VERSION "PropulsionCAN"

NS_ :

BS_ :

BU_ :  BECM CDD EGSM ETC IHU TMCU XCU ZCUD

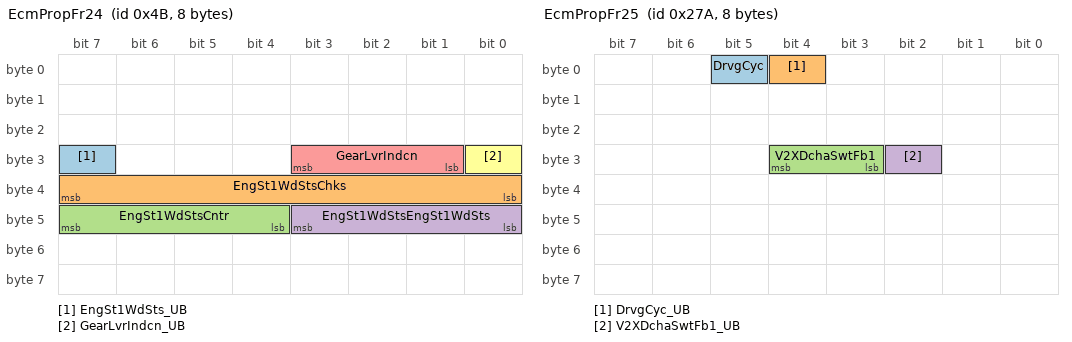
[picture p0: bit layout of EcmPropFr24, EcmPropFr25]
BO_ 75 EcmPropFr24 : 8 XCU
 SG_ EngSt1WdSts_UB : 31|1@0+ (1,0) [0|1] "" IHU,ZCUD
 SG_ EngSt1WdStsChks : 39|8@0+ (1.0,0.0) [0.0|255.0] "Unitless" IHU,ZCUD
 SG_ EngSt1WdStsCntr : 47|4@0+ (1.0,0.0) [0.0|15.0] "Unitless" IHU,ZCUD
 SG_ EngSt1WdStsEngSt1WdSts : 43|4@0+ (1,0) [0|15] "" IHU,ZCUD
 SG_ GearLvrIndcn : 27|3@0+ (1,0) [0|7] "" EGSM,IHU,ZCUD
 SG_ GearLvrIndcn_UB : 24|1@0+ (1,0) [0|1] "" EGSM,IHU,ZCUD

BO_ 634 EcmPropFr25 : 8 XCU
 SG_ DrvgCyc : 5|1@0+ (1,0) [0|1] "" CDD,IHU
 SG_ DrvgCyc_UB : 4|1@0+ (1,0) [0|1] "" CDD,IHU
 SG_ V2XDchaSwtFb1 : 28|2@0+ (1,0) [0|3] "" CDD,IHU
 SG_ V2XDchaSwtFb1_UB : 26|1@0+ (1,0) [0|1] "" CDD,IHU

BO_ 401 EcmPropFr28 : 8 XCU
 SG_ FrntHeatModEnad : 9|2@0+ (1,0) [0|3] "" IHU
 SG_ FrntHeatModEnad_UB : 12|1@0+ (1,0) [0|1] "" IHU

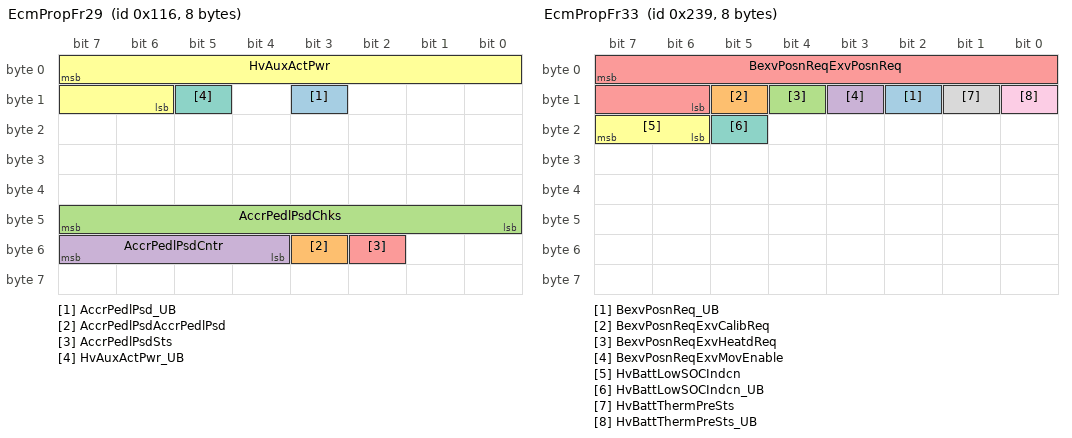
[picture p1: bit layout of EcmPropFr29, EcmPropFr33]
BO_ 278 EcmPropFr29 : 8 XCU
 SG_ AccrPedlPsd_UB : 11|1@0+ (1,0) [0|1] "" IHU,ZCUD
 SG_ AccrPedlPsdAccrPedlPsd : 51|1@0+ (1,0) [0|1] "" IHU,ZCUD
 SG_ AccrPedlPsdChks : 47|8@0+ (1.0,0.0) [0.0|255.0] "Unitless" IHU,ZCUD
 SG_ AccrPedlPsdCntr : 55|4@0+ (1.0,0.0) [0.0|15.0] "Unitless" IHU,ZCUD
 SG_ AccrPedlPsdSts : 50|1@0+ (1,0) [0|1] "" IHU,ZCUD
 SG_ HvAuxActPwr : 7|10@0+ (20.0,0.0) [0.0|20460.0] "W" IHU
 SG_ HvAuxActPwr_UB : 13|1@0+ (1,0) [0|1] "" IHU

BO_ 569 EcmPropFr33 : 8 XCU
 SG_ BexvPosnReq_UB : 10|1@0+ (1,0) [0|1] "" IHU,TMCU
 SG_ BexvPosnReqExvCalibReq : 13|1@0+ (1,0) [0|1] "" IHU,TMCU
 SG_ BexvPosnReqExvHeatdReq : 12|1@0+ (1,0) [0|1] "" IHU,TMCU
 SG_ BexvPosnReqExvMovEnable : 11|1@0+ (1,0) [0|1] "" IHU,TMCU
 SG_ BexvPosnReqExvPosnReq : 7|10@0+ (0.2,0.0) [0.0|100.0] "%" IHU,TMCU
 SG_ HvBattLowSOCIndcn : 23|2@0+ (1,0) [0|3] "" IHU
 SG_ HvBattLowSOCIndcn_UB : 21|1@0+ (1,0) [0|1] "" IHU
 SG_ HvBattThermPreSts : 9|1@0+ (1,0) [0|1] "" IHU
 SG_ HvBattThermPreSts_UB : 8|1@0+ (1,0) [0|1] "" IHU

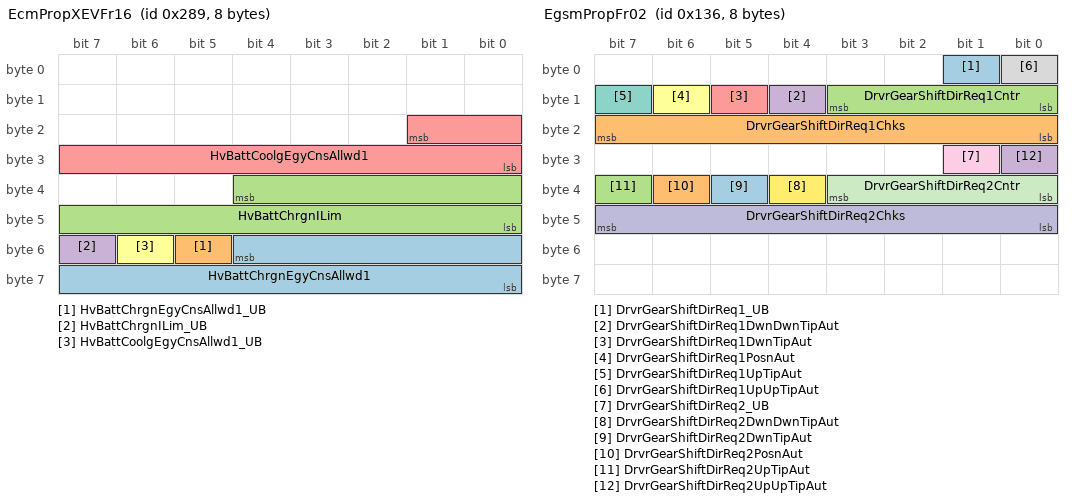
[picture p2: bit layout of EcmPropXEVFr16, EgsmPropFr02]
BO_ 649 EcmPropXEVFr16 : 8 XCU
 SG_ HvBattChrgnEgyCnsAllwd1 : 52|13@0+ (20.0,0.0) [0.0|163820.0] "Wh" IHU
 SG_ HvBattChrgnEgyCnsAllwd1_UB : 53|1@0+ (1,0) [0|1] "" IHU
 SG_ HvBattChrgnILim : 36|13@0+ (0.1,0.0) [0.0|819.1] "A" CDD
 SG_ HvBattChrgnILim_UB : 55|1@0+ (1,0) [0|1] "" CDD
 SG_ HvBattCoolgEgyCnsAllwd1 : 17|10@0+ (20.0,0.0) [0.0|20460.0] "Wh" IHU
 SG_ HvBattCoolgEgyCnsAllwd1_UB : 54|1@0+ (1,0) [0|1] "" IHU

BO_ 309 EgsmPropFr01 : 8 EGSM
 SG_ DrvrGearShiftManReq_UB : 7|1@0+ (1,0) [0|1] "" XCU
 SG_ DrvrGearShiftManReqDwnDwnTipReq : 0|1@0+ (1,0) [0|1] "" XCU
 SG_ DrvrGearShiftManReqDwnTipReq : 1|1@0+ (1,0) [0|1] "" XCU
 SG_ DrvrGearShiftManReqSteerWhlDwnReq1 : 2|1@0+ (1,0) [0|1] "" XCU
 SG_ DrvrGearShiftManReqSteerWhlUpReq : 3|1@0+ (1,0) [0|1] "" XCU
 SG_ DrvrGearShiftManReqTipReq1 : 4|1@0+ (1,0) [0|1] "" XCU
 SG_ DrvrGearShiftManReqUpTipReq1 : 5|1@0+ (1,0) [0|1] "" XCU
 SG_ DrvrGearShiftManReqUpUpTipReq : 6|1@0+ (1,0) [0|1] "" XCU
 SG_ DrvrGearShiftParkReq_UB : 15|1@0+ (1,0) [0|1] "" IHU,XCU,ZCUD
 SG_ DrvrGearShiftParkReq1 : 14|1@0+ (1,0) [0|1] "" IHU,XCU,ZCUD
 SG_ DrvrGearShiftParkReqChks : 23|8@0+ (1.0,0.0) [0.0|255.0] "Unitless" IHU,XCU,ZCUD
 SG_ DrvrGearShiftParkReqCntr : 11|4@0+ (1.0,0.0) [0.0|15.0] "Unitless" IHU,XCU,ZCUD
 SG_ DrvrGearShiftParkReqSts : 13|2@0+ (1,0) [0|3] "" IHU,XCU,ZCUD
 SG_ GearLock : 28|1@0+ (1,0) [0|1] "" IHU
 SG_ GearLock_UB : 29|1@0+ (1,0) [0|1] "" IHU
 SG_ GearShiftUnitSts : 26|3@0+ (1,0) [0|7] "" IHU,XCU,ZCUD
 SG_ GearShiftUnitSts_UB : 27|1@0+ (1,0) [0|1] "" IHU,XCU,ZCUD

BO_ 310 EgsmPropFr02 : 8 EGSM
 SG_ DrvrGearShiftDirReq1_UB : 1|1@0+ (1,0) [0|1] "" IHU,XCU,ZCUD
 SG_ DrvrGearShiftDirReq1Chks : 23|8@0+ (1.0,0.0) [0.0|255.0] "Unitless" IHU,XCU,ZCUD
 SG_ DrvrGearShiftDirReq1Cntr : 11|4@0+ (1.0,0.0) [0.0|15.0] "Unitless" IHU,XCU,ZCUD
 SG_ DrvrGearShiftDirReq1DwnDwnTipAut : 12|1@0+ (1,0) [0|1] "" IHU,XCU,ZCUD
 SG_ DrvrGearShiftDirReq1DwnTipAut : 13|1@0+ (1,0) [0|1] "" IHU,XCU,ZCUD
 SG_ DrvrGearShiftDirReq1PosnAut : 14|1@0+ (1,0) [0|1] "" IHU,XCU,ZCUD
 SG_ DrvrGearShiftDirReq1UpTipAut : 15|1@0+ (1,0) [0|1] "" IHU,XCU,ZCUD
 SG_ DrvrGearShiftDirReq1UpUpTipAut : 0|1@0+ (1,0) [0|1] "" IHU,XCU,ZCUD
 SG_ DrvrGearShiftDirReq2_UB : 25|1@0+ (1,0) [0|1] "" IHU,XCU,ZCUD
 SG_ DrvrGearShiftDirReq2Chks : 47|8@0+ (1.0,0.0) [0.0|255.0] "Unitless" IHU,XCU,ZCUD
 SG_ DrvrGearShiftDirReq2Cntr : 35|4@0+ (1.0,0.0) [0.0|15.0] "Unitless" IHU,XCU,ZCUD
 SG_ DrvrGearShiftDirReq2DwnDwnTipAut : 36|1@0+ (1,0) [0|1] "" IHU,XCU,ZCUD
 SG_ DrvrGearShiftDirReq2DwnTipAut : 37|1@0+ (1,0) [0|1] "" IHU,XCU,ZCUD
 SG_ DrvrGearShiftDirReq2PosnAut : 38|1@0+ (1,0) [0|1] "" IHU,XCU,ZCUD
 SG_ DrvrGearShiftDirReq2UpTipAut : 39|1@0+ (1,0) [0|1] "" IHU,XCU,ZCUD
 SG_ DrvrGearShiftDirReq2UpUpTipAut : 24|1@0+ (1,0) [0|1] "" IHU,XCU,ZCUD

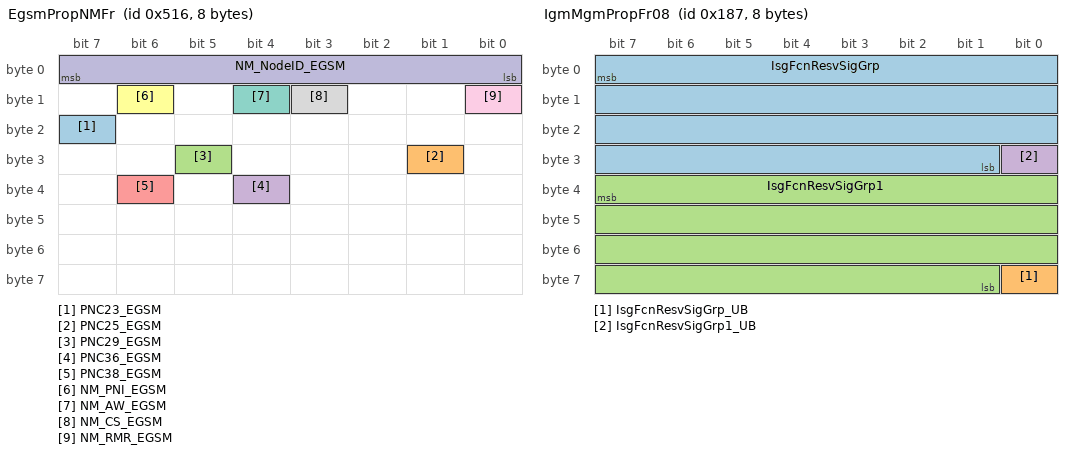
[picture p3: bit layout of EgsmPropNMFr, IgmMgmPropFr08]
BO_ 1302 EgsmPropNMFr : 8 EGSM
 SG_ PNC23_EGSM : 23|1@0+ (1,0) [0|0] "" Vector__XXX
 SG_ PNC25_EGSM : 25|1@0+ (1,0) [0|0] "" Vector__XXX
 SG_ PNC29_EGSM : 29|1@0+ (1,0) [0|0] "" Vector__XXX
 SG_ PNC36_EGSM : 36|1@0+ (1,0) [0|0] "" Vector__XXX
 SG_ PNC38_EGSM : 38|1@0+ (1,0) [0|0] "" Vector__XXX
 SG_ NM_PNI_EGSM : 14|1@0+ (1,0) [0|0] "" Vector__XXX
 SG_ NM_AW_EGSM : 12|1@0+ (1,0) [0|0] "" Vector__XXX
 SG_ NM_CS_EGSM : 11|1@0+ (1,0) [0|0] "" Vector__XXX
 SG_ NM_RMR_EGSM : 8|1@0+ (1,0) [0|0] "" Vector__XXX
 SG_ NM_NodeID_EGSM : 7|8@0+ (1,0) [0|0] "" Vector__XXX

BO_ 1366 EgsmPropVFCVectorFr : 8 EGSM
 SG_ VFCVectorEGSMBlockID : 1|2@0+ (1.0,0.0) [0.0|3.0] "Unitless" IHU
 SG_ VFCVectorEGSMVFCid0 : 2|1@0+ (1,0) [0|1] "" IHU
 SG_ VFCVectorEGSMVFCid1 : 3|1@0+ (1,0) [0|1] "" IHU
 SG_ VFCVectorEGSMVFCid10 : 12|1@0+ (1,0) [0|1] "" IHU
 SG_ VFCVectorEGSMVFCid11 : 13|1@0+ (1,0) [0|1] "" IHU
 SG_ VFCVectorEGSMVFCid12 : 14|1@0+ (1,0) [0|1] "" IHU
 SG_ VFCVectorEGSMVFCid13 : 15|1@0+ (1,0) [0|1] "" IHU
 SG_ VFCVectorEGSMVFCid14 : 16|1@0+ (1,0) [0|1] "" IHU
 SG_ VFCVectorEGSMVFCid15 : 17|1@0+ (1,0) [0|1] "" IHU
 SG_ VFCVectorEGSMVFCid16 : 18|1@0+ (1,0) [0|1] "" IHU
 SG_ VFCVectorEGSMVFCid17 : 19|1@0+ (1,0) [0|1] "" IHU
 SG_ VFCVectorEGSMVFCid18 : 20|1@0+ (1,0) [0|1] "" IHU
 SG_ VFCVectorEGSMVFCid19 : 21|1@0+ (1,0) [0|1] "" IHU
 SG_ VFCVectorEGSMVFCid2 : 4|1@0+ (1,0) [0|1] "" IHU
 SG_ VFCVectorEGSMVFCid20 : 22|1@0+ (1,0) [0|1] "" IHU
 SG_ VFCVectorEGSMVFCid21 : 23|1@0+ (1,0) [0|1] "" IHU
 SG_ VFCVectorEGSMVFCid22 : 24|1@0+ (1,0) [0|1] "" IHU
 SG_ VFCVectorEGSMVFCid23 : 25|1@0+ (1,0) [0|1] "" IHU
 SG_ VFCVectorEGSMVFCid24 : 26|1@0+ (1,0) [0|1] "" IHU
 SG_ VFCVectorEGSMVFCid25 : 27|1@0+ (1,0) [0|1] "" IHU
 SG_ VFCVectorEGSMVFCid26 : 28|1@0+ (1,0) [0|1] "" IHU
 SG_ VFCVectorEGSMVFCid27 : 29|1@0+ (1,0) [0|1] "" IHU
 SG_ VFCVectorEGSMVFCid28 : 30|1@0+ (1,0) [0|1] "" IHU
 SG_ VFCVectorEGSMVFCid29 : 31|1@0+ (1,0) [0|1] "" IHU
 SG_ VFCVectorEGSMVFCid3 : 5|1@0+ (1,0) [0|1] "" IHU
 SG_ VFCVectorEGSMVFCid30 : 32|1@0+ (1,0) [0|1] "" IHU
 SG_ VFCVectorEGSMVFCid31 : 33|1@0+ (1,0) [0|1] "" IHU
 SG_ VFCVectorEGSMVFCid32 : 34|1@0+ (1,0) [0|1] "" IHU
 SG_ VFCVectorEGSMVFCid33 : 35|1@0+ (1,0) [0|1] "" IHU
 SG_ VFCVectorEGSMVFCid34 : 36|1@0+ (1,0) [0|1] "" IHU
 SG_ VFCVectorEGSMVFCid35 : 37|1@0+ (1,0) [0|1] "" IHU
 SG_ VFCVectorEGSMVFCid36 : 38|1@0+ (1,0) [0|1] "" IHU
 SG_ VFCVectorEGSMVFCid37 : 39|1@0+ (1,0) [0|1] "" IHU
 SG_ VFCVectorEGSMVFCid38 : 40|1@0+ (1,0) [0|1] "" IHU
 SG_ VFCVectorEGSMVFCid39 : 41|1@0+ (1,0) [0|1] "" IHU
 SG_ VFCVectorEGSMVFCid4 : 6|1@0+ (1,0) [0|1] "" IHU
 SG_ VFCVectorEGSMVFCid40 : 42|1@0+ (1,0) [0|1] "" IHU
 SG_ VFCVectorEGSMVFCid41 : 43|1@0+ (1,0) [0|1] "" IHU
 SG_ VFCVectorEGSMVFCid42 : 44|1@0+ (1,0) [0|1] "" IHU
 SG_ VFCVectorEGSMVFCid43 : 45|1@0+ (1,0) [0|1] "" IHU
 SG_ VFCVectorEGSMVFCid44 : 46|1@0+ (1,0) [0|1] "" IHU
 SG_ VFCVectorEGSMVFCid45 : 47|1@0+ (1,0) [0|1] "" IHU
 SG_ VFCVectorEGSMVFCid46 : 48|1@0+ (1,0) [0|1] "" IHU
 SG_ VFCVectorEGSMVFCid47 : 49|1@0+ (1,0) [0|1] "" IHU
 SG_ VFCVectorEGSMVFCid48 : 50|1@0+ (1,0) [0|1] "" IHU
 SG_ VFCVectorEGSMVFCid49 : 51|1@0+ (1,0) [0|1] "" IHU
 SG_ VFCVectorEGSMVFCid5 : 7|1@0+ (1,0) [0|1] "" IHU
 SG_ VFCVectorEGSMVFCid50 : 52|1@0+ (1,0) [0|1] "" IHU
 SG_ VFCVectorEGSMVFCid51 : 53|1@0+ (1,0) [0|1] "" IHU
 SG_ VFCVectorEGSMVFCid52 : 54|1@0+ (1,0) [0|1] "" IHU
 SG_ VFCVectorEGSMVFCid53 : 55|1@0+ (1,0) [0|1] "" IHU
 SG_ VFCVectorEGSMVFCid54 : 56|1@0+ (1,0) [0|1] "" IHU
 SG_ VFCVectorEGSMVFCid55 : 57|1@0+ (1,0) [0|1] "" IHU
 SG_ VFCVectorEGSMVFCid56 : 58|1@0+ (1,0) [0|1] "" IHU
 SG_ VFCVectorEGSMVFCid57 : 59|1@0+ (1,0) [0|1] "" IHU
 SG_ VFCVectorEGSMVFCid58 : 60|1@0+ (1,0) [0|1] "" IHU
 SG_ VFCVectorEGSMVFCid59 : 61|1@0+ (1,0) [0|1] "" IHU
 SG_ VFCVectorEGSMVFCid6 : 8|1@0+ (1,0) [0|1] "" IHU
 SG_ VFCVectorEGSMVFCid60 : 62|1@0+ (1,0) [0|1] "" IHU
 SG_ VFCVectorEGSMVFCid61 : 63|1@0+ (1,0) [0|1] "" IHU
 SG_ VFCVectorEGSMVFCid7 : 9|1@0+ (1,0) [0|1] "" IHU
 SG_ VFCVectorEGSMVFCid8 : 10|1@0+ (1,0) [0|1] "" IHU
 SG_ VFCVectorEGSMVFCid9 : 11|1@0+ (1,0) [0|1] "" IHU

BO_ 1587 EgsmToVddmPropDiagResFrame : 8 EGSM

BO_ 1410 EtctoCddXCPFr01 : 8 ETC

BO_ 1448 ETCtoDEMXCPFr01 : 8 ETC

BO_ 1447 ETCtoDEMXCPFr02 : 8 ETC

BO_ 1449 ETCtoDEMXCPFr03 : 8 ETC

BO_ 1450 ETCtoDEMXCPFr04 : 8 ETC

BO_ 1451 ETCtoDEMXCPFr05 : 8 ETC

BO_ 1452 ETCtoDEMXCPFr06 : 8 ETC

BO_ 1412 EtctoEcmXCPFr01 : 8 ETC

BO_ 1418 EtctoIgsmXCPFr01 : 8 ETC

BO_ 314 IgmMgmPropFr03 : 8 XCU
 SG_ IsgCooltT : 47|8@0+ (1.0,-40.0) [-40.0|215.0] "degC" IHU
 SG_ IsgCooltT_UB : 55|1@0+ (1,0) [0|1] "" IHU

BO_ 342 IgmMgmPropFr05 : 8 XCU
 SG_ IsgUDc : 2|11@0+ (0.25,0.0) [0.0|511.0] "Volt" IHU
 SG_ IsgUDc_UB : 3|1@0+ (1,0) [0|1] "" IHU

BO_ 149 IgmMgmPropFr06 : 8 XCU
 SG_ IsgModSts : 38|4@0+ (1,0) [0|15] "" IHU
 SG_ IsgModSts_UB : 39|1@0+ (1,0) [0|1] "" IHU

BO_ 391 IgmMgmPropFr08 : 8 XCU
 SG_ IsgFcnResvSigGrp : 7|31@0+ (1.0,0.0) [0.0|9223372036854776000.0] "Unitless" CDD
 SG_ IsgFcnResvSigGrp_UB : 56|1@0+ (1,0) [0|1] "" CDD
 SG_ IsgFcnResvSigGrp1 : 39|31@0+ (1.0,0.0) [0.0|9223372036854776000.0] "Unitless" CDD
 SG_ IsgFcnResvSigGrp1_UB : 24|1@0+ (1,0) [0|1] "" CDD

BO_ 593 IhuPropFr01 : 8 IHU
 SG_ HmiSteerWhlHeatLvlReq : 7|3@0+ (1,0) [0|7] "" ZCUD
 SG_ HmiSteerWhlHeatLvlReq_UB : 4|1@0+ (1,0) [0|1] "" ZCUD

BO_ 299 MgmPropdTCFr09 : 8 XCU
 SG_ LimdPwrPerc : 55|11@0- (0.1,0.0) [-100.0|102.30000000000001] "%" IHU
 SG_ LimdPwrPerc_UB : 57|1@0+ (1,0) [0|1] "" IHU

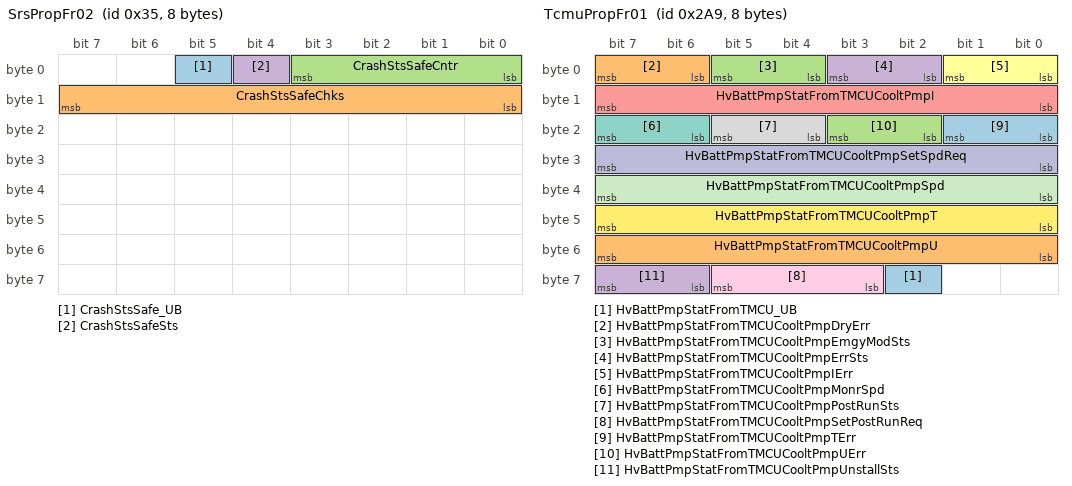
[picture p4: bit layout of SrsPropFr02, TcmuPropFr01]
BO_ 53 SrsPropFr02 : 8 ZCUD
 SG_ CrashStsSafe_UB : 5|1@0+ (1,0) [0|1] "" CDD,IHU,XCU
 SG_ CrashStsSafeChks : 15|8@0+ (1.0,0.0) [0.0|255.0] "Unitless" CDD,IHU,XCU
 SG_ CrashStsSafeCntr : 3|4@0+ (1.0,0.0) [0.0|15.0] "Unitless" CDD,IHU,XCU
 SG_ CrashStsSafeSts : 4|1@0+ (1,0) [0|1] "" CDD,IHU,XCU

BO_ 681 TcmuPropFr01 : 8 TMCU
 SG_ HvBattPmpStatFromTMCU_UB : 58|1@0+ (1,0) [0|1] "" XCU
 SG_ HvBattPmpStatFromTMCUCooltPmpDryErr : 7|2@0+ (1,0) [0|3] "" XCU
 SG_ HvBattPmpStatFromTMCUCooltPmpEmgyModSts : 5|2@0+ (1,0) [0|3] "" XCU
 SG_ HvBattPmpStatFromTMCUCooltPmpErrSts : 3|2@0+ (1,0) [0|3] "" XCU
 SG_ HvBattPmpStatFromTMCUCooltPmpI : 15|8@0+ (0.2,0.0) [0.0|50.800000000000004] "A" XCU
 SG_ HvBattPmpStatFromTMCUCooltPmpIErr : 1|2@0+ (1,0) [0|3] "" XCU
 SG_ HvBattPmpStatFromTMCUCooltPmpMonrSpd : 23|2@0+ (1,0) [0|3] "" XCU
 SG_ HvBattPmpStatFromTMCUCooltPmpPostRunSts : 21|2@0+ (1,0) [0|3] "" XCU
 SG_ HvBattPmpStatFromTMCUCooltPmpSetPostRunReq : 61|3@0+ (1,0) [0|7] "" XCU
 SG_ HvBattPmpStatFromTMCUCooltPmpSetSpdReq : 31|8@0+ (1.0,0.0) [0.0|254.0] "Unitless" XCU
 SG_ HvBattPmpStatFromTMCUCooltPmpSpd : 39|8@0+ (1.0,0.0) [0.0|254.0] "Unitless" XCU
 SG_ HvBattPmpStatFromTMCUCooltPmpT : 47|8@0+ (1.0,-50.0) [-50.0|200.0] "degC" XCU
 SG_ HvBattPmpStatFromTMCUCooltPmpTErr : 17|2@0+ (1,0) [0|3] "" XCU
 SG_ HvBattPmpStatFromTMCUCooltPmpU : 55|8@0+ (0.1,0.0) [0.0|25.0] "Volt" XCU
 SG_ HvBattPmpStatFromTMCUCooltPmpUErr : 19|2@0+ (1,0) [0|3] "" XCU
 SG_ HvBattPmpStatFromTMCUCooltPmpUnstallSts : 63|2@0+ (1,0) [0|3] "" XCU

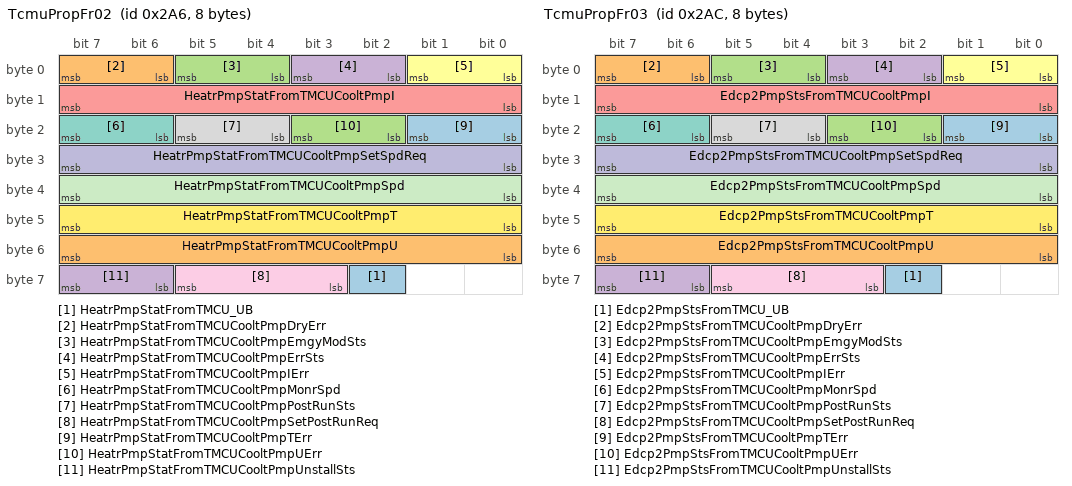
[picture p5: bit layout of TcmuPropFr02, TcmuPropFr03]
BO_ 678 TcmuPropFr02 : 8 TMCU
 SG_ HeatrPmpStatFromTMCU_UB : 58|1@0+ (1,0) [0|1] "" XCU
 SG_ HeatrPmpStatFromTMCUCooltPmpDryErr : 7|2@0+ (1,0) [0|3] "" XCU
 SG_ HeatrPmpStatFromTMCUCooltPmpEmgyModSts : 5|2@0+ (1,0) [0|3] "" XCU
 SG_ HeatrPmpStatFromTMCUCooltPmpErrSts : 3|2@0+ (1,0) [0|3] "" XCU
 SG_ HeatrPmpStatFromTMCUCooltPmpI : 15|8@0+ (0.2,0.0) [0.0|50.800000000000004] "A" XCU
 SG_ HeatrPmpStatFromTMCUCooltPmpIErr : 1|2@0+ (1,0) [0|3] "" XCU
 SG_ HeatrPmpStatFromTMCUCooltPmpMonrSpd : 23|2@0+ (1,0) [0|3] "" XCU
 SG_ HeatrPmpStatFromTMCUCooltPmpPostRunSts : 21|2@0+ (1,0) [0|3] "" XCU
 SG_ HeatrPmpStatFromTMCUCooltPmpSetPostRunReq : 61|3@0+ (1,0) [0|7] "" XCU
 SG_ HeatrPmpStatFromTMCUCooltPmpSetSpdReq : 31|8@0+ (1.0,0.0) [0.0|254.0] "Unitless" XCU
 SG_ HeatrPmpStatFromTMCUCooltPmpSpd : 39|8@0+ (1.0,0.0) [0.0|254.0] "Unitless" XCU
 SG_ HeatrPmpStatFromTMCUCooltPmpT : 47|8@0+ (1.0,-50.0) [-50.0|200.0] "degC" XCU
 SG_ HeatrPmpStatFromTMCUCooltPmpTErr : 17|2@0+ (1,0) [0|3] "" XCU
 SG_ HeatrPmpStatFromTMCUCooltPmpU : 55|8@0+ (0.1,0.0) [0.0|25.0] "Volt" XCU
 SG_ HeatrPmpStatFromTMCUCooltPmpUErr : 19|2@0+ (1,0) [0|3] "" XCU
 SG_ HeatrPmpStatFromTMCUCooltPmpUnstallSts : 63|2@0+ (1,0) [0|3] "" XCU

BO_ 684 TcmuPropFr03 : 8 TMCU
 SG_ Edcp2PmpStsFromTMCU_UB : 58|1@0+ (1,0) [0|1] "" XCU
 SG_ Edcp2PmpStsFromTMCUCooltPmpDryErr : 7|2@0+ (1,0) [0|3] "" XCU
 SG_ Edcp2PmpStsFromTMCUCooltPmpEmgyModSts : 5|2@0+ (1,0) [0|3] "" XCU
 SG_ Edcp2PmpStsFromTMCUCooltPmpErrSts : 3|2@0+ (1,0) [0|3] "" XCU
 SG_ Edcp2PmpStsFromTMCUCooltPmpI : 15|8@0+ (0.2,0.0) [0.0|50.800000000000004] "A" XCU
 SG_ Edcp2PmpStsFromTMCUCooltPmpIErr : 1|2@0+ (1,0) [0|3] "" XCU
 SG_ Edcp2PmpStsFromTMCUCooltPmpMonrSpd : 23|2@0+ (1,0) [0|3] "" XCU
 SG_ Edcp2PmpStsFromTMCUCooltPmpPostRunSts : 21|2@0+ (1,0) [0|3] "" XCU
 SG_ Edcp2PmpStsFromTMCUCooltPmpSetPostRunReq : 61|3@0+ (1,0) [0|7] "" XCU
 SG_ Edcp2PmpStsFromTMCUCooltPmpSetSpdReq : 31|8@0+ (1.0,0.0) [0.0|254.0] "Unitless" XCU
 SG_ Edcp2PmpStsFromTMCUCooltPmpSpd : 39|8@0+ (1.0,0.0) [0.0|254.0] "Unitless" XCU
 SG_ Edcp2PmpStsFromTMCUCooltPmpT : 47|8@0+ (1.0,-50.0) [-50.0|200.0] "degC" XCU
 SG_ Edcp2PmpStsFromTMCUCooltPmpTErr : 17|2@0+ (1,0) [0|3] "" XCU
 SG_ Edcp2PmpStsFromTMCUCooltPmpU : 55|8@0+ (0.1,0.0) [0.0|25.0] "Volt" XCU
 SG_ Edcp2PmpStsFromTMCUCooltPmpUErr : 19|2@0+ (1,0) [0|3] "" XCU
 SG_ Edcp2PmpStsFromTMCUCooltPmpUnstallSts : 63|2@0+ (1,0) [0|3] "" XCU

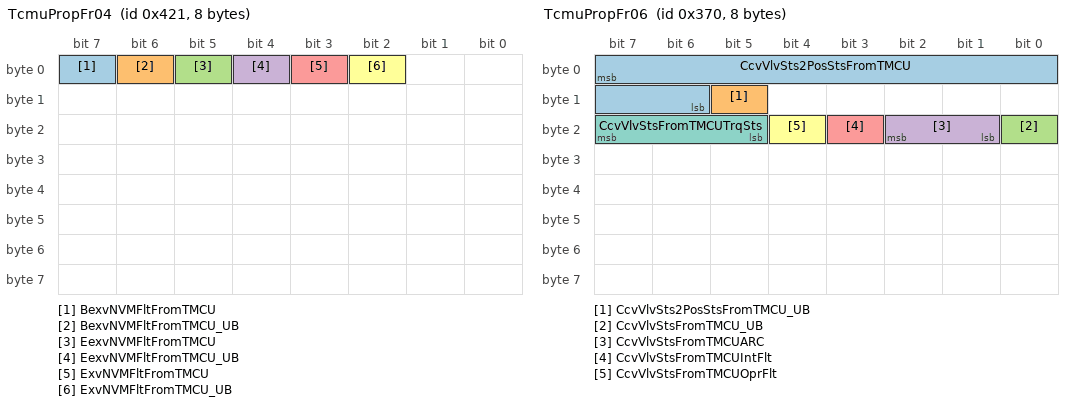
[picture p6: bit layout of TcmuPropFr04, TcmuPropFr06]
BO_ 1057 TcmuPropFr04 : 8 TMCU
 SG_ BexvNVMFltFromTMCU : 7|1@0+ (1,0) [0|1] "" XCU
 SG_ BexvNVMFltFromTMCU_UB : 6|1@0+ (1,0) [0|1] "" XCU
 SG_ EexvNVMFltFromTMCU : 5|1@0+ (1,0) [0|1] "" XCU
 SG_ EexvNVMFltFromTMCU_UB : 4|1@0+ (1,0) [0|1] "" XCU
 SG_ ExvNVMFltFromTMCU : 3|1@0+ (1,0) [0|1] "" XCU
 SG_ ExvNVMFltFromTMCU_UB : 2|1@0+ (1,0) [0|1] "" XCU

BO_ 869 TcmuPropFr05 : 8 TMCU
 SG_ CcvmStsFromTMCU_UB : 25|1@0+ (1,0) [0|1] "" XCU
 SG_ CcvmStsFromTMCUVlvBlkFlt : 7|1@0+ (1,0) [0|1] "" XCU
 SG_ CcvmStsFromTMCUVlvCalibSts : 6|2@0+ (1,0) [0|3] "" XCU
 SG_ CcvmStsFromTMCUVlvCmdPosnErr : 4|1@0+ (1,0) [0|1] "" XCU
 SG_ CcvmStsFromTMCUVlvLoTErr : 3|1@0+ (1,0) [0|1] "" XCU
 SG_ CcvmStsFromTMCUVlvMoveSts : 2|1@0+ (1,0) [0|1] "" XCU
 SG_ CcvmStsFromTMCUVlvNVMFlt : 1|1@0+ (1,0) [0|1] "" XCU
 SG_ CcvmStsFromTMCUVlvOpenCircFlt : 0|1@0+ (1,0) [0|1] "" XCU
 SG_ CcvmStsFromTMCUVlvOverTErr : 15|1@0+ (1,0) [0|1] "" XCU
 SG_ CcvmStsFromTMCUVlvOverTrvlFlt : 14|1@0+ (1,0) [0|1] "" XCU
 SG_ CcvmStsFromTMCUVlvOverTWarn : 13|1@0+ (1,0) [0|1] "" XCU
 SG_ CcvmStsFromTMCUVlvOverUErr : 12|1@0+ (1,0) [0|1] "" XCU
 SG_ CcvmStsFromTMCUVlvPosn : 9|10@0+ (0.1,0.0) [0.0|100.0] "%" XCU
 SG_ CcvmStsFromTMCUVlvPosnCtrlTimeOutFlt : 11|1@0+ (1,0) [0|1] "" XCU
 SG_ CcvmStsFromTMCUVlvPosnUkwnFlt : 10|1@0+ (1,0) [0|1] "" XCU
 SG_ CcvmStsFromTMCUVlvPreHeatgSts : 31|1@0+ (1,0) [0|1] "" XCU
 SG_ CcvmStsFromTMCUVlvSelfLearnFlt : 30|1@0+ (1,0) [0|1] "" XCU
 SG_ CcvmStsFromTMCUVlvShoCircFlt : 29|1@0+ (1,0) [0|1] "" XCU
 SG_ CcvmStsFromTMCUVlvSpdLvlSts : 28|2@0+ (1,0) [0|3] "" XCU
 SG_ CcvmStsFromTMCUVlvUnderUErr : 26|1@0+ (1,0) [0|1] "" XCU

BO_ 880 TcmuPropFr06 : 8 TMCU
 SG_ CcvVlvSts2PosStsFromTMCU : 7|10@0+ (0.26367188,-45.0) [-45.0|224.73633324000002] "Unitless" XCU
 SG_ CcvVlvSts2PosStsFromTMCU_UB : 13|1@0+ (1,0) [0|1] "" XCU
 SG_ CcvVlvStsFromTMCU_UB : 16|1@0+ (1,0) [0|1] "" XCU
 SG_ CcvVlvStsFromTMCUARC : 18|2@0+ (1.0,0.0) [0.0|3.0] "Unitless" XCU
 SG_ CcvVlvStsFromTMCUIntFlt : 19|1@0+ (1,0) [0|1] "" XCU
 SG_ CcvVlvStsFromTMCUOprFlt : 20|1@0+ (1,0) [0|1] "" XCU
 SG_ CcvVlvStsFromTMCUTrqSts : 23|3@0+ (1,0) [0|7] "" XCU

BO_ 672 TcmuPropFr07 : 8 TMCU
 SG_ BexvStsFromTMCU_UB : 17|1@0+ (1,0) [0|1] "" XCU
 SG_ BexvStsFromTMCUExvActrPosn : 7|10@0+ (0.2,0.0) [0.0|100.0] "%" XCU
 SG_ BexvStsFromTMCUExvBlkErr : 13|1@0+ (1,0) [0|1] "" XCU
 SG_ BexvStsFromTMCUExvCalibSts : 12|2@0+ (1,0) [0|3] "" XCU
 SG_ BexvStsFromTMCUExvElecStsErr : 10|3@0+ (1,0) [0|7] "" XCU
 SG_ BexvStsFromTMCUExvMovSts : 23|1@0+ (1,0) [0|1] "" XCU
 SG_ BexvStsFromTMCUExvOvrTempErr : 22|1@0+ (1,0) [0|1] "" XCU
 SG_ BexvStsFromTMCUExvOvrTrvlErr : 21|1@0+ (1,0) [0|1] "" XCU
 SG_ BexvStsFromTMCUExvPreHeatgSts : 20|1@0+ (1,0) [0|1] "" XCU
 SG_ BexvStsFromTMCUExvVoltgRangErr : 19|2@0+ (1,0) [0|3] "" XCU
 SG_ EexvStsFromTMCU_UB : 41|1@0+ (1,0) [0|1] "" XCU
 SG_ EexvStsFromTMCUExvActrPosn : 31|10@0+ (0.2,0.0) [0.0|100.0] "%" XCU
 SG_ EexvStsFromTMCUExvBlkErr : 37|1@0+ (1,0) [0|1] "" XCU
 SG_ EexvStsFromTMCUExvCalibSts : 36|2@0+ (1,0) [0|3] "" XCU
 SG_ EexvStsFromTMCUExvElecStsErr : 34|3@0+ (1,0) [0|7] "" XCU
 SG_ EexvStsFromTMCUExvMovSts : 47|1@0+ (1,0) [0|1] "" XCU
 SG_ EexvStsFromTMCUExvOvrTempErr : 46|1@0+ (1,0) [0|1] "" XCU
 SG_ EexvStsFromTMCUExvOvrTrvlErr : 45|1@0+ (1,0) [0|1] "" XCU
 SG_ EexvStsFromTMCUExvPreHeatgSts : 44|1@0+ (1,0) [0|1] "" XCU
 SG_ EexvStsFromTMCUExvVoltgRangErr : 43|2@0+ (1,0) [0|3] "" XCU

BO_ 675 TcmuPropFr08 : 8 TMCU
 SG_ ExvStsFromTMCU_UB : 17|1@0+ (1,0) [0|1] "" XCU
 SG_ ExvStsFromTMCUExvActrPosn : 7|10@0+ (0.2,0.0) [0.0|100.0] "%" XCU
 SG_ ExvStsFromTMCUExvBlkErr : 13|1@0+ (1,0) [0|1] "" XCU
 SG_ ExvStsFromTMCUExvCalibSts : 12|2@0+ (1,0) [0|3] "" XCU
 SG_ ExvStsFromTMCUExvElecStsErr : 10|3@0+ (1,0) [0|7] "" XCU
 SG_ ExvStsFromTMCUExvMovSts : 23|1@0+ (1,0) [0|1] "" XCU
 SG_ ExvStsFromTMCUExvOvrTempErr : 22|1@0+ (1,0) [0|1] "" XCU
 SG_ ExvStsFromTMCUExvOvrTrvlErr : 21|1@0+ (1,0) [0|1] "" XCU
 SG_ ExvStsFromTMCUExvPreHeatgSts : 20|1@0+ (1,0) [0|1] "" XCU
 SG_ ExvStsFromTMCUExvVoltgRangErr : 19|2@0+ (1,0) [0|3] "" XCU
 SG_ HctvStsFromTMCU_UB : 16|1@0+ (1,0) [0|1] "" XCU
 SG_ HctvStsFromTMCUVlvBlkFlt : 31|1@0+ (1,0) [0|1] "" XCU
 SG_ HctvStsFromTMCUVlvCalibSts : 30|2@0+ (1,0) [0|3] "" XCU
 SG_ HctvStsFromTMCUVlvCmdPosnErr : 28|1@0+ (1,0) [0|1] "" XCU
 SG_ HctvStsFromTMCUVlvLoTErr : 27|1@0+ (1,0) [0|1] "" XCU
 SG_ HctvStsFromTMCUVlvMoveSts : 26|1@0+ (1,0) [0|1] "" XCU
 SG_ HctvStsFromTMCUVlvNVMFlt : 25|1@0+ (1,0) [0|1] "" XCU
 SG_ HctvStsFromTMCUVlvOpenCircFlt : 24|1@0+ (1,0) [0|1] "" XCU
 SG_ HctvStsFromTMCUVlvOverTErr : 39|1@0+ (1,0) [0|1] "" XCU
 SG_ HctvStsFromTMCUVlvOverTrvlFlt : 38|1@0+ (1,0) [0|1] "" XCU
 SG_ HctvStsFromTMCUVlvOverTWarn : 37|1@0+ (1,0) [0|1] "" XCU
 SG_ HctvStsFromTMCUVlvOverUErr : 36|1@0+ (1,0) [0|1] "" XCU
 SG_ HctvStsFromTMCUVlvPosn : 33|10@0+ (0.1,0.0) [0.0|100.0] "%" XCU
 SG_ HctvStsFromTMCUVlvPosnCtrlTimeOutFlt : 35|1@0+ (1,0) [0|1] "" XCU
 SG_ HctvStsFromTMCUVlvPosnUkwnFlt : 34|1@0+ (1,0) [0|1] "" XCU
 SG_ HctvStsFromTMCUVlvPreHeatgSts : 55|1@0+ (1,0) [0|1] "" XCU
 SG_ HctvStsFromTMCUVlvSelfLearnFlt : 54|1@0+ (1,0) [0|1] "" XCU
 SG_ HctvStsFromTMCUVlvShoCircFlt : 53|1@0+ (1,0) [0|1] "" XCU
 SG_ HctvStsFromTMCUVlvSpdLvlSts : 51|2@0+ (1,0) [0|3] "" XCU
 SG_ HctvStsFromTMCUVlvUnderUErr : 52|1@0+ (1,0) [0|1] "" XCU

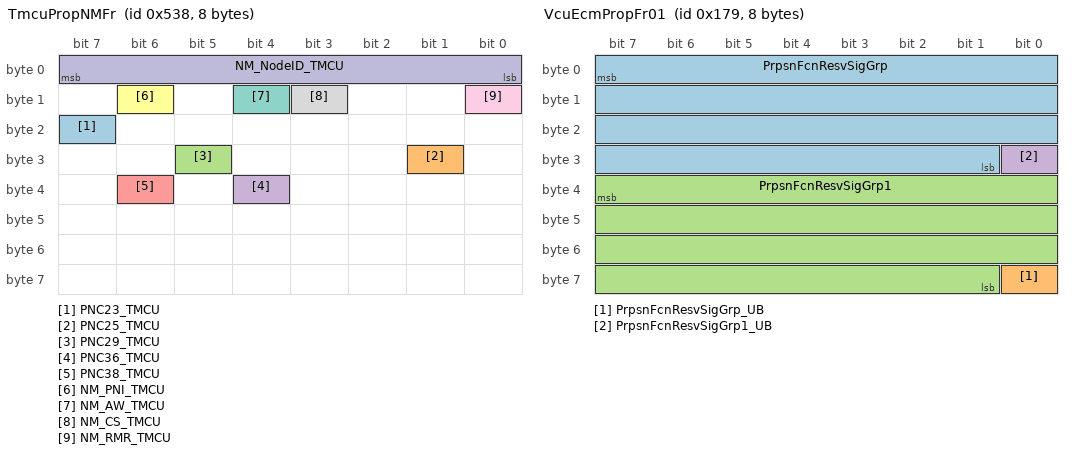
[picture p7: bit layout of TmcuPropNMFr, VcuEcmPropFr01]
BO_ 1336 TmcuPropNMFr : 8 TMCU
 SG_ PNC23_TMCU : 23|1@0+ (1,0) [0|0] "" Vector__XXX
 SG_ PNC25_TMCU : 25|1@0+ (1,0) [0|0] "" Vector__XXX
 SG_ PNC29_TMCU : 29|1@0+ (1,0) [0|0] "" Vector__XXX
 SG_ PNC36_TMCU : 36|1@0+ (1,0) [0|0] "" Vector__XXX
 SG_ PNC38_TMCU : 38|1@0+ (1,0) [0|0] "" Vector__XXX
 SG_ NM_PNI_TMCU : 14|1@0+ (1,0) [0|0] "" Vector__XXX
 SG_ NM_AW_TMCU : 12|1@0+ (1,0) [0|0] "" Vector__XXX
 SG_ NM_CS_TMCU : 11|1@0+ (1,0) [0|0] "" Vector__XXX
 SG_ NM_RMR_TMCU : 8|1@0+ (1,0) [0|0] "" Vector__XXX
 SG_ NM_NodeID_TMCU : 7|8@0+ (1,0) [0|0] "" Vector__XXX

BO_ 1595 TmcuToDhuPropDiagResFr : 8 TMCU

BO_ 1770 UudtEgsmFr01 : 8 EGSM

BO_ 1771 UudtEgsmFr02 : 8 EGSM

BO_ 377 VcuEcmPropFr01 : 8 XCU
 SG_ PrpsnFcnResvSigGrp : 7|31@0+ (1.0,0.0) [0.0|9223372036854776000.0] "Unitless" CDD
 SG_ PrpsnFcnResvSigGrp_UB : 56|1@0+ (1,0) [0|1] "" CDD
 SG_ PrpsnFcnResvSigGrp1 : 39|31@0+ (1.0,0.0) [0.0|9223372036854776000.0] "Unitless" CDD
 SG_ PrpsnFcnResvSigGrp1_UB : 24|1@0+ (1,0) [0|1] "" CDD

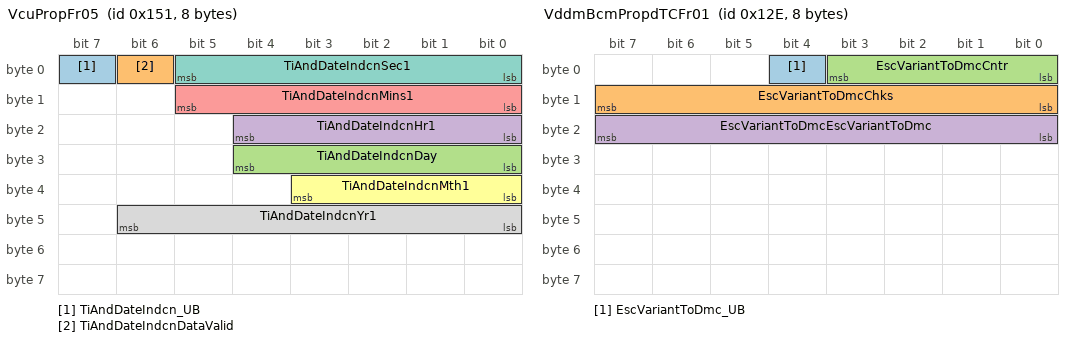
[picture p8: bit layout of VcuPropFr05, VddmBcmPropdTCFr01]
BO_ 337 VcuPropFr05 : 8 XCU
 SG_ TiAndDateIndcn_UB : 7|1@0+ (1,0) [0|1] "" BECM,CDD,EGSM,TMCU
 SG_ TiAndDateIndcnDataValid : 6|1@0+ (1,0) [0|1] "" BECM,CDD,EGSM,TMCU
 SG_ TiAndDateIndcnDay : 28|5@0+ (1.0,0.0) [1.0|31.0] "Days" BECM,CDD,EGSM,TMCU
 SG_ TiAndDateIndcnHr1 : 20|5@0+ (1.0,0.0) [0.0|23.0] "hours" BECM,CDD,EGSM,TMCU
 SG_ TiAndDateIndcnMins1 : 13|6@0+ (1.0,0.0) [0.0|59.0] "Mins" BECM,CDD,EGSM,TMCU
 SG_ TiAndDateIndcnMth1 : 35|4@0+ (1.0,0.0) [1.0|12.0] "Month" BECM,CDD,EGSM,TMCU
 SG_ TiAndDateIndcnSec1 : 5|6@0+ (1.0,0.0) [0.0|59.0] "s" BECM,CDD,EGSM,TMCU
 SG_ TiAndDateIndcnYr1 : 46|7@0+ (1.0,0.0) [0.0|99.0] "Year" BECM,CDD,EGSM,TMCU

BO_ 302 VddmBcmPropdTCFr01 : 8 ZCUD
 SG_ EscVariantToDmc_UB : 4|1@0+ (1,0) [0|1] "" XCU
 SG_ EscVariantToDmcChks : 15|8@0+ (1.0,0.0) [0.0|255.0] "Unitless" XCU
 SG_ EscVariantToDmcCntr : 3|4@0+ (1.0,0.0) [0.0|15.0] "Unitless" XCU
 SG_ EscVariantToDmcEscVariantToDmc : 23|8@0+ (1.0,0.0) [0.0|255.0] "Unitless" XCU

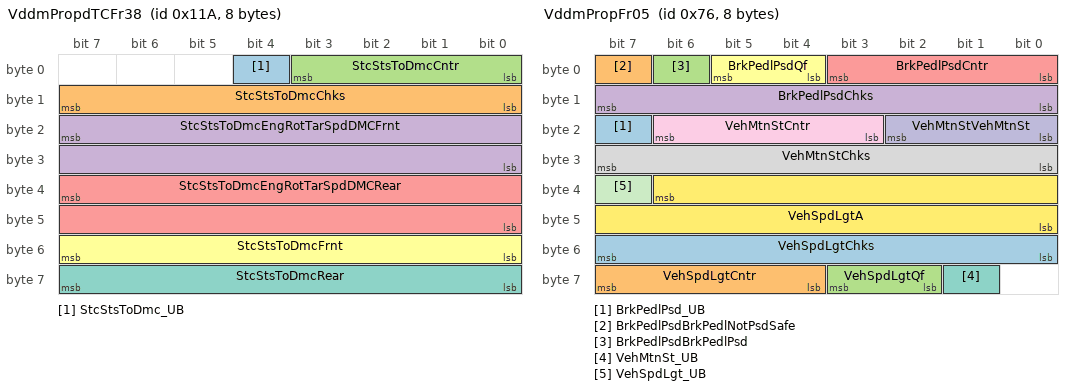
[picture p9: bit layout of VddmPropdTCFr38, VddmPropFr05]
BO_ 282 VddmPropdTCFr38 : 8 ZCUD
 SG_ StcStsToDmc_UB : 4|1@0+ (1,0) [0|1] "" XCU
 SG_ StcStsToDmcChks : 15|8@0+ (1.0,0.0) [0.0|255.0] "Unitless" XCU
 SG_ StcStsToDmcCntr : 3|4@0+ (1.0,0.0) [0.0|15.0] "Unitless" XCU
 SG_ StcStsToDmcEngRotTarSpdDMCFrnt : 23|16@0- (1.0,0.0) [-32768.0|32767.0] "Unitless" XCU
 SG_ StcStsToDmcEngRotTarSpdDMCRear : 39|16@0- (1.0,0.0) [-32768.0|32767.0] "Unitless" XCU
 SG_ StcStsToDmcFrnt : 55|8@0+ (1,0) [0|255] "" XCU
 SG_ StcStsToDmcRear : 63|8@0+ (1,0) [0|255] "" XCU

BO_ 118 VddmPropFr05 : 8 ZCUD
 SG_ BrkPedlPsd_UB : 23|1@0+ (1,0) [0|1] "" Vector__XXX
 SG_ BrkPedlPsdBrkPedlNotPsdSafe : 7|1@0+ (1,0) [0|1] "" Vector__XXX
 SG_ BrkPedlPsdBrkPedlPsd : 6|1@0+ (1,0) [0|1] "" Vector__XXX
 SG_ BrkPedlPsdChks : 15|8@0+ (1.0,0.0) [0.0|255.0] "Unitless" Vector__XXX
 SG_ BrkPedlPsdCntr : 3|4@0+ (1.0,0.0) [0.0|15.0] "Unitless" Vector__XXX
 SG_ BrkPedlPsdQf : 5|2@0+ (1,0) [0|3] "" Vector__XXX
 SG_ VehMtnSt_UB : 57|1@0+ (1,0) [0|1] "" XCU
 SG_ VehMtnStChks : 31|8@0+ (1.0,0.0) [0.0|255.0] "Unitless" XCU
 SG_ VehMtnStCntr : 22|4@0+ (1.0,0.0) [0.0|15.0] "Unitless" XCU
 SG_ VehMtnStVehMtnSt : 18|3@0+ (1,0) [0|7] "" XCU
 SG_ VehSpdLgt_UB : 39|1@0+ (1,0) [0|1] "" BECM,CDD,EGSM,TMCU
 SG_ VehSpdLgtA : 38|15@0+ (0.00391,0.0) [0.0|125.0027] "m/s" BECM,CDD,EGSM,TMCU
 SG_ VehSpdLgtChks : 55|8@0+ (1.0,0.0) [0.0|255.0] "Unitless" BECM,CDD,EGSM,TMCU
 SG_ VehSpdLgtCntr : 63|4@0+ (1.0,0.0) [0.0|15.0] "Unitless" BECM,CDD,EGSM,TMCU
 SG_ VehSpdLgtQf : 59|2@0+ (1,0) [0|3] "" BECM,CDD,EGSM,TMCU

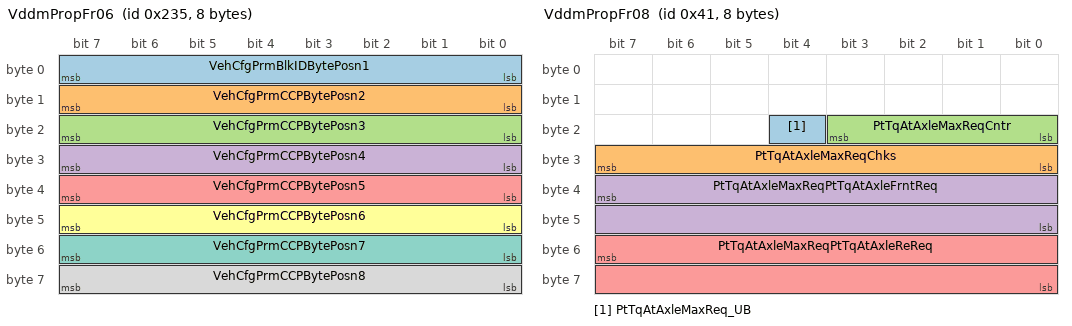
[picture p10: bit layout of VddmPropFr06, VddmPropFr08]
BO_ 565 VddmPropFr06 : 8 IHU
 SG_ VehCfgPrmBlkIDBytePosn1 : 7|8@0+ (1.0,0.0) [0.0|255.0] "Unitless" BECM,CDD,EGSM,TMCU,XCU
 SG_ VehCfgPrmCCPBytePosn2 : 15|8@0+ (1.0,0.0) [0.0|255.0] "Unitless" BECM,CDD,EGSM,TMCU,XCU
 SG_ VehCfgPrmCCPBytePosn3 : 23|8@0+ (1.0,0.0) [0.0|255.0] "Unitless" BECM,CDD,EGSM,TMCU,XCU
 SG_ VehCfgPrmCCPBytePosn4 : 31|8@0+ (1.0,0.0) [0.0|255.0] "Unitless" BECM,CDD,EGSM,TMCU,XCU
 SG_ VehCfgPrmCCPBytePosn5 : 39|8@0+ (1.0,0.0) [0.0|255.0] "Unitless" BECM,CDD,EGSM,TMCU,XCU
 SG_ VehCfgPrmCCPBytePosn6 : 47|8@0+ (1.0,0.0) [0.0|255.0] "Unitless" BECM,CDD,EGSM,TMCU,XCU
 SG_ VehCfgPrmCCPBytePosn7 : 55|8@0+ (1.0,0.0) [0.0|255.0] "Unitless" BECM,CDD,EGSM,TMCU,XCU
 SG_ VehCfgPrmCCPBytePosn8 : 63|8@0+ (1.0,0.0) [0.0|255.0] "Unitless" BECM,CDD,EGSM,TMCU,XCU

BO_ 65 VddmPropFr08 : 8 ZCUD
 SG_ PtTqAtAxleMaxReq_UB : 20|1@0+ (1,0) [0|1] "" IHU
 SG_ PtTqAtAxleMaxReqChks : 31|8@0+ (1.0,0.0) [0.0|255.0] "Unitless" IHU
 SG_ PtTqAtAxleMaxReqCntr : 19|4@0+ (1.0,0.0) [0.0|15.0] "Unitless" IHU
 SG_ PtTqAtAxleMaxReqPtTqAtAxleFrntReq : 39|16@0- (1.0,0.0) [-20000.0|20000.0] "NewtonMeter" IHU
 SG_ PtTqAtAxleMaxReqPtTqAtAxleReReq : 55|16@0- (1.0,0.0) [-20000.0|20000.0] "NewtonMeter" IHU

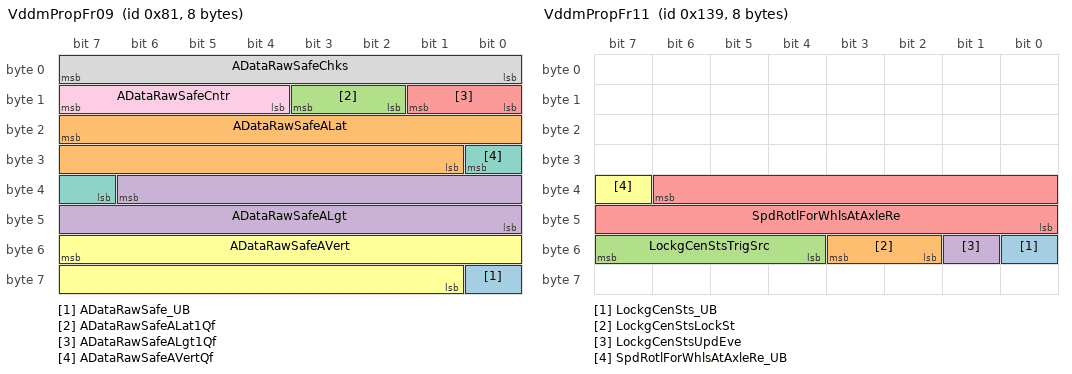
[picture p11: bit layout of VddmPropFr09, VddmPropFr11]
BO_ 129 VddmPropFr09 : 8 ZCUD
 SG_ ADataRawSafe_UB : 56|1@0+ (1,0) [0|1] "" IHU
 SG_ ADataRawSafeALat : 23|15@0- (0.0085,0.0) [-138.99200000000002|139.00050000000002] "m/s^2" IHU
 SG_ ADataRawSafeALat1Qf : 11|2@0+ (1,0) [0|3] "" IHU
 SG_ ADataRawSafeALgt : 38|15@0- (0.0085,0.0) [-138.99200000000002|139.00050000000002] "m/s^2" IHU
 SG_ ADataRawSafeALgt1Qf : 9|2@0+ (1,0) [0|3] "" IHU
 SG_ ADataRawSafeAVert : 55|15@0- (0.0085,0.0) [-138.99200000000002|139.00050000000002] "m/s^2" IHU
 SG_ ADataRawSafeAVertQf : 24|2@0+ (1,0) [0|3] "" IHU
 SG_ ADataRawSafeChks : 7|8@0+ (1.0,0.0) [0.0|255.0] "Unitless" IHU
 SG_ ADataRawSafeCntr : 15|4@0+ (1.0,0.0) [0.0|15.0] "Unitless" IHU

BO_ 313 VddmPropFr11 : 8 ZCUD
 SG_ LockgCenSts_UB : 48|1@0+ (1,0) [0|1] "" CDD,XCU
 SG_ LockgCenStsLockSt : 51|2@0+ (1,0) [0|3] "" CDD,XCU
 SG_ LockgCenStsTrigSrc : 55|4@0+ (1,0) [0|15] "" CDD,XCU
 SG_ LockgCenStsUpdEve : 49|1@0+ (1,0) [0|1] "" CDD,XCU
 SG_ SpdRotlForWhlsAtAxleRe : 38|15@0+ (0.5,0.0) [0.0|16383.5] "rpm" Vector__XXX
 SG_ SpdRotlForWhlsAtAxleRe_UB : 39|1@0+ (1,0) [0|1] "" Vector__XXX

BO_ 353 VddmPropFr12 : 8 IHU
 SG_ V2XDchaSwt : 54|2@0+ (1,0) [0|3] "" CDD,XCU
 SG_ V2XDchaSwt_UB : 52|1@0+ (1,0) [0|1] "" CDD,XCU

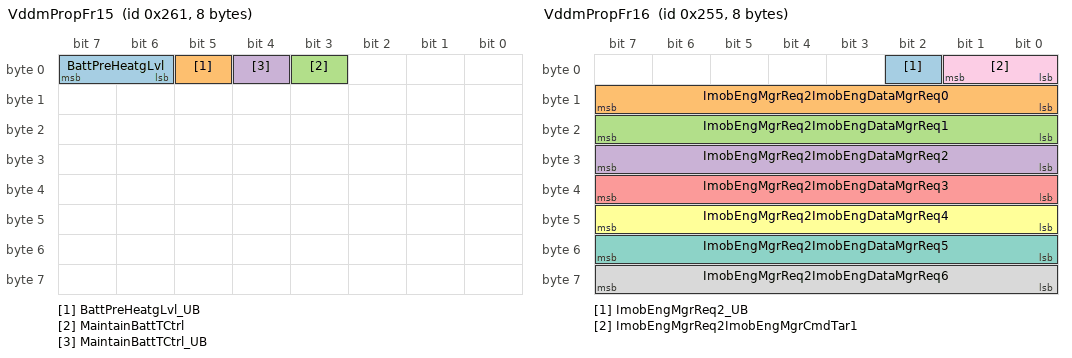
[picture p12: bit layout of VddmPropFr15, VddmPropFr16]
BO_ 609 VddmPropFr15 : 8 IHU
 SG_ BattPreHeatgLvl : 7|2@0+ (1,0) [0|3] "" XCU
 SG_ BattPreHeatgLvl_UB : 5|1@0+ (1,0) [0|1] "" XCU
 SG_ MaintainBattTCtrl : 3|1@0+ (1,0) [0|1] "" XCU
 SG_ MaintainBattTCtrl_UB : 4|1@0+ (1,0) [0|1] "" XCU

BO_ 597 VddmPropFr16 : 8 ZCUD
 SG_ ImobEngMgrReq2_UB : 2|1@0+ (1,0) [0|1] "" Vector__XXX
 SG_ ImobEngMgrReq2ImobEngDataMgrReq0 : 15|8@0+ (1.0,0.0) [0.0|255.0] "Unitless" Vector__XXX
 SG_ ImobEngMgrReq2ImobEngDataMgrReq1 : 23|8@0+ (1.0,0.0) [0.0|255.0] "Unitless" Vector__XXX
 SG_ ImobEngMgrReq2ImobEngDataMgrReq2 : 31|8@0+ (1.0,0.0) [0.0|255.0] "Unitless" Vector__XXX
 SG_ ImobEngMgrReq2ImobEngDataMgrReq3 : 39|8@0+ (1.0,0.0) [0.0|255.0] "Unitless" Vector__XXX
 SG_ ImobEngMgrReq2ImobEngDataMgrReq4 : 47|8@0+ (1.0,0.0) [0.0|255.0] "Unitless" Vector__XXX
 SG_ ImobEngMgrReq2ImobEngDataMgrReq5 : 55|8@0+ (1.0,0.0) [0.0|255.0] "Unitless" Vector__XXX
 SG_ ImobEngMgrReq2ImobEngDataMgrReq6 : 63|8@0+ (1.0,0.0) [0.0|255.0] "Unitless" Vector__XXX
 SG_ ImobEngMgrReq2ImobEngMgrCmdTar1 : 1|2@0+ (1,0) [0|3] "" Vector__XXX

BO_ 354 VddmPropFr17 : 8 ZCUD
 SG_ CarTiGlb : 7|32@0+ (0.1,0.0) [0.0|429496729.5] "s" BECM,CDD,EGSM,TMCU
 SG_ CarTiGlb_UB : 39|1@0+ (1,0) [0|1] "" BECM,CDD,EGSM,TMCU

BO_ 86 VddmPropFr18 : 8 ZCUD
 SG_ ChrgnUReq : 55|8@0+ (0.025,10.6) [10.6|16.0] "Volt" CDD,IHU
 SG_ ChrgnUReq_UB : 40|1@0+ (1,0) [0|1] "" CDD,IHU
 SG_ CnclBookTrvlReq : 62|1@0+ (1,0) [0|1] "" XCU
 SG_ CnclBookTrvlReq_UB : 63|1@0+ (1,0) [0|1] "" XCU
 SG_ IntrBriSts : 44|4@0+ (1.0,0.0) [0.0|15.0] "Unitless" EGSM,IHU
 SG_ IntrBriSts_UB : 45|1@0+ (1,0) [0|1] "" EGSM,IHU
 SG_ TwliBriSts : 47|1@0+ (1,0) [0|1] "" EGSM
 SG_ TwliBriSts_UB : 46|1@0+ (1,0) [0|1] "" EGSM
 SG_ VehModMngtGlbSafe1_UB : 32|1@0+ (1,0) [0|1] "" BECM,CDD,EGSM,TMCU,XCU
 SG_ VehModMngtGlbSafe1CarModSts1 : 39|3@0+ (1,0) [0|7] "" BECM,CDD,EGSM,TMCU,XCU
 SG_ VehModMngtGlbSafe1CarModSubtypWdCarModSubtyp : 36|3@0+ (1.0,0.0) [0.0|7.0] "Unitless" BECM,CDD,EGSM,TMCU,XCU
 SG_ VehModMngtGlbSafe1Chks : 7|8@0+ (1.0,0.0) [0.0|255.0] "Unitless" BECM,CDD,EGSM,TMCU,XCU
 SG_ VehModMngtGlbSafe1Cntr : 15|4@0+ (1.0,0.0) [0.0|15.0] "Unitless" BECM,CDD,EGSM,TMCU,XCU
 SG_ VehModMngtGlbSafe1EgyLvlElecMai : 27|4@0+ (1.0,0.0) [0.0|15.0] "Unitless" BECM,CDD,EGSM,TMCU,XCU
 SG_ VehModMngtGlbSafe1EgyLvlElecSubtyp : 31|4@0+ (1.0,0.0) [0.0|15.0] "Unitless" BECM,CDD,EGSM,TMCU,XCU
 SG_ VehModMngtGlbSafe1FltEgyCnsWdSts : 33|1@0+ (1,0) [0|1] "" BECM,CDD,EGSM,TMCU,XCU
 SG_ VehModMngtGlbSafe1PwrLvlElecMai : 19|4@0+ (1.0,0.0) [0.0|15.0] "Unitless" BECM,CDD,EGSM,TMCU,XCU
 SG_ VehModMngtGlbSafe1PwrLvlElecSubtyp : 23|4@0+ (1.0,0.0) [0.0|15.0] "Unitless" BECM,CDD,EGSM,TMCU,XCU
 SG_ VehModMngtGlbSafe1UsgModSts : 11|4@0+ (1,0) [0|15] "" BECM,CDD,EGSM,TMCU,XCU

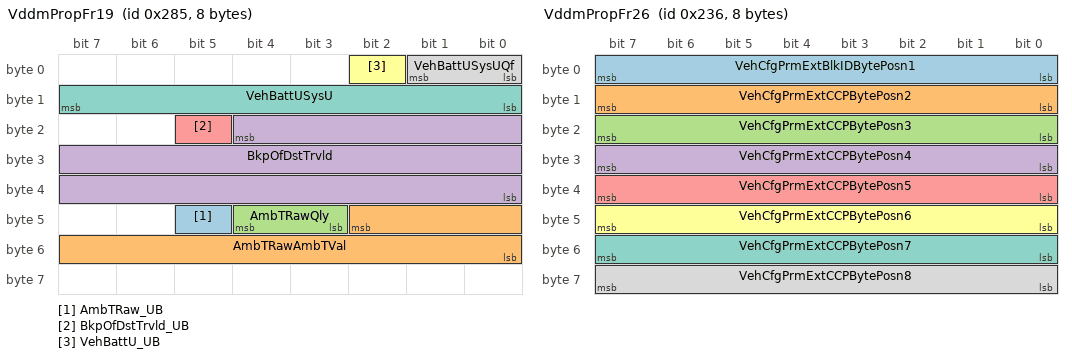
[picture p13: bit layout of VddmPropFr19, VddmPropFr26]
BO_ 645 VddmPropFr19 : 8 ZCUD
 SG_ AmbTRaw_UB : 45|1@0+ (1,0) [0|1] "" XCU
 SG_ AmbTRawAmbTVal : 42|11@0+ (0.1,-70.0) [-70.0|134.70000000000002] "degC" XCU
 SG_ AmbTRawQly : 44|2@0+ (1,0) [0|3] "" XCU
 SG_ BkpOfDstTrvld : 20|21@0+ (1.0,0.0) [0.0|2000000.0] "km" BECM,CDD,EGSM,TMCU,XCU
 SG_ BkpOfDstTrvld_UB : 21|1@0+ (1,0) [0|1] "" BECM,CDD,EGSM,TMCU,XCU
 SG_ VehBattU_UB : 2|1@0+ (1,0) [0|1] "" BECM,CDD,EGSM,TMCU,XCU
 SG_ VehBattUSysU : 15|8@0+ (0.1,0.0) [0.0|25.0] "Volt" BECM,CDD,EGSM,TMCU,XCU
 SG_ VehBattUSysUQf : 1|2@0+ (1,0) [0|3] "" BECM,CDD,EGSM,TMCU,XCU

BO_ 566 VddmPropFr26 : 8 IHU
 SG_ VehCfgPrmExtBlkIDBytePosn1 : 7|8@0+ (1.0,0.0) [0.0|255.0] "Unitless" BECM,CDD,EGSM,TMCU,XCU
 SG_ VehCfgPrmExtCCPBytePosn2 : 15|8@0+ (1.0,0.0) [0.0|255.0] "Unitless" BECM,CDD,EGSM,TMCU,XCU
 SG_ VehCfgPrmExtCCPBytePosn3 : 23|8@0+ (1.0,0.0) [0.0|255.0] "Unitless" BECM,CDD,EGSM,TMCU,XCU
 SG_ VehCfgPrmExtCCPBytePosn4 : 31|8@0+ (1.0,0.0) [0.0|255.0] "Unitless" BECM,CDD,EGSM,TMCU,XCU
 SG_ VehCfgPrmExtCCPBytePosn5 : 39|8@0+ (1.0,0.0) [0.0|255.0] "Unitless" BECM,CDD,EGSM,TMCU,XCU
 SG_ VehCfgPrmExtCCPBytePosn6 : 47|8@0+ (1.0,0.0) [0.0|255.0] "Unitless" BECM,CDD,EGSM,TMCU,XCU
 SG_ VehCfgPrmExtCCPBytePosn7 : 55|8@0+ (1.0,0.0) [0.0|255.0] "Unitless" BECM,CDD,EGSM,TMCU,XCU
 SG_ VehCfgPrmExtCCPBytePosn8 : 63|8@0+ (1.0,0.0) [0.0|255.0] "Unitless" BECM,CDD,EGSM,TMCU,XCU

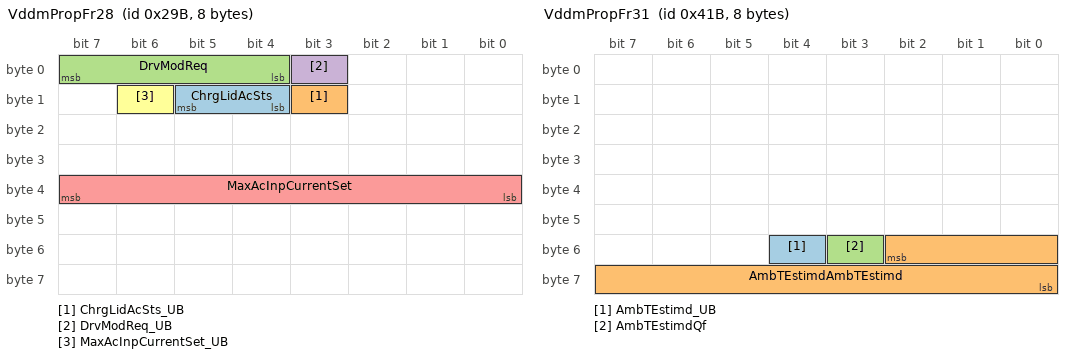
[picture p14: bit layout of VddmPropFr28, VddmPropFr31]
BO_ 667 VddmPropFr28 : 8 ZCUD
 SG_ ChrgLidAcSts : 13|2@0+ (1,0) [0|3] "" CDD,IHU
 SG_ ChrgLidAcSts_UB : 11|1@0+ (1,0) [0|1] "" CDD,IHU
 SG_ DrvModReq : 7|4@0+ (1,0) [0|15] "" Vector__XXX
 SG_ DrvModReq_UB : 3|1@0+ (1,0) [0|1] "" Vector__XXX
 SG_ MaxAcInpCurrentSet : 39|8@0+ (1.0,0.0) [0.0|255.0] "Unitless" CDD,XCU
 SG_ MaxAcInpCurrentSet_UB : 14|1@0+ (1,0) [0|1] "" CDD,XCU

BO_ 49 VddmPropFr29 : 8 ZCUD
 SG_ ChrgLidDCorAcDcSts : 55|2@0+ (1,0) [0|3] "" CDD,IHU
 SG_ ChrgLidDCorAcDcSts_UB : 40|1@0+ (1,0) [0|1] "" CDD,IHU

BO_ 1051 VddmPropFr31 : 8 ZCUD
 SG_ AmbTEstimd_UB : 52|1@0+ (1,0) [0|1] "" XCU
 SG_ AmbTEstimdAmbTEstimd : 50|11@0+ (0.1,-70.0) [-70.0|134.70000000000002] "degC" XCU
 SG_ AmbTEstimdQf : 51|1@0+ (1,0) [0|1] "" XCU

BO_ 304 VddmPropFr35 : 8 ZCUD
 SG_ PtActrReModReq : 26|2@0+ (1,0) [0|3] "" Vector__XXX
 SG_ PtActrReModReq_UB : 27|1@0+ (1,0) [0|1] "" Vector__XXX

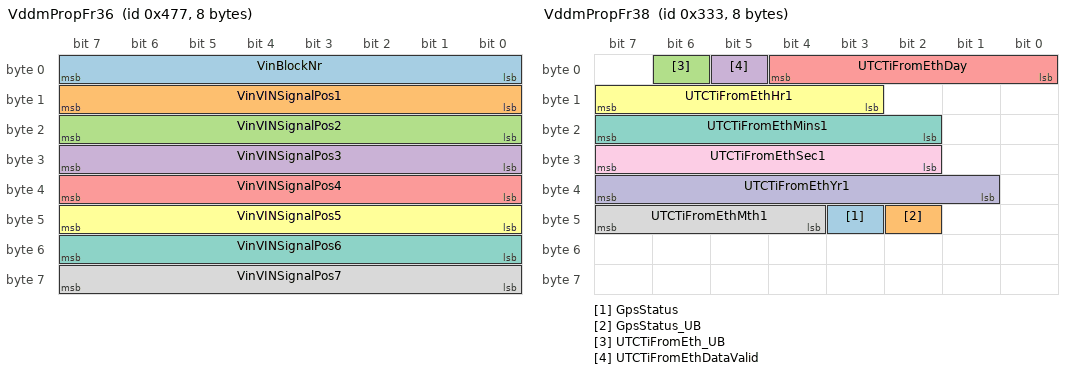
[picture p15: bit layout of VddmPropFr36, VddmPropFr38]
BO_ 1143 VddmPropFr36 : 8 IHU
 SG_ VinBlockNr : 7|8@0+ (1.0,0.0) [0.0|255.0] "Unitless" XCU
 SG_ VinVINSignalPos1 : 15|8@0+ (1.0,0.0) [0.0|255.0] "Unitless" XCU
 SG_ VinVINSignalPos2 : 23|8@0+ (1.0,0.0) [0.0|255.0] "Unitless" XCU
 SG_ VinVINSignalPos3 : 31|8@0+ (1.0,0.0) [0.0|255.0] "Unitless" XCU
 SG_ VinVINSignalPos4 : 39|8@0+ (1.0,0.0) [0.0|255.0] "Unitless" XCU
 SG_ VinVINSignalPos5 : 47|8@0+ (1.0,0.0) [0.0|255.0] "Unitless" XCU
 SG_ VinVINSignalPos6 : 55|8@0+ (1.0,0.0) [0.0|255.0] "Unitless" XCU
 SG_ VinVINSignalPos7 : 63|8@0+ (1.0,0.0) [0.0|255.0] "Unitless" XCU

BO_ 375 VddmPropFr37 : 8 IHU
 SG_ BattPreHeatgTiDif : 55|16@0+ (1.0,0.0) [0.0|65535.0] "Mins" XCU
 SG_ BattPreHeatgTiDif_UB : 42|1@0+ (1,0) [0|1] "" XCU

BO_ 819 VddmPropFr38 : 8 IHU
 SG_ GpsStatus : 43|1@0+ (1,0) [0|1] "" XCU
 SG_ GpsStatus_UB : 42|1@0+ (1,0) [0|1] "" XCU
 SG_ UTCTiFromEth_UB : 6|1@0+ (1,0) [0|1] "" XCU
 SG_ UTCTiFromEthDataValid : 5|1@0+ (1,0) [0|1] "" XCU
 SG_ UTCTiFromEthDay : 4|5@0+ (1.0,0.0) [1.0|31.0] "Days" XCU
 SG_ UTCTiFromEthHr1 : 15|5@0+ (1.0,0.0) [0.0|23.0] "hours" XCU
 SG_ UTCTiFromEthMins1 : 23|6@0+ (1.0,0.0) [0.0|59.0] "Mins" XCU
 SG_ UTCTiFromEthMth1 : 47|4@0+ (1.0,0.0) [1.0|12.0] "Month" XCU
 SG_ UTCTiFromEthSec1 : 31|6@0+ (1.0,0.0) [0.0|59.0] "s" XCU
 SG_ UTCTiFromEthYr1 : 39|7@0+ (1.0,0.0) [0.0|99.0] "Year" XCU

BO_ 57 VddmPropFr40 : 8 ZCUD
 SG_ DoorDrvrLockSts : 19|2@0+ (1,0) [0|3] "" CDD
 SG_ DoorDrvrLockSts_UB : 16|1@0+ (1,0) [0|1] "" CDD

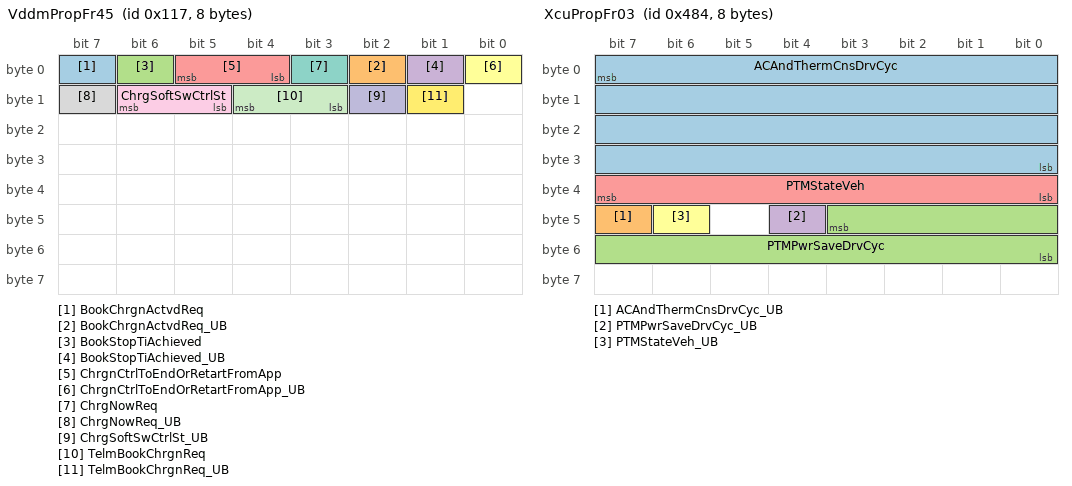
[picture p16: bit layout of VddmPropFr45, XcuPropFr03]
BO_ 279 VddmPropFr45 : 8 IHU
 SG_ BookChrgnActvdReq : 7|1@0+ (1,0) [0|1] "" XCU
 SG_ BookChrgnActvdReq_UB : 2|1@0+ (1,0) [0|1] "" XCU
 SG_ BookStopTiAchieved : 6|1@0+ (1,0) [0|1] "" XCU
 SG_ BookStopTiAchieved_UB : 1|1@0+ (1,0) [0|1] "" XCU
 SG_ ChrgnCtrlToEndOrRetartFromApp : 5|2@0+ (1,0) [0|3] "" XCU
 SG_ ChrgnCtrlToEndOrRetartFromApp_UB : 0|1@0+ (1,0) [0|1] "" XCU
 SG_ ChrgNowReq : 3|1@0+ (1,0) [0|1] "" XCU
 SG_ ChrgNowReq_UB : 15|1@0+ (1,0) [0|1] "" XCU
 SG_ ChrgSoftSwCtrlSt : 14|2@0+ (1,0) [0|3] "" XCU
 SG_ ChrgSoftSwCtrlSt_UB : 10|1@0+ (1,0) [0|1] "" XCU
 SG_ TelmBookChrgnReq : 12|2@0+ (1,0) [0|3] "" XCU
 SG_ TelmBookChrgnReq_UB : 9|1@0+ (1,0) [0|1] "" XCU

BO_ 568 VddmPropFr46 : 8 ZCUD
 SG_ ActvnOfSymIllmn : 7|1@0+ (1,0) [0|1] "" EGSM,IHU
 SG_ ActvnOfSymIllmn_UB : 6|1@0+ (1,0) [0|1] "" EGSM,IHU

BO_ 786 VgmPropFr01 : 8 IHU
 SG_ OnBdDiagLostCom : 6|4@0+ (1.0,0.0) [0.0|15.0] "Unitless" XCU
 SG_ OnBdDiagLostCom_UB : 7|1@0+ (1,0) [0|1] "" XCU

BO_ 2020 VgmToIgmJ1979OBDPropCanReqFrame11 : 8 IHU

BO_ 563 XcuPropFr01 : 8 XCU
 SG_ Edcp2PmpCmd_UB : 60|1@0+ (1,0) [0|1] "" IHU,TMCU
 SG_ Edcp2PmpCmdCooltPmpPostRunReq : 15|3@0+ (1,0) [0|7] "" IHU,TMCU
 SG_ Edcp2PmpCmdCooltPmpSpdReq : 7|8@0+ (1.0,0.0) [0.0|254.0] "Unitless" IHU,TMCU
 SG_ EexvPosnReq_UB : 59|1@0+ (1,0) [0|1] "" IHU,TMCU
 SG_ EexvPosnReqExvCalibReq : 12|1@0+ (1,0) [0|1] "" IHU,TMCU
 SG_ EexvPosnReqExvHeatdReq : 11|1@0+ (1,0) [0|1] "" IHU,TMCU
 SG_ EexvPosnReqExvMovEnable : 10|1@0+ (1,0) [0|1] "" IHU,TMCU
 SG_ EexvPosnReqExvPosnReq : 9|10@0+ (0.2,0.0) [0.0|100.0] "%" IHU,TMCU
 SG_ ExvPosnReq_UB : 58|1@0+ (1,0) [0|1] "" TMCU
 SG_ ExvPosnReqExvCalibReq : 36|1@0+ (1,0) [0|1] "" TMCU
 SG_ ExvPosnReqExvHeatdReq : 35|1@0+ (1,0) [0|1] "" TMCU
 SG_ ExvPosnReqExvMovEnable : 34|1@0+ (1,0) [0|1] "" TMCU
 SG_ ExvPosnReqExvPosnReq : 33|10@0+ (0.2,0.0) [0.0|100.0] "%" TMCU
 SG_ HeatrPmpCmd_UB : 57|1@0+ (1,0) [0|1] "" TMCU
 SG_ HeatrPmpCmdCooltPmpPostRunReq : 39|3@0+ (1,0) [0|7] "" TMCU
 SG_ HeatrPmpCmdCooltPmpSpdReq : 31|8@0+ (1.0,0.0) [0.0|254.0] "Unitless" TMCU
 SG_ HvBattPmpCmd_UB : 56|1@0+ (1,0) [0|1] "" IHU,TMCU
 SG_ HvBattPmpCmdCooltPmpPostRunReq : 63|3@0+ (1,0) [0|7] "" IHU,TMCU
 SG_ HvBattPmpCmdCooltPmpSpdReq : 55|8@0+ (1.0,0.0) [0.0|254.0] "Unitless" IHU,TMCU

BO_ 633 XcuPropFr02 : 8 XCU
 SG_ CcvmCmd_UB : 45|1@0+ (1,0) [0|1] "" TMCU
 SG_ CcvmCmdVlvActvSaveReq : 13|1@0+ (1,0) [0|1] "" TMCU
 SG_ CcvmCmdVlvCalibReq : 12|1@0+ (1,0) [0|1] "" TMCU
 SG_ CcvmCmdVlvHeatdReq : 11|1@0+ (1,0) [0|1] "" TMCU
 SG_ CcvmCmdVlvMovEna : 10|1@0+ (1,0) [0|1] "" TMCU
 SG_ CcvmCmdVlvPosn : 7|10@0+ (0.1,0.0) [0.0|100.0] "%" TMCU
 SG_ CcvmCmdVlvSpdLvlReq : 9|2@0+ (1,0) [0|3] "" TMCU
 SG_ CcvPosReq_UB : 44|1@0+ (1,0) [0|1] "" TMCU
 SG_ CcvPosReqDftPos : 23|10@0+ (0.26367188,-45.0) [-45.0|224.73633324000002] "Unitless" TMCU
 SG_ CcvPosReqPosReq : 39|10@0+ (0.26367188,-45.0) [-45.0|224.73633324000002] "Unitless" TMCU
 SG_ CcvPosReqReqEnad : 29|1@0+ (1,0) [0|1] "" TMCU
 SG_ CcvPosReqRstPos : 28|2@0+ (1,0) [0|3] "" TMCU
 SG_ CcvPosReqTrqReq : 26|3@0+ (1,0) [0|7] "" TMCU
 SG_ HctvCmd_UB : 43|1@0+ (1,0) [0|1] "" IHU,TMCU
 SG_ HctvCmdVlvActvSaveReq : 61|1@0+ (1,0) [0|1] "" IHU,TMCU
 SG_ HctvCmdVlvCalibReq : 60|1@0+ (1,0) [0|1] "" IHU,TMCU
 SG_ HctvCmdVlvHeatdReq : 59|1@0+ (1,0) [0|1] "" IHU,TMCU
 SG_ HctvCmdVlvMovEna : 58|1@0+ (1,0) [0|1] "" IHU,TMCU
 SG_ HctvCmdVlvPosn : 55|10@0+ (0.1,0.0) [0.0|100.0] "%" IHU,TMCU
 SG_ HctvCmdVlvSpdLvlReq : 57|2@0+ (1,0) [0|3] "" IHU,TMCU

BO_ 1156 XcuPropFr03 : 8 XCU
 SG_ ACAndThermCnsDrvCyc : 7|32@0+ (0.1,0.0) [0.0|800000.0] "Kilojoule_1" IHU
 SG_ ACAndThermCnsDrvCyc_UB : 47|1@0+ (1,0) [0|1] "" IHU
 SG_ PTMPwrSaveDrvCyc : 43|12@0+ (0.01,0.0) [0.0|40.95] "KwH_1" IHU
 SG_ PTMPwrSaveDrvCyc_UB : 44|1@0+ (1,0) [0|1] "" IHU
 SG_ PTMStateVeh : 39|8@0+ (1,0) [0|255] "" IHU
 SG_ PTMStateVeh_UB : 46|1@0+ (1,0) [0|1] "" IHU

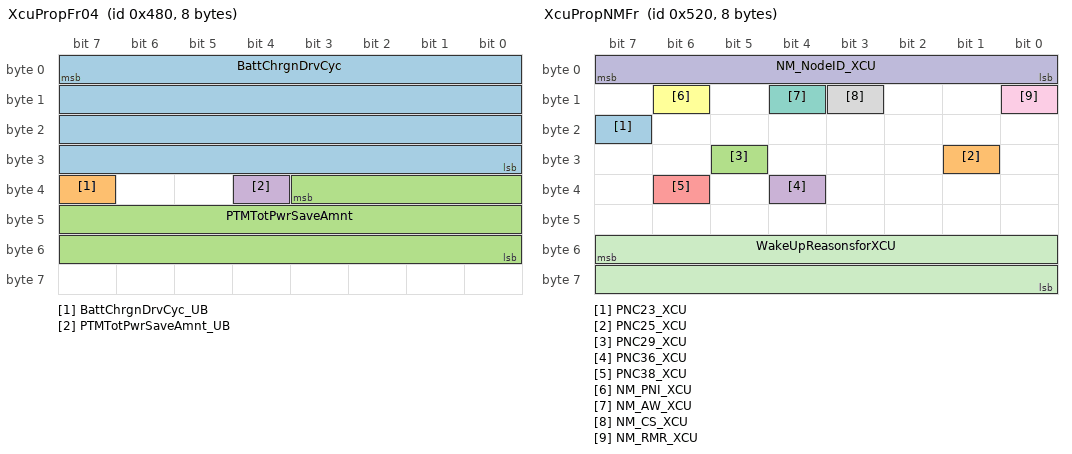
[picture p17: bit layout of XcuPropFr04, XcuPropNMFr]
BO_ 1152 XcuPropFr04 : 8 XCU
 SG_ BattChrgnDrvCyc : 7|32@0+ (0.1,0.0) [0.0|800000.0] "Kilojoule_1" IHU
 SG_ BattChrgnDrvCyc_UB : 39|1@0+ (1,0) [0|1] "" IHU
 SG_ PTMTotPwrSaveAmnt : 35|20@0+ (0.1,0.0) [0.0|104857.5] "KwH_1" IHU
 SG_ PTMTotPwrSaveAmnt_UB : 36|1@0+ (1,0) [0|1] "" IHU

BO_ 1173 XcuPropFr05 : 8 XCU
 SG_ BattDchaDrvCyc : 7|32@0+ (0.1,0.0) [0.0|800000.0] "Kilojoule_1" IHU
 SG_ BattDchaDrvCyc_UB : 39|1@0+ (1,0) [0|1] "" IHU

BO_ 1312 XcuPropNMFr : 8 XCU
 SG_ PNC23_XCU : 23|1@0+ (1,0) [0|0] "" Vector__XXX
 SG_ PNC25_XCU : 25|1@0+ (1,0) [0|0] "" Vector__XXX
 SG_ PNC29_XCU : 29|1@0+ (1,0) [0|0] "" Vector__XXX
 SG_ PNC36_XCU : 36|1@0+ (1,0) [0|0] "" Vector__XXX
 SG_ PNC38_XCU : 38|1@0+ (1,0) [0|0] "" Vector__XXX
 SG_ NM_PNI_XCU : 14|1@0+ (1,0) [0|0] "" Vector__XXX
 SG_ NM_AW_XCU : 12|1@0+ (1,0) [0|0] "" Vector__XXX
 SG_ NM_CS_XCU : 11|1@0+ (1,0) [0|0] "" Vector__XXX
 SG_ NM_RMR_XCU : 8|1@0+ (1,0) [0|0] "" Vector__XXX
 SG_ NM_NodeID_XCU : 7|8@0+ (1,0) [0|0] "" Vector__XXX

 SG_ WakeUpReasonsforXCU : 55|16@0+ (1,0) [0|65535] "" Vector__XXX

BO_ 1376 XcuPropVFCVectorFr : 8 XCU
 SG_ VFCVectorXCUBlockID : 1|2@0+ (1.0,0.0) [0.0|3.0] "Unitless" IHU
 SG_ VFCVectorXCUVFCid0 : 2|1@0+ (1,0) [0|1] "" IHU
 SG_ VFCVectorXCUVFCid1 : 3|1@0+ (1,0) [0|1] "" IHU
 SG_ VFCVectorXCUVFCid10 : 12|1@0+ (1,0) [0|1] "" IHU
 SG_ VFCVectorXCUVFCid11 : 13|1@0+ (1,0) [0|1] "" IHU
 SG_ VFCVectorXCUVFCid12 : 14|1@0+ (1,0) [0|1] "" IHU
 SG_ VFCVectorXCUVFCid13 : 15|1@0+ (1,0) [0|1] "" IHU
 SG_ VFCVectorXCUVFCid14 : 16|1@0+ (1,0) [0|1] "" IHU
 SG_ VFCVectorXCUVFCid15 : 17|1@0+ (1,0) [0|1] "" IHU
 SG_ VFCVectorXCUVFCid16 : 18|1@0+ (1,0) [0|1] "" IHU
 SG_ VFCVectorXCUVFCid17 : 19|1@0+ (1,0) [0|1] "" IHU
 SG_ VFCVectorXCUVFCid18 : 20|1@0+ (1,0) [0|1] "" IHU
 SG_ VFCVectorXCUVFCid19 : 21|1@0+ (1,0) [0|1] "" IHU
 SG_ VFCVectorXCUVFCid2 : 4|1@0+ (1,0) [0|1] "" IHU
 SG_ VFCVectorXCUVFCid20 : 22|1@0+ (1,0) [0|1] "" IHU
 SG_ VFCVectorXCUVFCid21 : 23|1@0+ (1,0) [0|1] "" IHU
 SG_ VFCVectorXCUVFCid22 : 24|1@0+ (1,0) [0|1] "" IHU
 SG_ VFCVectorXCUVFCid23 : 25|1@0+ (1,0) [0|1] "" IHU
 SG_ VFCVectorXCUVFCid24 : 26|1@0+ (1,0) [0|1] "" IHU
 SG_ VFCVectorXCUVFCid25 : 27|1@0+ (1,0) [0|1] "" IHU
 SG_ VFCVectorXCUVFCid26 : 28|1@0+ (1,0) [0|1] "" IHU
 SG_ VFCVectorXCUVFCid27 : 29|1@0+ (1,0) [0|1] "" IHU
 SG_ VFCVectorXCUVFCid28 : 30|1@0+ (1,0) [0|1] "" IHU
 SG_ VFCVectorXCUVFCid29 : 31|1@0+ (1,0) [0|1] "" IHU
 SG_ VFCVectorXCUVFCid3 : 5|1@0+ (1,0) [0|1] "" IHU
 SG_ VFCVectorXCUVFCid30 : 32|1@0+ (1,0) [0|1] "" IHU
 SG_ VFCVectorXCUVFCid31 : 33|1@0+ (1,0) [0|1] "" IHU
 SG_ VFCVectorXCUVFCid32 : 34|1@0+ (1,0) [0|1] "" IHU
 SG_ VFCVectorXCUVFCid33 : 35|1@0+ (1,0) [0|1] "" IHU
 SG_ VFCVectorXCUVFCid34 : 36|1@0+ (1,0) [0|1] "" IHU
 SG_ VFCVectorXCUVFCid35 : 37|1@0+ (1,0) [0|1] "" IHU
 SG_ VFCVectorXCUVFCid36 : 38|1@0+ (1,0) [0|1] "" IHU
 SG_ VFCVectorXCUVFCid37 : 39|1@0+ (1,0) [0|1] "" IHU
 SG_ VFCVectorXCUVFCid38 : 40|1@0+ (1,0) [0|1] "" IHU
 SG_ VFCVectorXCUVFCid39 : 41|1@0+ (1,0) [0|1] "" IHU
 SG_ VFCVectorXCUVFCid4 : 6|1@0+ (1,0) [0|1] "" IHU
 SG_ VFCVectorXCUVFCid40 : 42|1@0+ (1,0) [0|1] "" IHU
 SG_ VFCVectorXCUVFCid41 : 43|1@0+ (1,0) [0|1] "" IHU
 SG_ VFCVectorXCUVFCid42 : 44|1@0+ (1,0) [0|1] "" IHU
 SG_ VFCVectorXCUVFCid43 : 45|1@0+ (1,0) [0|1] "" IHU
 SG_ VFCVectorXCUVFCid44 : 46|1@0+ (1,0) [0|1] "" IHU
 SG_ VFCVectorXCUVFCid45 : 47|1@0+ (1,0) [0|1] "" IHU
 SG_ VFCVectorXCUVFCid46 : 48|1@0+ (1,0) [0|1] "" IHU
 SG_ VFCVectorXCUVFCid47 : 49|1@0+ (1,0) [0|1] "" IHU
 SG_ VFCVectorXCUVFCid48 : 50|1@0+ (1,0) [0|1] "" IHU
 SG_ VFCVectorXCUVFCid49 : 51|1@0+ (1,0) [0|1] "" IHU
 SG_ VFCVectorXCUVFCid5 : 7|1@0+ (1,0) [0|1] "" IHU
 SG_ VFCVectorXCUVFCid50 : 52|1@0+ (1,0) [0|1] "" IHU
 SG_ VFCVectorXCUVFCid51 : 53|1@0+ (1,0) [0|1] "" IHU
 SG_ VFCVectorXCUVFCid52 : 54|1@0+ (1,0) [0|1] "" IHU
 SG_ VFCVectorXCUVFCid53 : 55|1@0+ (1,0) [0|1] "" IHU
 SG_ VFCVectorXCUVFCid54 : 56|1@0+ (1,0) [0|1] "" IHU
 SG_ VFCVectorXCUVFCid55 : 57|1@0+ (1,0) [0|1] "" IHU
 SG_ VFCVectorXCUVFCid56 : 58|1@0+ (1,0) [0|1] "" IHU
 SG_ VFCVectorXCUVFCid57 : 59|1@0+ (1,0) [0|1] "" IHU
 SG_ VFCVectorXCUVFCid58 : 60|1@0+ (1,0) [0|1] "" IHU
 SG_ VFCVectorXCUVFCid59 : 61|1@0+ (1,0) [0|1] "" IHU
 SG_ VFCVectorXCUVFCid6 : 8|1@0+ (1,0) [0|1] "" IHU
 SG_ VFCVectorXCUVFCid60 : 62|1@0+ (1,0) [0|1] "" IHU
 SG_ VFCVectorXCUVFCid61 : 63|1@0+ (1,0) [0|1] "" IHU
 SG_ VFCVectorXCUVFCid7 : 9|1@0+ (1,0) [0|1] "" IHU
 SG_ VFCVectorXCUVFCid8 : 10|1@0+ (1,0) [0|1] "" IHU
 SG_ VFCVectorXCUVFCid9 : 11|1@0+ (1,0) [0|1] "" IHU

BO_ 2030 XcuToDhuJ1979OBDPropDiagResFrame11 : 8 XCU

BO_ 1349 ZCUDPropCANVFCVectorFr : 8 ZCUD
 SG_ VFCVectorZCUDMBlockID : 1|2@0+ (1.0,0.0) [0.0|3.0] "Unitless" Vector__XXX
 SG_ VFCVectorZCUDMVFCid0 : 2|1@0+ (1,0) [0|1] "" Vector__XXX
 SG_ VFCVectorZCUDMVFCid1 : 3|1@0+ (1,0) [0|1] "" Vector__XXX
 SG_ VFCVectorZCUDMVFCid10 : 12|1@0+ (1,0) [0|1] "" Vector__XXX
 SG_ VFCVectorZCUDMVFCid11 : 13|1@0+ (1,0) [0|1] "" Vector__XXX
 SG_ VFCVectorZCUDMVFCid12 : 14|1@0+ (1,0) [0|1] "" Vector__XXX
 SG_ VFCVectorZCUDMVFCid13 : 15|1@0+ (1,0) [0|1] "" Vector__XXX
 SG_ VFCVectorZCUDMVFCid14 : 16|1@0+ (1,0) [0|1] "" Vector__XXX
 SG_ VFCVectorZCUDMVFCid15 : 17|1@0+ (1,0) [0|1] "" Vector__XXX
 SG_ VFCVectorZCUDMVFCid16 : 18|1@0+ (1,0) [0|1] "" Vector__XXX
 SG_ VFCVectorZCUDMVFCid17 : 19|1@0+ (1,0) [0|1] "" Vector__XXX
 SG_ VFCVectorZCUDMVFCid18 : 20|1@0+ (1,0) [0|1] "" Vector__XXX
 SG_ VFCVectorZCUDMVFCid19 : 21|1@0+ (1,0) [0|1] "" Vector__XXX
 SG_ VFCVectorZCUDMVFCid2 : 4|1@0+ (1,0) [0|1] "" Vector__XXX
 SG_ VFCVectorZCUDMVFCid20 : 22|1@0+ (1,0) [0|1] "" Vector__XXX
 SG_ VFCVectorZCUDMVFCid21 : 23|1@0+ (1,0) [0|1] "" Vector__XXX
 SG_ VFCVectorZCUDMVFCid22 : 24|1@0+ (1,0) [0|1] "" Vector__XXX
 SG_ VFCVectorZCUDMVFCid23 : 25|1@0+ (1,0) [0|1] "" Vector__XXX
 SG_ VFCVectorZCUDMVFCid24 : 26|1@0+ (1,0) [0|1] "" Vector__XXX
 SG_ VFCVectorZCUDMVFCid25 : 27|1@0+ (1,0) [0|1] "" Vector__XXX
 SG_ VFCVectorZCUDMVFCid26 : 28|1@0+ (1,0) [0|1] "" Vector__XXX
 SG_ VFCVectorZCUDMVFCid27 : 29|1@0+ (1,0) [0|1] "" Vector__XXX
 SG_ VFCVectorZCUDMVFCid28 : 30|1@0+ (1,0) [0|1] "" Vector__XXX
 SG_ VFCVectorZCUDMVFCid29 : 31|1@0+ (1,0) [0|1] "" Vector__XXX
 SG_ VFCVectorZCUDMVFCid3 : 5|1@0+ (1,0) [0|1] "" Vector__XXX
 SG_ VFCVectorZCUDMVFCid30 : 32|1@0+ (1,0) [0|1] "" Vector__XXX
 SG_ VFCVectorZCUDMVFCid31 : 33|1@0+ (1,0) [0|1] "" Vector__XXX
 SG_ VFCVectorZCUDMVFCid32 : 34|1@0+ (1,0) [0|1] "" Vector__XXX
 SG_ VFCVectorZCUDMVFCid33 : 35|1@0+ (1,0) [0|1] "" Vector__XXX
 SG_ VFCVectorZCUDMVFCid34 : 36|1@0+ (1,0) [0|1] "" Vector__XXX
 SG_ VFCVectorZCUDMVFCid35 : 37|1@0+ (1,0) [0|1] "" Vector__XXX
 SG_ VFCVectorZCUDMVFCid36 : 38|1@0+ (1,0) [0|1] "" Vector__XXX
 SG_ VFCVectorZCUDMVFCid37 : 39|1@0+ (1,0) [0|1] "" Vector__XXX
 SG_ VFCVectorZCUDMVFCid38 : 40|1@0+ (1,0) [0|1] "" Vector__XXX
 SG_ VFCVectorZCUDMVFCid39 : 41|1@0+ (1,0) [0|1] "" Vector__XXX
 SG_ VFCVectorZCUDMVFCid4 : 6|1@0+ (1,0) [0|1] "" Vector__XXX
 SG_ VFCVectorZCUDMVFCid40 : 42|1@0+ (1,0) [0|1] "" Vector__XXX
 SG_ VFCVectorZCUDMVFCid41 : 43|1@0+ (1,0) [0|1] "" Vector__XXX
 SG_ VFCVectorZCUDMVFCid42 : 44|1@0+ (1,0) [0|1] "" Vector__XXX
 SG_ VFCVectorZCUDMVFCid43 : 45|1@0+ (1,0) [0|1] "" Vector__XXX
 SG_ VFCVectorZCUDMVFCid44 : 46|1@0+ (1,0) [0|1] "" Vector__XXX
 SG_ VFCVectorZCUDMVFCid45 : 47|1@0+ (1,0) [0|1] "" Vector__XXX
 SG_ VFCVectorZCUDMVFCid46 : 48|1@0+ (1,0) [0|1] "" Vector__XXX
 SG_ VFCVectorZCUDMVFCid47 : 49|1@0+ (1,0) [0|1] "" Vector__XXX
 SG_ VFCVectorZCUDMVFCid48 : 50|1@0+ (1,0) [0|1] "" Vector__XXX
 SG_ VFCVectorZCUDMVFCid49 : 51|1@0+ (1,0) [0|1] "" Vector__XXX
 SG_ VFCVectorZCUDMVFCid5 : 7|1@0+ (1,0) [0|1] "" Vector__XXX
 SG_ VFCVectorZCUDMVFCid50 : 52|1@0+ (1,0) [0|1] "" Vector__XXX
 SG_ VFCVectorZCUDMVFCid51 : 53|1@0+ (1,0) [0|1] "" Vector__XXX
 SG_ VFCVectorZCUDMVFCid52 : 54|1@0+ (1,0) [0|1] "" Vector__XXX
 SG_ VFCVectorZCUDMVFCid53 : 55|1@0+ (1,0) [0|1] "" Vector__XXX
 SG_ VFCVectorZCUDMVFCid54 : 56|1@0+ (1,0) [0|1] "" Vector__XXX
 SG_ VFCVectorZCUDMVFCid55 : 57|1@0+ (1,0) [0|1] "" Vector__XXX
 SG_ VFCVectorZCUDMVFCid56 : 58|1@0+ (1,0) [0|1] "" Vector__XXX
 SG_ VFCVectorZCUDMVFCid57 : 59|1@0+ (1,0) [0|1] "" Vector__XXX
 SG_ VFCVectorZCUDMVFCid58 : 60|1@0+ (1,0) [0|1] "" Vector__XXX
 SG_ VFCVectorZCUDMVFCid59 : 61|1@0+ (1,0) [0|1] "" Vector__XXX
 SG_ VFCVectorZCUDMVFCid6 : 8|1@0+ (1,0) [0|1] "" Vector__XXX
 SG_ VFCVectorZCUDMVFCid60 : 62|1@0+ (1,0) [0|1] "" Vector__XXX
 SG_ VFCVectorZCUDMVFCid61 : 63|1@0+ (1,0) [0|1] "" Vector__XXX
 SG_ VFCVectorZCUDMVFCid7 : 9|1@0+ (1,0) [0|1] "" Vector__XXX
 SG_ VFCVectorZCUDMVFCid8 : 10|1@0+ (1,0) [0|1] "" Vector__XXX
 SG_ VFCVectorZCUDMVFCid9 : 11|1@0+ (1,0) [0|1] "" Vector__XXX

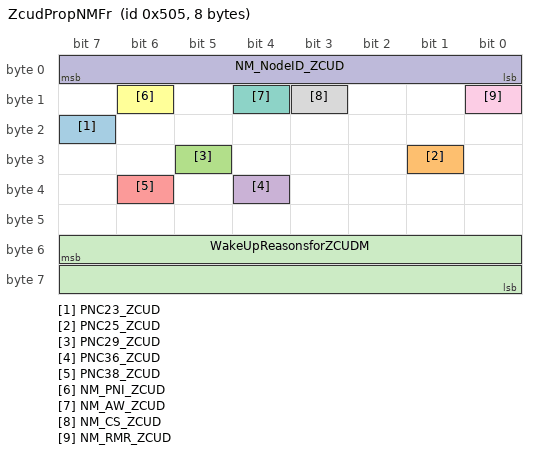
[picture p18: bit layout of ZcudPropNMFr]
BO_ 1285 ZcudPropNMFr : 8 ZCUD
 SG_ PNC23_ZCUD : 23|1@0+ (1,0) [0|0] "" Vector__XXX
 SG_ PNC25_ZCUD : 25|1@0+ (1,0) [0|0] "" Vector__XXX
 SG_ PNC29_ZCUD : 29|1@0+ (1,0) [0|0] "" Vector__XXX
 SG_ PNC36_ZCUD : 36|1@0+ (1,0) [0|0] "" Vector__XXX
 SG_ PNC38_ZCUD : 38|1@0+ (1,0) [0|0] "" Vector__XXX
 SG_ NM_PNI_ZCUD : 14|1@0+ (1,0) [0|0] "" Vector__XXX
 SG_ NM_AW_ZCUD : 12|1@0+ (1,0) [0|0] "" Vector__XXX
 SG_ NM_CS_ZCUD : 11|1@0+ (1,0) [0|0] "" Vector__XXX
 SG_ NM_RMR_ZCUD : 8|1@0+ (1,0) [0|0] "" Vector__XXX
 SG_ NM_NodeID_ZCUD : 7|8@0+ (1,0) [0|0] "" Vector__XXX

 SG_ WakeUpReasonsforZCUDM : 55|16@0+ (1,0) [0|65535] "" Vector__XXX

CM_ SG_ 75 EngSt1WdStsChks "checksum";
CM_ SG_ 75 EngSt1WdStsCntr "counter";
CM_ SG_ 75 EngSt1WdStsEngSt1WdSts "Signaling the state of the powerpack";
CM_ SG_ 75 GearLvrIndcn "Gear lever indication (drivetrain position) to the driver. If drivetrain position is not possible to decide signal is set to undefined. Valid for automatic vehicles.
";
CM_ SG_ 634 DrvgCyc " Transition from 0 to 1 indicates a start of a new Driving Cycle.";
CM_ SG_ 634 V2XDchaSwtFb1 "propulsion feedback discahrging switch status";
CM_ SG_ 401 FrntHeatModEnad "Active heating enabling signal for front motor";
CM_ SG_ 278 AccrPedlPsdAccrPedlPsd "Describes if the accelerator pedal is pressed. Will indicate pressed for a small pedal press. Accompanying status signal will indicate the integrity of the information.";
CM_ SG_ 278 AccrPedlPsdChks "Describes if the accelerator pedal is pressed. Will indicate pressed for a small pedal press.checksum";
CM_ SG_ 278 AccrPedlPsdCntr "Describes if the accelerator pedal is pressed. Will indicate pressed for a small pedal press.couner";
CM_ SG_ 278 AccrPedlPsdSts "Describes if the accelerator pedal is pressed. Will indicate pressed for a small pedal press. Accompanying status signal will indicate the integrity of the information. AccrPedlPsd fulfills ASIL C integrity";
CM_ SG_ 278 HvAuxActPwr "Actual consumption for auxillary loads (cooling and heating)";
CM_ SG_ 569 BexvPosnReqExvCalibReq "Bexv calibration request.";
CM_ SG_ 569 BexvPosnReqExvHeatdReq "Bexv heating request.";
CM_ SG_ 569 BexvPosnReqExvMovEnable "Bexv move enable.";
CM_ SG_ 569 BexvPosnReqExvPosnReq "Bexv postion request.";
CM_ SG_ 569 HvBattLowSOCIndcn "Hv Battery Low SOC status  Indication";
CM_ SG_ 569 HvBattThermPreSts "Predictive Battery Thermal status";
CM_ SG_ 649 HvBattChrgnEgyCnsAllwd1 "How much available energy is available for charging. Estimated available energy from wall socket.";
CM_ SG_ 649 HvBattChrgnILim "Charging current limit value to OBC";
CM_ SG_ 649 HvBattCoolgEgyCnsAllwd1 "How much available energy is available for battery cooling. Estimated available energy from wall socket or Hv battery.";
CM_ SG_ 309 DrvrGearShiftManReqDwnDwnTipReq "Driver tip request from gear shifter or steering wheel for gear selection. Valid for Shift-By-Wire system. Tip down down request";
CM_ SG_ 309 DrvrGearShiftManReqDwnTipReq "Driver tip request from gear shifter or steering wheel for gear selection. Valid for Shift-By-Wire system. Tip down request";
CM_ SG_ 309 DrvrGearShiftManReqSteerWhlDwnReq1 "Driver tip request from gear shifter or steering wheel for gear selection. Valid for Shift-By-Wire system. Paddle down request";
CM_ SG_ 309 DrvrGearShiftManReqSteerWhlUpReq "Driver tip request from gear shifter or steering wheel for gear selection. Valid for Shift-By-Wire system. Paddle up request";
CM_ SG_ 309 DrvrGearShiftManReqTipReq1 "Driver tip request from gear shifter or steering wheel for gear selection. Valid for Shift-By-Wire system. Tip request";
CM_ SG_ 309 DrvrGearShiftManReqUpTipReq1 "Driver tip request from gear shifter or steering wheel for gear selection. Valid for Shift-By-Wire system. Tip up request";
CM_ SG_ 309 DrvrGearShiftManReqUpUpTipReq "Driver tip request from gear shifter or steering wheel for gear selection. Valid for Shift-By-Wire system. Tip up up request";
CM_ SG_ 309 DrvrGearShiftParkReq1 "Driver park request from gear shifter. Valid for Shift-By-Wire system.";
CM_ SG_ 309 DrvrGearShiftParkReqChks "Driver park request from gear shifter. Valid for Shift-By-Wire system.Checksum";
CM_ SG_ 309 DrvrGearShiftParkReqCntr "Driver park request from gear shifter. Valid for Shift-By-Wire system.Counter";
CM_ SG_ 309 DrvrGearShiftParkReqSts "Driver park request from gear shifter. Valid for Shift-By-Wire system.Status";
CM_ SG_ 309 GearLock "When GearLock is in Active status, driver can chang gear.";
CM_ SG_ 309 GearShiftUnitSts "Signal is used to inform ECM of fault status of EGSM in Shift-by-wire koncept vehicles.";
CM_ SG_ 310 DrvrGearShiftDirReq1Chks "8 bit checksum";
CM_ SG_ 310 DrvrGearShiftDirReq1Cntr "4 bit counter used in checksum calculation. N=E (modulo 16)";
CM_ SG_ 310 DrvrGearShiftDirReq1DwnDwnTipAut "Gear shifter downdown tip in automatic gate";
CM_ SG_ 310 DrvrGearShiftDirReq1DwnTipAut "Gear shifter down tip in automatic gate";
CM_ SG_ 310 DrvrGearShiftDirReq1PosnAut "Gear shifter in automatic gate position";
CM_ SG_ 310 DrvrGearShiftDirReq1UpTipAut "Gear shifter up tip in automatic gate";
CM_ SG_ 310 DrvrGearShiftDirReq1UpUpTipAut "Gear shifter upup tip in automatic gate";
CM_ SG_ 310 DrvrGearShiftDirReq2Chks "8 bit checksum";
CM_ SG_ 310 DrvrGearShiftDirReq2Cntr "4 bit counter used in checksum calculation. N=E (modulo 16)";
CM_ SG_ 310 DrvrGearShiftDirReq2DwnDwnTipAut "Gear shifter downdown tip in automatic gate";
CM_ SG_ 310 DrvrGearShiftDirReq2DwnTipAut "Gear shifter down tip in automatic gate";
CM_ SG_ 310 DrvrGearShiftDirReq2PosnAut "Gear shifter in automatic gate position";
CM_ SG_ 310 DrvrGearShiftDirReq2UpTipAut "Gear shifter up tip in automatic gate";
CM_ SG_ 310 DrvrGearShiftDirReq2UpUpTipAut "Gear shifter upup tip in automatic gate";
CM_ SG_ 1366 VFCVectorEGSMBlockID "Block Identifier";
CM_ SG_ 1366 VFCVectorEGSMVFCid0 "VFC0";
CM_ SG_ 1366 VFCVectorEGSMVFCid1 "VFC1";
CM_ SG_ 1366 VFCVectorEGSMVFCid10 "VFC10";
CM_ SG_ 1366 VFCVectorEGSMVFCid11 "VFC11";
CM_ SG_ 1366 VFCVectorEGSMVFCid12 "VFC12";
CM_ SG_ 1366 VFCVectorEGSMVFCid13 "VFC13";
CM_ SG_ 1366 VFCVectorEGSMVFCid14 "VFC14";
CM_ SG_ 1366 VFCVectorEGSMVFCid15 "VFC15";
CM_ SG_ 1366 VFCVectorEGSMVFCid16 "VFC16";
CM_ SG_ 1366 VFCVectorEGSMVFCid17 "VFC17";
CM_ SG_ 1366 VFCVectorEGSMVFCid18 "VFC18";
CM_ SG_ 1366 VFCVectorEGSMVFCid19 "VFC19";
CM_ SG_ 1366 VFCVectorEGSMVFCid2 "VFC2";
CM_ SG_ 1366 VFCVectorEGSMVFCid20 "VFC20";
CM_ SG_ 1366 VFCVectorEGSMVFCid21 "VFC21";
CM_ SG_ 1366 VFCVectorEGSMVFCid22 "VFC22";
CM_ SG_ 1366 VFCVectorEGSMVFCid23 "VFC23";
CM_ SG_ 1366 VFCVectorEGSMVFCid24 "VFC24";
CM_ SG_ 1366 VFCVectorEGSMVFCid25 "VFC25";
CM_ SG_ 1366 VFCVectorEGSMVFCid26 "VFC26";
CM_ SG_ 1366 VFCVectorEGSMVFCid27 "VFC27";
CM_ SG_ 1366 VFCVectorEGSMVFCid28 "VFC28";
CM_ SG_ 1366 VFCVectorEGSMVFCid29 "VFC29";
CM_ SG_ 1366 VFCVectorEGSMVFCid3 "VFC3";
CM_ SG_ 1366 VFCVectorEGSMVFCid30 "VFC30";
CM_ SG_ 1366 VFCVectorEGSMVFCid31 "VFC31";
CM_ SG_ 1366 VFCVectorEGSMVFCid32 "VFC32";
CM_ SG_ 1366 VFCVectorEGSMVFCid33 "VFC33";
CM_ SG_ 1366 VFCVectorEGSMVFCid34 "VFC34";
CM_ SG_ 1366 VFCVectorEGSMVFCid35 "VFC35";
CM_ SG_ 1366 VFCVectorEGSMVFCid36 "VFC36";
CM_ SG_ 1366 VFCVectorEGSMVFCid37 "VFC37";
CM_ SG_ 1366 VFCVectorEGSMVFCid38 "VFC38";
CM_ SG_ 1366 VFCVectorEGSMVFCid39 "VFC39";
CM_ SG_ 1366 VFCVectorEGSMVFCid4 "VFC4";
CM_ SG_ 1366 VFCVectorEGSMVFCid40 "VFC40";
CM_ SG_ 1366 VFCVectorEGSMVFCid41 "VFC41";
CM_ SG_ 1366 VFCVectorEGSMVFCid42 "VFC42";
CM_ SG_ 1366 VFCVectorEGSMVFCid43 "VFC43";
CM_ SG_ 1366 VFCVectorEGSMVFCid44 "VFC44";
CM_ SG_ 1366 VFCVectorEGSMVFCid45 "VFC45";
CM_ SG_ 1366 VFCVectorEGSMVFCid46 "VFC46";
CM_ SG_ 1366 VFCVectorEGSMVFCid47 "VFC47";
CM_ SG_ 1366 VFCVectorEGSMVFCid48 "VFC48";
CM_ SG_ 1366 VFCVectorEGSMVFCid49 "VFC49";
CM_ SG_ 1366 VFCVectorEGSMVFCid5 "VFC5";
CM_ SG_ 1366 VFCVectorEGSMVFCid50 "VFC50";
CM_ SG_ 1366 VFCVectorEGSMVFCid51 "VFC51";
CM_ SG_ 1366 VFCVectorEGSMVFCid52 "VFC52";
CM_ SG_ 1366 VFCVectorEGSMVFCid53 "VFC53";
CM_ SG_ 1366 VFCVectorEGSMVFCid54 "VFC54";
CM_ SG_ 1366 VFCVectorEGSMVFCid55 "VFC55";
CM_ SG_ 1366 VFCVectorEGSMVFCid56 "VFC56";
CM_ SG_ 1366 VFCVectorEGSMVFCid57 "VFC57";
CM_ SG_ 1366 VFCVectorEGSMVFCid58 "VFC58";
CM_ SG_ 1366 VFCVectorEGSMVFCid59 "VFC59";
CM_ SG_ 1366 VFCVectorEGSMVFCid6 "VFC6";
CM_ SG_ 1366 VFCVectorEGSMVFCid60 "VFC60";
CM_ SG_ 1366 VFCVectorEGSMVFCid61 "VFC61";
CM_ SG_ 1366 VFCVectorEGSMVFCid7 "VFC7";
CM_ SG_ 1366 VFCVectorEGSMVFCid8 "VFC8";
CM_ SG_ 1366 VFCVectorEGSMVFCid9 "VFC9";
CM_ SG_ 314 IsgCooltT "Measured coolant temperature in inverter in degC";
CM_ SG_ 342 IsgUDc "HVDC voltage";
CM_ SG_ 149 IsgModSts "Inverter mode status";
CM_ SG_ 391 IsgFcnResvSigGrp "Front electric drive system reserved signal for future function development and verification rapidly.";
CM_ SG_ 391 IsgFcnResvSigGrp1 "Front electric drive system reserved signal for future function development and verification rapidly.";
CM_ SG_ 593 HmiSteerWhlHeatLvlReq "Steering Wheel Heat Level Request";
CM_ SG_ 299 LimdPwrPerc "-100%-100%";
CM_ SG_ 53 CrashStsSafeChks "Checksum for E2E";
CM_ SG_ 53 CrashStsSafeCntr "Counter for E2E";
CM_ SG_ 53 CrashStsSafeSts "Information if a crash has been detected by SRS.";
CM_ SG_ 681 HvBattPmpStatFromTMCUCooltPmpDryErr "water pump MT Dryrun error";
CM_ SG_ 681 HvBattPmpStatFromTMCUCooltPmpEmgyModSts "water pump MT, Status Emergency mode";
CM_ SG_ 681 HvBattPmpStatFromTMCUCooltPmpErrSts "water pump error status";
CM_ SG_ 681 HvBattPmpStatFromTMCUCooltPmpI "Actual current consumption from battery coolant pump.";
CM_ SG_ 681 HvBattPmpStatFromTMCUCooltPmpIErr "water pump MT current error";
CM_ SG_ 681 HvBattPmpStatFromTMCUCooltPmpMonrSpd "water pump MT, RPM Monitoring";
CM_ SG_ 681 HvBattPmpStatFromTMCUCooltPmpPostRunSts "water pump post run status";
CM_ SG_ 681 HvBattPmpStatFromTMCUCooltPmpSetPostRunReq "water pump set post run speed request";
CM_ SG_ 681 HvBattPmpStatFromTMCUCooltPmpSetSpdReq "Coolant pump set speed request";
CM_ SG_ 681 HvBattPmpStatFromTMCUCooltPmpSpd "Coolant pump actual speed";
CM_ SG_ 681 HvBattPmpStatFromTMCUCooltPmpT "water pump MT Temperature ";
CM_ SG_ 681 HvBattPmpStatFromTMCUCooltPmpTErr "water pump MT temperature error";
CM_ SG_ 681 HvBattPmpStatFromTMCUCooltPmpU "Coolant pump voltage";
CM_ SG_ 681 HvBattPmpStatFromTMCUCooltPmpUErr "water pump MT voltage error";
CM_ SG_ 681 HvBattPmpStatFromTMCUCooltPmpUnstallSts "water pump MT, Deblocking";
CM_ SG_ 678 HeatrPmpStatFromTMCUCooltPmpDryErr "water pump MT Dryrun error";
CM_ SG_ 678 HeatrPmpStatFromTMCUCooltPmpEmgyModSts "water pump MT, Status Emergency mode";
CM_ SG_ 678 HeatrPmpStatFromTMCUCooltPmpErrSts "water pump error status";
CM_ SG_ 678 HeatrPmpStatFromTMCUCooltPmpI "Actual current consumption from battery coolant pump.";
CM_ SG_ 678 HeatrPmpStatFromTMCUCooltPmpIErr "water pump MT current error";
CM_ SG_ 678 HeatrPmpStatFromTMCUCooltPmpMonrSpd "water pump MT, RPM Monitoring";
CM_ SG_ 678 HeatrPmpStatFromTMCUCooltPmpPostRunSts "water pump post run status";
CM_ SG_ 678 HeatrPmpStatFromTMCUCooltPmpSetPostRunReq "water pump set post run speed request";
CM_ SG_ 678 HeatrPmpStatFromTMCUCooltPmpSetSpdReq "Coolant pump set speed request
";
CM_ SG_ 678 HeatrPmpStatFromTMCUCooltPmpSpd "Coolant pump actual speed";
CM_ SG_ 678 HeatrPmpStatFromTMCUCooltPmpT "water pump MT Temperature ";
CM_ SG_ 678 HeatrPmpStatFromTMCUCooltPmpTErr "water pump MT temperature error";
CM_ SG_ 678 HeatrPmpStatFromTMCUCooltPmpU "Coolant pump voltage";
CM_ SG_ 678 HeatrPmpStatFromTMCUCooltPmpUErr "water pump MT voltage error";
CM_ SG_ 678 HeatrPmpStatFromTMCUCooltPmpUnstallSts "water pump MT, Deblocking";
CM_ SG_ 684 Edcp2PmpStsFromTMCUCooltPmpDryErr "water pump MT Dryrun error";
CM_ SG_ 684 Edcp2PmpStsFromTMCUCooltPmpEmgyModSts "water pump MT, Status Emergency mode";
CM_ SG_ 684 Edcp2PmpStsFromTMCUCooltPmpErrSts "water pump error status";
CM_ SG_ 684 Edcp2PmpStsFromTMCUCooltPmpI "Actual current consumption from battery coolant pump.";
CM_ SG_ 684 Edcp2PmpStsFromTMCUCooltPmpIErr "water pump MT current error";
CM_ SG_ 684 Edcp2PmpStsFromTMCUCooltPmpMonrSpd "water pump MT, RPM Monitoring";
CM_ SG_ 684 Edcp2PmpStsFromTMCUCooltPmpPostRunSts "water pump post run status";
CM_ SG_ 684 Edcp2PmpStsFromTMCUCooltPmpSetPostRunReq "water pump set post run speed request";
CM_ SG_ 684 Edcp2PmpStsFromTMCUCooltPmpSetSpdReq "Coolant pump set speed request
";
CM_ SG_ 684 Edcp2PmpStsFromTMCUCooltPmpSpd "Coolant pump actual speed";
CM_ SG_ 684 Edcp2PmpStsFromTMCUCooltPmpT "water pump MT Temperature ";
CM_ SG_ 684 Edcp2PmpStsFromTMCUCooltPmpTErr "water pump MT temperature error";
CM_ SG_ 684 Edcp2PmpStsFromTMCUCooltPmpU "Coolant pump voltage";
CM_ SG_ 684 Edcp2PmpStsFromTMCUCooltPmpUErr "water pump MT voltage error";
CM_ SG_ 684 Edcp2PmpStsFromTMCUCooltPmpUnstallSts "water pump MT, Deblocking";
CM_ SG_ 1057 BexvNVMFltFromTMCU "Bexv Non Volatile Memory Fault";
CM_ SG_ 1057 EexvNVMFltFromTMCU "Eexv Non Volatile Memory Fault";
CM_ SG_ 1057 ExvNVMFltFromTMCU "Exv Non Volatile Memory Fault";
CM_ SG_ 869 CcvmStsFromTMCUVlvBlkFlt "Valve blocked error.";
CM_ SG_ 869 CcvmStsFromTMCUVlvCalibSts "Valve calibration status.";
CM_ SG_ 869 CcvmStsFromTMCUVlvCmdPosnErr "Valve position command is not plausible.";
CM_ SG_ 869 CcvmStsFromTMCUVlvLoTErr "Valve lower-temp error.";
CM_ SG_ 869 CcvmStsFromTMCUVlvMoveSts "Valve move status.";
CM_ SG_ 869 CcvmStsFromTMCUVlvNVMFlt "Valve position memory is lost.";
CM_ SG_ 869 CcvmStsFromTMCUVlvOpenCircFlt "Valve open circuit fault.";
CM_ SG_ 869 CcvmStsFromTMCUVlvOverTErr "Valve over-temp error.";
CM_ SG_ 869 CcvmStsFromTMCUVlvOverTrvlFlt "Valve over-travel error.";
CM_ SG_ 869 CcvmStsFromTMCUVlvOverTWarn "Valve over-temp warning.";
CM_ SG_ 869 CcvmStsFromTMCUVlvOverUErr "Valve error due to the voltage over the maximum.";
CM_ SG_ 869 CcvmStsFromTMCUVlvPosn "Valve actual position.";
CM_ SG_ 869 CcvmStsFromTMCUVlvPosnCtrlTimeOutFlt "Valve position control is time out.";
CM_ SG_ 869 CcvmStsFromTMCUVlvPosnUkwnFlt "Valve position unkown fault.";
CM_ SG_ 869 CcvmStsFromTMCUVlvPreHeatgSts "Valve preheated status";
CM_ SG_ 869 CcvmStsFromTMCUVlvSelfLearnFlt "Valve self-learning fault.";
CM_ SG_ 869 CcvmStsFromTMCUVlvShoCircFlt "Valve short circuit fault.";
CM_ SG_ 869 CcvmStsFromTMCUVlvSpdLvlSts "Valve speed level status.";
CM_ SG_ 869 CcvmStsFromTMCUVlvUnderUErr "Valve error due to the voltage under the minimum";
CM_ SG_ 880 CcvVlvSts2PosStsFromTMCU "Valve Position Feedback";
CM_ SG_ 880 CcvVlvStsFromTMCUARC "Valves Alive Rolling Counter";
CM_ SG_ 880 CcvVlvStsFromTMCUIntFlt "Valve Internal Fualt Present";
CM_ SG_ 880 CcvVlvStsFromTMCUOprFlt "Valve Operational Fault Present";
CM_ SG_ 880 CcvVlvStsFromTMCUTrqSts "Valve Torque Feedback";
CM_ SG_ 672 BexvStsFromTMCUExvActrPosn "Exv position status";
CM_ SG_ 672 BexvStsFromTMCUExvBlkErr "Exv blocked err.";
CM_ SG_ 672 BexvStsFromTMCUExvCalibSts "Exv calibration status";
CM_ SG_ 672 BexvStsFromTMCUExvElecStsErr "Exv electrical err.";
CM_ SG_ 672 BexvStsFromTMCUExvMovSts "Exv move status.";
CM_ SG_ 672 BexvStsFromTMCUExvOvrTempErr "Exv over-temp err.";
CM_ SG_ 672 BexvStsFromTMCUExvOvrTrvlErr "Exv over-travel err.";
CM_ SG_ 672 BexvStsFromTMCUExvPreHeatgSts "Exv preheating status.";
CM_ SG_ 672 BexvStsFromTMCUExvVoltgRangErr "Exv voltage err.";
CM_ SG_ 672 EexvStsFromTMCUExvActrPosn "Exv position status";
CM_ SG_ 672 EexvStsFromTMCUExvBlkErr "Exv blocked err.";
CM_ SG_ 672 EexvStsFromTMCUExvCalibSts "Exv calibration status";
CM_ SG_ 672 EexvStsFromTMCUExvElecStsErr "Exv electrical err.";
CM_ SG_ 672 EexvStsFromTMCUExvMovSts "Exv move status.";
CM_ SG_ 672 EexvStsFromTMCUExvOvrTempErr "Exv over-temp err.";
CM_ SG_ 672 EexvStsFromTMCUExvOvrTrvlErr "Exv over-travel err.";
CM_ SG_ 672 EexvStsFromTMCUExvPreHeatgSts "Exv preheating status.";
CM_ SG_ 672 EexvStsFromTMCUExvVoltgRangErr "Exv voltage err.";
CM_ SG_ 675 ExvStsFromTMCUExvActrPosn "Exv position status";
CM_ SG_ 675 ExvStsFromTMCUExvBlkErr "Exv blocked err.";
CM_ SG_ 675 ExvStsFromTMCUExvCalibSts "Exv calibration status";
CM_ SG_ 675 ExvStsFromTMCUExvElecStsErr "Exv electrical err.";
CM_ SG_ 675 ExvStsFromTMCUExvMovSts "Exv move status.";
CM_ SG_ 675 ExvStsFromTMCUExvOvrTempErr "Exv over-temp err.";
CM_ SG_ 675 ExvStsFromTMCUExvOvrTrvlErr "Exv over-travel err.";
CM_ SG_ 675 ExvStsFromTMCUExvPreHeatgSts "Exv preheating status.";
CM_ SG_ 675 ExvStsFromTMCUExvVoltgRangErr "Exv voltage err.";
CM_ SG_ 675 HctvStsFromTMCUVlvBlkFlt "Valve blocked error.";
CM_ SG_ 675 HctvStsFromTMCUVlvCalibSts "Valve calibration status.";
CM_ SG_ 675 HctvStsFromTMCUVlvCmdPosnErr "Valve position command is not plausible.";
CM_ SG_ 675 HctvStsFromTMCUVlvLoTErr "Valve lower-temp error.";
CM_ SG_ 675 HctvStsFromTMCUVlvMoveSts "Valve move status.";
CM_ SG_ 675 HctvStsFromTMCUVlvNVMFlt "Valve position memory is lost.";
CM_ SG_ 675 HctvStsFromTMCUVlvOpenCircFlt "Valve open circuit fault.";
CM_ SG_ 675 HctvStsFromTMCUVlvOverTErr "Valve over-temp error.";
CM_ SG_ 675 HctvStsFromTMCUVlvOverTrvlFlt "Valve over-travel error.";
CM_ SG_ 675 HctvStsFromTMCUVlvOverTWarn "Valve over-temp warning.";
CM_ SG_ 675 HctvStsFromTMCUVlvOverUErr "Valve error due to the voltage over the maximum.";
CM_ SG_ 675 HctvStsFromTMCUVlvPosn "Valve actual position.";
CM_ SG_ 675 HctvStsFromTMCUVlvPosnCtrlTimeOutFlt "Valve position control is time out.";
CM_ SG_ 675 HctvStsFromTMCUVlvPosnUkwnFlt "Valve position unkown fault.";
CM_ SG_ 675 HctvStsFromTMCUVlvPreHeatgSts "Valve preheated status";
CM_ SG_ 675 HctvStsFromTMCUVlvSelfLearnFlt "Valve self-learning fault.";
CM_ SG_ 675 HctvStsFromTMCUVlvShoCircFlt "Valve short circuit fault.";
CM_ SG_ 675 HctvStsFromTMCUVlvSpdLvlSts "Valve speed level status.";
CM_ SG_ 675 HctvStsFromTMCUVlvUnderUErr "Valve error due to the voltage under the minimum";
CM_ SG_ 377 PrpsnFcnResvSigGrp "Propulsion reserved signal for future function development and verification rapidly.";
CM_ SG_ 377 PrpsnFcnResvSigGrp1 "Propulsion reserved signal for future function development and verification rapidly.";
CM_ SG_ 337 TiAndDateIndcnDataValid "Current time (Hr, Min and Sec) and date (Year, Months and days) data for indication. See requirement for more information about the signals. Signal qualifier, No means values should be ignored.";
CM_ SG_ 337 TiAndDateIndcnDay "Current time (Hr, Min and Sec) and date (Year, Months and days) data for indication. See requirement for more information about the signals. Day";
CM_ SG_ 337 TiAndDateIndcnHr1 "Current time (Hr, Min and Sec) and date (Year, Months and days) data for indication. See requirement for more information about the signals. Hour";
CM_ SG_ 337 TiAndDateIndcnMins1 "Current time (Hr, Min and Sec) and date (Year, Months and days) data for indication. See requirement for more information about the signals. Minutes";
CM_ SG_ 337 TiAndDateIndcnMth1 "Current time (Hr, Min and Sec) and date (Year, Months and days) data for indication. See requirement for more information about the signals. Month, 1-12";
CM_ SG_ 337 TiAndDateIndcnSec1 "Current time (Hr, Min and Sec) and date (Year, Months and days) data for indication. See requirement for more information about the signals. Seconds";
CM_ SG_ 337 TiAndDateIndcnYr1 "Current time (Hr, Min and Sec) and date (Year, Months and days) data for indication. See requirement for more information about the signals. Year, 0-99";
CM_ SG_ 302 EscVariantToDmcChks "Chks";
CM_ SG_ 302 EscVariantToDmcCntr "Cntr";
CM_ SG_ 302 EscVariantToDmcEscVariantToDmc "Esc Variant";
CM_ SG_ 282 StcStsToDmcChks "Chks";
CM_ SG_ 282 StcStsToDmcCntr "Cntr";
CM_ SG_ 282 StcStsToDmcEngRotTarSpdDMCFrnt "Target Moto speed";
CM_ SG_ 282 StcStsToDmcEngRotTarSpdDMCRear "Target Moto speed
";
CM_ SG_ 282 StcStsToDmcFrnt "StcSts to Dmc frint";
CM_ SG_ 282 StcStsToDmcRear "StcSts to DMC Rear";
CM_ SG_ 118 BrkPedlPsdBrkPedlNotPsdSafe "Set to 1 if brake pedal is not pressed, otherwise 0";
CM_ SG_ 118 BrkPedlPsdBrkPedlPsd "Set to 1 if brake pedal is pressed, otherwise 0";
CM_ SG_ 118 BrkPedlPsdChks "Checksum";
CM_ SG_ 118 BrkPedlPsdCntr "Counter";
CM_ SG_ 118 BrkPedlPsdQf "Quality factor";
CM_ SG_ 118 VehMtnStChks "Vehicle motion state information based on wheel speed sensors. Provides information about vehicle stand still and vehicle rolling direction. Checksum for vehicle motion state";
CM_ SG_ 118 VehMtnStCntr "Vehicle motion state information based on wheel speed sensors. Provides information about vehicle stand still and vehicle rolling direction. Counter for vehicle motion state";
CM_ SG_ 118 VehMtnStVehMtnSt "Vehicle motion state information based on wheel speed sensors. Provides information about vehicle stand still and vehicle rolling direction. Vehicle motion state";
CM_ SG_ 118 VehSpdLgtA "Vehicle speed longitudinal based on wheel speed sensors and longitudinal acceleration.";
CM_ SG_ 118 VehSpdLgtChks "Checksum";
CM_ SG_ 118 VehSpdLgtCntr "Counter";
CM_ SG_ 118 VehSpdLgtQf "Quality factor for vehicle speed as measured by wheel speed sensors and longitudinal acceleration.";
CM_ SG_ 565 VehCfgPrmBlkIDBytePosn1 "signal block counter.";
CM_ SG_ 565 VehCfgPrmCCPBytePosn2 " (BlockID-1)*7 + 1. ";
CM_ SG_ 565 VehCfgPrmCCPBytePosn3 " (BlockID-1)*7 + 2. ";
CM_ SG_ 565 VehCfgPrmCCPBytePosn4 " (BlockID-1)*7 + 3. ";
CM_ SG_ 565 VehCfgPrmCCPBytePosn5 " (BlockID-1)*7 + 4. ";
CM_ SG_ 565 VehCfgPrmCCPBytePosn6 " (BlockID-1)*7 + 5. ";
CM_ SG_ 565 VehCfgPrmCCPBytePosn7 " (BlockID-1)*7 + 6. ";
CM_ SG_ 565 VehCfgPrmCCPBytePosn8 " (BlockID-1)*7 + 7. ";
CM_ SG_ 65 PtTqAtAxleMaxReqChks "checksum";
CM_ SG_ 65 PtTqAtAxleMaxReqCntr "counter";
CM_ SG_ 65 PtTqAtAxleMaxReqPtTqAtAxleFrntReq "Maximum allowed powertrain applied torque on the front axle.";
CM_ SG_ 65 PtTqAtAxleMaxReqPtTqAtAxleReReq "Maximum allowed powertrain applied torque on the rear axle.";
CM_ SG_ 129 ADataRawSafeALat "IMU acceleration data Lateral acceleration";
CM_ SG_ 129 ADataRawSafeALat1Qf "IMU acceleration data Quality factor for Lateral acceleration signal";
CM_ SG_ 129 ADataRawSafeALgt "IMU acceleration data Longitudinal acceleration";
CM_ SG_ 129 ADataRawSafeALgt1Qf "IMU acceleration data Quality factor for Longitudinal acceleration";
CM_ SG_ 129 ADataRawSafeAVert "IMU acceleration data Vertical acceleration";
CM_ SG_ 129 ADataRawSafeAVertQf "IMU acceleration data Quality factor for Vertical acceleration";
CM_ SG_ 129 ADataRawSafeChks "IMU acceleration data Check sum";
CM_ SG_ 129 ADataRawSafeCntr "IMU acceleration data Counter";
CM_ SG_ 313 LockgCenStsLockSt "Signal LockgCenSts provides central locking status to other subsystems.
Signal is a record with three items
- LockSt (Lock State)
- TrigSrc (Trig Source)
- UpdEve (Will be set to TRUE during one second at each new central locking or unlocking event)";
CM_ SG_ 313 LockgCenStsTrigSrc "Signal LockgCenSts provides central locking status to other subsystems.
Signal is a record with three items
- LockSt (Lock State)
- TrigSrc (Trig Source)
- UpdEve (Will be set to TRUE during one second at each new central locking or unlocking event)";
CM_ SG_ 313 LockgCenStsUpdEve "Signal LockgCenSts provides central locking status to other subsystems.
Signal is a record with three items
- LockSt (Lock State)
- TrigSrc (Trig Source)
- UpdEve (Will be set to TRUE during one second at each new central locking or unlocking event)";
CM_ SG_ 313 SpdRotlForWhlsAtAxleRe "Average angular velocity of rear wheels.";
CM_ SG_ 353 V2XDchaSwt "define which discharge type customer selected";
CM_ SG_ 609 BattPreHeatgLvl "Battery heating level chosen by user in the book travel function";
CM_ SG_ 609 MaintainBattTCtrl "on/off signal to control the function of maintaining the battery temperature ";
CM_ SG_ 597 ImobEngMgrReq2ImobEngDataMgrReq0 "Command from CEM to IEM with desired immo status and 7 bytes of response Byte 0";
CM_ SG_ 597 ImobEngMgrReq2ImobEngDataMgrReq1 "Command from CEM to IEM with desired immo status and 7 bytes of response Byte 1";
CM_ SG_ 597 ImobEngMgrReq2ImobEngDataMgrReq2 "Command from CEM to IEM with desired immo status and 7 bytes of response Byte 2";
CM_ SG_ 597 ImobEngMgrReq2ImobEngDataMgrReq3 "Command from CEM to IEM with desired immo status and 7 bytes of response Byte 3";
CM_ SG_ 597 ImobEngMgrReq2ImobEngDataMgrReq4 "Command from CEM to IEM with desired immo status and 7 bytes of response Byte 4";
CM_ SG_ 597 ImobEngMgrReq2ImobEngDataMgrReq5 "Command from CEM to IEM with desired immo status and 7 bytes of response Byte 5";
CM_ SG_ 597 ImobEngMgrReq2ImobEngDataMgrReq6 "Command from CEM to IEM with desired immo status and 7 bytes of response Byte 6";
CM_ SG_ 597 ImobEngMgrReq2ImobEngMgrCmdTar1 "Command from CEM to IEM with desired immo status and 7 bytes of response Command from CEM";
CM_ SG_ 354 CarTiGlb "Presents a tiime value that shall be used by all ECUs to time-stamp diagnsotic trouble codes (DTC) according to the requirements for Global DTC snapshot data.";
CM_ SG_ 86 ChrgnUReq "Requested Charging voltage from Voltage Control";
CM_ SG_ 86 CnclBookTrvlReq "A cancel request of the reservation departure function";
CM_ SG_ 86 IntrBriSts "Rheostat setting. Set by user through rheostat wheel situated on MyCar Module.";
CM_ SG_ 86 TwliBriSts "Day or night status signal. Lux value (not this signal) sent from SUS to CEM and CEM sets day or night signal.";
CM_ SG_ 86 VehModMngtGlbSafe1CarModSts1 "CarMode Status";
CM_ SG_ 86 VehModMngtGlbSafe1CarModSubtypWdCarModSubtyp "CarMode substate status";
CM_ SG_ 86 VehModMngtGlbSafe1Chks "Checksum";
CM_ SG_ 86 VehModMngtGlbSafe1Cntr "Counter";
CM_ SG_ 86 VehModMngtGlbSafe1EgyLvlElecMai "Main energy level in the vehicle.";
CM_ SG_ 86 VehModMngtGlbSafe1EgyLvlElecSubtyp "Substate of the energy level in the vehicle.";
CM_ SG_ 86 VehModMngtGlbSafe1FltEgyCnsWdSts "High quiescent current detected by CEM via BMS.";
CM_ SG_ 86 VehModMngtGlbSafe1PwrLvlElecMai "Main Power level in the vehicle.";
CM_ SG_ 86 VehModMngtGlbSafe1PwrLvlElecSubtyp "Substate of the power level in the vehicle.";
CM_ SG_ 86 VehModMngtGlbSafe1UsgModSts "UsageMode Status";
CM_ SG_ 645 AmbTRawAmbTVal "Unfiltered ambient temp raw data in deg C. Ambient temp value";
CM_ SG_ 645 AmbTRawQly "Unfiltered ambient temp raw data in deg C. Quality Factor of the ambient temp";
CM_ SG_ 645 BkpOfDstTrvld "total traveled distance.";
CM_ SG_ 645 VehBattUSysU "Vehicle System Voltage At 12V side";
CM_ SG_ 645 VehBattUSysUQf "Present vehicle voltage measured by CEM with QF";
CM_ SG_ 566 VehCfgPrmExtBlkIDBytePosn1 "CarConfigExtended BlockID";
CM_ SG_ 566 VehCfgPrmExtCCPBytePosn2 "CarConfigExtended BytePos2";
CM_ SG_ 566 VehCfgPrmExtCCPBytePosn3 "CarConfigExtended BytePos3";
CM_ SG_ 566 VehCfgPrmExtCCPBytePosn4 "CarConfigExtended BytePos4";
CM_ SG_ 566 VehCfgPrmExtCCPBytePosn5 "CarConfigExtended BytePos5";
CM_ SG_ 566 VehCfgPrmExtCCPBytePosn6 "CarConfigExtended BytePos6";
CM_ SG_ 566 VehCfgPrmExtCCPBytePosn7 "CarConfigExtended BytePos7";
CM_ SG_ 566 VehCfgPrmExtCCPBytePosn8 "CarConfigExtended BytePos8";
CM_ SG_ 667 ChrgLidAcSts "ChrgLidAcSts - Charge lid for Alternating current
Ukwn - Unknown status
Opend - Opened
Clsd - Closed";
CM_ SG_ 667 DrvModReq "drive mode";
CM_ SG_ 667 MaxAcInpCurrentSet "set the input current";
CM_ SG_ 49 ChrgLidDCorAcDcSts "ChrgLidDCorAcDcSts - Charge lid Directc current OR Alternating current and  Direct current
Ukwn - Unknown status
Opend - Opened
Clsd - Closed";
CM_ SG_ 1051 AmbTEstimdAmbTEstimd "Estimated/filtered/modelled amibient temperature based on information from ambient temp sensor and all other available temperature sensors and vehicle information.  Estimated ambient temperature";
CM_ SG_ 1051 AmbTEstimdQf "Estimated/filtered/modelled amibient temperature based on information from ambient temp sensor and all other available temperature sensors and vehicle information.  Quality factor for estimated signal";
CM_ SG_ 304 PtActrReModReq "Powertrain actuator mode request.
0=No request
1=Disable active damping
2=Reduce actuator inertia
3=Reduce actuator inertia and disable active damping";
CM_ SG_ 1143 VinBlockNr "VIN number block counter. ";
CM_ SG_ 1143 VinVINSignalPos1 "VIN byte 1. Used for character 1, 8 and 15.";
CM_ SG_ 1143 VinVINSignalPos2 "VIN byte 2. Used for character 2, 9 and 16.";
CM_ SG_ 1143 VinVINSignalPos3 "VIN byte 3. Used for character 3, 10 and 17.";
CM_ SG_ 1143 VinVINSignalPos4 "VIN byte 4. Used for character 4 and 11.";
CM_ SG_ 1143 VinVINSignalPos5 "VIN byte 5. Used for character 5 and 12.";
CM_ SG_ 1143 VinVINSignalPos6 "VIN byte 6. Used for character 6 and 13.";
CM_ SG_ 1143 VinVINSignalPos7 "VIN byte 7. Used for character 7 and 14.";
CM_ SG_ 375 BattPreHeatgTiDif "Time difference between the current time and the departure time";
CM_ SG_ 819 GpsStatus "GPS signal confidence, successful=1 or failure=0. ";
CM_ SG_ 819 UTCTiFromEthDataValid "GPS signal confidence, successful=1 or failure=0. ";
CM_ SG_ 819 UTCTiFromEthDay "UTC time of Day";
CM_ SG_ 819 UTCTiFromEthHr1 "UTC time of Hour";
CM_ SG_ 819 UTCTiFromEthMins1 "UTC time of Minute";
CM_ SG_ 819 UTCTiFromEthMth1 "UTC time of Month";
CM_ SG_ 819 UTCTiFromEthSec1 "UTC time of Second";
CM_ SG_ 819 UTCTiFromEthYr1 "UTC time of year";
CM_ SG_ 57 DoorDrvrLockSts "DoorDrvrLockSts - Driver Door Lock Status
Lock status
LockStsUkwn - Lock Status Unknown
Unlckd - Unlocked
Lockd - Locked
SafeLockd - Safe Locked (Double Locked)";
CM_ SG_ 279 BookChrgnActvdReq "Book Charging ACtivted Request";
CM_ SG_ 279 BookStopTiAchieved "Stop charging time Achieved";
CM_ SG_ 279 ChrgnCtrlToEndOrRetartFromApp "this signal is use for end DC or AC charging control  and use for  end discharging control ";
CM_ SG_ 279 ChrgNowReq "Charge immediately button reqest";
CM_ SG_ 279 ChrgSoftSwCtrlSt "sofware control state";
CM_ SG_ 279 TelmBookChrgnReq "Telm Book Chrgn Request form APP";
CM_ SG_ 568 ActvnOfSymIllmn "PWM signal to control vehicle switches symbol background illumination.";
CM_ SG_ 786 OnBdDiagLostCom "The signal is a heartbeat between the node connected to the OBD connector and the OBD Master.";
CM_ SG_ 563 Edcp2PmpCmdCooltPmpPostRunReq "Coolant pump post run request.";
CM_ SG_ 563 Edcp2PmpCmdCooltPmpSpdReq "Coolant pump speed request.";
CM_ SG_ 563 EexvPosnReqExvCalibReq "Eexv calibration request.";
CM_ SG_ 563 EexvPosnReqExvHeatdReq "Eexv heating request.";
CM_ SG_ 563 EexvPosnReqExvMovEnable "Eexv move enable.";
CM_ SG_ 563 EexvPosnReqExvPosnReq "Eexv postion request.";
CM_ SG_ 563 ExvPosnReqExvCalibReq "EXV calibration request.";
CM_ SG_ 563 ExvPosnReqExvHeatdReq "EXV heating request.";
CM_ SG_ 563 ExvPosnReqExvMovEnable "EXV move enable.";
CM_ SG_ 563 ExvPosnReqExvPosnReq "EXV position request.";
CM_ SG_ 563 HeatrPmpCmdCooltPmpPostRunReq "Coolant pump post run request.";
CM_ SG_ 563 HeatrPmpCmdCooltPmpSpdReq "Coolant pump speed request.";
CM_ SG_ 563 HvBattPmpCmdCooltPmpPostRunReq "Coolant pump post run request";
CM_ SG_ 563 HvBattPmpCmdCooltPmpSpdReq "Coolant pump speed request";
CM_ SG_ 633 CcvmCmdVlvActvSaveReq "Valve save position request before power off.";
CM_ SG_ 633 CcvmCmdVlvCalibReq "Valve calibration request.";
CM_ SG_ 633 CcvmCmdVlvHeatdReq "Valve heating request.";
CM_ SG_ 633 CcvmCmdVlvMovEna "Valve move enable";
CM_ SG_ 633 CcvmCmdVlvPosn "Valve position set request.";
CM_ SG_ 633 CcvmCmdVlvSpdLvlReq "Valve speed level request.";
CM_ SG_ 633 CcvPosReqDftPos "Valve Default Position";
CM_ SG_ 633 CcvPosReqPosReq "Valve Position Request";
CM_ SG_ 633 CcvPosReqReqEnad "Valve Request Move Enable";
CM_ SG_ 633 CcvPosReqRstPos "Valve Reset Position Request";
CM_ SG_ 633 CcvPosReqTrqReq "Valve Torque Request";
CM_ SG_ 633 HctvCmdVlvActvSaveReq "Valve save position request before power off.";
CM_ SG_ 633 HctvCmdVlvCalibReq "Valve calibration request.";
CM_ SG_ 633 HctvCmdVlvHeatdReq "Valve heating request.";
CM_ SG_ 633 HctvCmdVlvMovEna "Valve move enable";
CM_ SG_ 633 HctvCmdVlvPosn "Valve position set request.";
CM_ SG_ 633 HctvCmdVlvSpdLvlReq "Valve speed level request.";
CM_ SG_ 1156 ACAndThermCnsDrvCyc "The cumulative power consumption of air conditioning and thermal management during this driving cycle";
CM_ SG_ 1156 PTMPwrSaveDrvCyc "Power savings in the current driving cycle with predictive thermal management function";
CM_ SG_ 1156 PTMStateVeh "Intelligent thermal management function status";
CM_ SG_ 1152 BattChrgnDrvCyc "The cumulative input power of the high-voltage battery in this driving cycle";
CM_ SG_ 1152 PTMTotPwrSaveAmnt "Total power savings from predictive thermal management function";
CM_ SG_ 1173 BattDchaDrvCyc "The cumulative output power of the high-voltage battery in this driving cycle";
CM_ SG_ 1312 WakeUpReasonsforXCU "WakeUpReasons";
CM_ SG_ 1376 VFCVectorXCUBlockID "BlockID";
CM_ SG_ 1376 VFCVectorXCUVFCid0 "SettingsComfort";
CM_ SG_ 1376 VFCVectorXCUVFCid1 "ParkingDrivingClimatization";
CM_ SG_ 1376 VFCVectorXCUVFCid10 "ExteriorLighting";
CM_ SG_ 1376 VFCVectorXCUVFCid11 "VFC11";
CM_ SG_ 1376 VFCVectorXCUVFCid12 "Alarm";
CM_ SG_ 1376 VFCVectorXCUVFCid13 "VFC13";
CM_ SG_ 1376 VFCVectorXCUVFCid14 "InteriorLighting";
CM_ SG_ 1376 VFCVectorXCUVFCid15 "VFC15";
CM_ SG_ 1376 VFCVectorXCUVFCid16 "Locking";
CM_ SG_ 1376 VFCVectorXCUVFCid17 "RemoteKeyFunctionality";
CM_ SG_ 1376 VFCVectorXCUVFCid18 "PropulsionStart";
CM_ SG_ 1376 VFCVectorXCUVFCid19 "VFC19";
CM_ SG_ 1376 VFCVectorXCUVFCid2 "PostClimatisation";
CM_ SG_ 1376 VFCVectorXCUVFCid20 "VFC20";
CM_ SG_ 1376 VFCVectorXCUVFCid21 "PowerClosures";
CM_ SG_ 1376 VFCVectorXCUVFCid22 "VehicleDriving";
CM_ SG_ 1376 VFCVectorXCUVFCid23 "VFC23";
CM_ SG_ 1376 VFCVectorXCUVFCid24 "SettingsProfile";
CM_ SG_ 1376 VFCVectorXCUVFCid25 "SeatComfortFunctions";
CM_ SG_ 1376 VFCVectorXCUVFCid26 "Brake";
CM_ SG_ 1376 VFCVectorXCUVFCid27 "InfotainmentPoll";
CM_ SG_ 1376 VFCVectorXCUVFCid28 "HVEnergyStorage";
CM_ SG_ 1376 VFCVectorXCUVFCid29 "VFC29";
CM_ SG_ 1376 VFCVectorXCUVFCid3 "PowertrainParkingClimatization";
CM_ SG_ 1376 VFCVectorXCUVFCid30 "TelematicsConnectivity";
CM_ SG_ 1376 VFCVectorXCUVFCid31 "VFC31";
CM_ SG_ 1376 VFCVectorXCUVFCid32 "VFC32";
CM_ SG_ 1376 VFCVectorXCUVFCid33 "Diagnostics";
CM_ SG_ 1376 VFCVectorXCUVFCid34 "VehicleModeManagement";
CM_ SG_ 1376 VFCVectorXCUVFCid35 "TrailerCaravanFunctions";
CM_ SG_ 1376 VFCVectorXCUVFCid36 "Immobilizer";
CM_ SG_ 1376 VFCVectorXCUVFCid37 "Windows";
CM_ SG_ 1376 VFCVectorXCUVFCid38 "Visibility";
CM_ SG_ 1376 VFCVectorXCUVFCid39 "VFC39";
CM_ SG_ 1376 VFCVectorXCUVFCid4 "VFC4";
CM_ SG_ 1376 VFCVectorXCUVFCid40 "VFC40";
CM_ SG_ 1376 VFCVectorXCUVFCid41 "InfotainmentPush";
CM_ SG_ 1376 VFCVectorXCUVFCid42 "ChargingHV";
CM_ SG_ 1376 VFCVectorXCUVFCid43 "BodyPreClimatisation";
CM_ SG_ 1376 VFCVectorXCUVFCid44 "Crash";
CM_ SG_ 1376 VFCVectorXCUVFCid45 "GlobalShortDuration";
CM_ SG_ 1376 VFCVectorXCUVFCid46 "ExteriorLightsHazard";
CM_ SG_ 1376 VFCVectorXCUVFCid47 "VFC47";
CM_ SG_ 1376 VFCVectorXCUVFCid48 "DoorOpenWarning";
CM_ SG_ 1376 VFCVectorXCUVFCid49 "ChargingLVInit";
CM_ SG_ 1376 VFCVectorXCUVFCid5 "VFC5";
CM_ SG_ 1376 VFCVectorXCUVFCid50 "VFC50";
CM_ SG_ 1376 VFCVectorXCUVFCid51 "VFC51";
CM_ SG_ 1376 VFCVectorXCUVFCid52 "HVBatteryThermalEventWarning";
CM_ SG_ 1376 VFCVectorXCUVFCid53 "VisualAssist";
CM_ SG_ 1376 VFCVectorXCUVFCid54 "PassiveSafety";
CM_ SG_ 1376 VFCVectorXCUVFCid55 "LifeDetection";
CM_ SG_ 1376 VFCVectorXCUVFCid56 "BackboneFlexray";
CM_ SG_ 1376 VFCVectorXCUVFCid57 "Functionmarket";
CM_ SG_ 1376 VFCVectorXCUVFCid58 "VFC58";
CM_ SG_ 1376 VFCVectorXCUVFCid59 "VFC59";
CM_ SG_ 1376 VFCVectorXCUVFCid6 "SettingsVehicle";
CM_ SG_ 1376 VFCVectorXCUVFCid60 "VFC60";
CM_ SG_ 1376 VFCVectorXCUVFCid61 "VFC61";
CM_ SG_ 1376 VFCVectorXCUVFCid7 "VFC7";
CM_ SG_ 1376 VFCVectorXCUVFCid8 "VFC8";
CM_ SG_ 1376 VFCVectorXCUVFCid9 "IPWakeup";
CM_ SG_ 1349 VFCVectorZCUDMBlockID "BlockID";
CM_ SG_ 1349 VFCVectorZCUDMVFCid0 "SettingsComfort";
CM_ SG_ 1349 VFCVectorZCUDMVFCid1 "ParkingDrivingClimatization";
CM_ SG_ 1349 VFCVectorZCUDMVFCid10 "ExteriorLighting";
CM_ SG_ 1349 VFCVectorZCUDMVFCid11 "VFC11";
CM_ SG_ 1349 VFCVectorZCUDMVFCid12 "Alarm";
CM_ SG_ 1349 VFCVectorZCUDMVFCid13 "VFC13";
CM_ SG_ 1349 VFCVectorZCUDMVFCid14 "InteriorLighting";
CM_ SG_ 1349 VFCVectorZCUDMVFCid15 "VFC15";
CM_ SG_ 1349 VFCVectorZCUDMVFCid16 "Locking";
CM_ SG_ 1349 VFCVectorZCUDMVFCid17 "RemoteKeyFunctionality";
CM_ SG_ 1349 VFCVectorZCUDMVFCid18 "PropulsionStart";
CM_ SG_ 1349 VFCVectorZCUDMVFCid19 "VFC19";
CM_ SG_ 1349 VFCVectorZCUDMVFCid2 "PostClimatisation";
CM_ SG_ 1349 VFCVectorZCUDMVFCid20 "VFC20";
CM_ SG_ 1349 VFCVectorZCUDMVFCid21 "PowerClosures";
CM_ SG_ 1349 VFCVectorZCUDMVFCid22 "VehicleDriving";
CM_ SG_ 1349 VFCVectorZCUDMVFCid23 "VFC23";
CM_ SG_ 1349 VFCVectorZCUDMVFCid24 "SettingsProfile";
CM_ SG_ 1349 VFCVectorZCUDMVFCid25 "SeatComfortFunctions";
CM_ SG_ 1349 VFCVectorZCUDMVFCid26 "Brake";
CM_ SG_ 1349 VFCVectorZCUDMVFCid27 "InfotainmentPoll";
CM_ SG_ 1349 VFCVectorZCUDMVFCid28 "HVEnergyStorage";
CM_ SG_ 1349 VFCVectorZCUDMVFCid29 "VFC29";
CM_ SG_ 1349 VFCVectorZCUDMVFCid3 "PowertrainParkingClimatization";
CM_ SG_ 1349 VFCVectorZCUDMVFCid30 "TelematicsConnectivity";
CM_ SG_ 1349 VFCVectorZCUDMVFCid31 "VFC31";
CM_ SG_ 1349 VFCVectorZCUDMVFCid32 "VFC32";
CM_ SG_ 1349 VFCVectorZCUDMVFCid33 "Diagnostics";
CM_ SG_ 1349 VFCVectorZCUDMVFCid34 "VehicleModeManagement";
CM_ SG_ 1349 VFCVectorZCUDMVFCid35 "TrailerCaravanFunctions";
CM_ SG_ 1349 VFCVectorZCUDMVFCid36 "Immobilizer";
CM_ SG_ 1349 VFCVectorZCUDMVFCid37 "Windows";
CM_ SG_ 1349 VFCVectorZCUDMVFCid38 "Visibility";
CM_ SG_ 1349 VFCVectorZCUDMVFCid39 "VFC39";
CM_ SG_ 1349 VFCVectorZCUDMVFCid4 "VFC4";
CM_ SG_ 1349 VFCVectorZCUDMVFCid40 "VFC40";
CM_ SG_ 1349 VFCVectorZCUDMVFCid41 "InfotainmentPush";
CM_ SG_ 1349 VFCVectorZCUDMVFCid42 "ChargingHV";
CM_ SG_ 1349 VFCVectorZCUDMVFCid43 "BodyPreClimatisation";
CM_ SG_ 1349 VFCVectorZCUDMVFCid44 "Crash";
CM_ SG_ 1349 VFCVectorZCUDMVFCid45 "GlobalShortDuration";
CM_ SG_ 1349 VFCVectorZCUDMVFCid46 "ExteriorLightsHazard";
CM_ SG_ 1349 VFCVectorZCUDMVFCid47 "VFC47";
CM_ SG_ 1349 VFCVectorZCUDMVFCid48 "DoorOpenWarning";
CM_ SG_ 1349 VFCVectorZCUDMVFCid49 "ChargingLVInit";
CM_ SG_ 1349 VFCVectorZCUDMVFCid5 "VFC5";
CM_ SG_ 1349 VFCVectorZCUDMVFCid50 "VFC50";
CM_ SG_ 1349 VFCVectorZCUDMVFCid51 "VFC51";
CM_ SG_ 1349 VFCVectorZCUDMVFCid52 "HVBatteryThermalEventWarning";
CM_ SG_ 1349 VFCVectorZCUDMVFCid53 "VisualAssist";
CM_ SG_ 1349 VFCVectorZCUDMVFCid54 "PassiveSafety";
CM_ SG_ 1349 VFCVectorZCUDMVFCid55 "LifeDetection";
CM_ SG_ 1349 VFCVectorZCUDMVFCid56 "BackboneFlexray";
CM_ SG_ 1349 VFCVectorZCUDMVFCid57 "Functionmarket";
CM_ SG_ 1349 VFCVectorZCUDMVFCid58 "VFCid58";
CM_ SG_ 1349 VFCVectorZCUDMVFCid59 "VFCid59";
CM_ SG_ 1349 VFCVectorZCUDMVFCid6 "SettingsVehicle";
CM_ SG_ 1349 VFCVectorZCUDMVFCid60 "VFCid60";
CM_ SG_ 1349 VFCVectorZCUDMVFCid61 "VFCid61";
CM_ SG_ 1349 VFCVectorZCUDMVFCid7 "VFC7";
CM_ SG_ 1349 VFCVectorZCUDMVFCid8 "VFC8";
CM_ SG_ 1349 VFCVectorZCUDMVFCid9 "IPWakeup";
CM_ SG_ 1285 WakeUpReasonsforZCUDM "WakeUpReasons";
BA_DEF_ BO_ "GenMsgCycleTime" INT 0 65536;
BA_DEF_ BO_ "GenMsgDelayTime" INT 0 65536;
BA_DEF_ BO_ "GenMsgSendType" ENUM "cyclic", "spontaneous", "not-used", "not-used", "not-used", "cyclicAndSpontaneous", "not-used", "cyclicIfActive", "NoMsgSendType";
BA_DEF_ BO_ "GenMsgStartDelayTime" INT 0 65536;
BA_DEF_ SG_ "GenSigSendType" ENUM "Cyclic","OnWrite","OnWriteWithRepetition","OnChange","OnChangeWithRepetition","IfActive","IfActiveWithRepetition","NoSigSendType";
BA_DEF_ SG_ "GenSigStartValue" HEX 0 80000000;
BA_DEF_ BO_ "GenMsgILSupport" ENUM "No","Yes";
BA_DEF_ BO_ "NmAsrMessage" ENUM "No","Yes";
BA_DEF_ SG_ "GenSigFuncType" ENUM "NoFunction","n/a","n/a","n/a","n/a","n/a","n/a","n/a","n/a","n/a","n/a","n/a","n/a","n/a","n/a","CHK","CNTR","n/a","n/a","n/a","CNTR_AR_01","CRC_AR_01_BOTH","CRC_AR_01_ALT","CRC_AR_01_LOW","CRC_AR_01_NIBBLE","CNTR_AR_04","CRC_AR_04A","CNTR_AR_05","CRC_AR_05";
BA_DEF_ SG_ "GenSigDataID" STRING;
BA_DEF_DEF_ "GenSigStartValue" 0;
BA_DEF_DEF_ "GenSigSendType" "NoSigSendType";
BA_DEF_DEF_ "GenMsgCycleTime" 0;
BA_DEF_DEF_ "GenMsgDelayTime" 0;
BA_DEF_DEF_ "GenMsgStartDelayTime" 0;
BA_DEF_DEF_ "GenMsgSendType" "NoMsgSendType";
BA_DEF_DEF_ "GenMsgILSupport" "Yes";
BA_DEF_DEF_ "NmAsrMessage" "No";
BA_DEF_DEF_ "GenSigFuncType" "NoFunction";
BA_DEF_DEF_ "GenSigDataID" "";

BA_ "GenMsgDelayTime" BO_ 1448 10.000;
BA_ "GenMsgSendType" BO_ 1448 1;

BA_ "GenMsgDelayTime" BO_ 1447 10.000;
BA_ "GenMsgSendType" BO_ 1447 1;

BA_ "GenMsgDelayTime" BO_ 1449 10.000;
BA_ "GenMsgSendType" BO_ 1449 1;

BA_ "GenMsgDelayTime" BO_ 1450 10.000;
BA_ "GenMsgSendType" BO_ 1450 1;

BA_ "GenMsgDelayTime" BO_ 1451 10.000;
BA_ "GenMsgSendType" BO_ 1451 1;

BA_ "GenMsgDelayTime" BO_ 1452 10.000;
BA_ "GenMsgSendType" BO_ 1452 1;

BA_ "GenMsgCycleTime" BO_ 75 10.000;
BA_ "GenMsgSendType" BO_ 75 0;

BA_ "GenMsgCycleTime" BO_ 634 100.000;
BA_ "GenMsgSendType" BO_ 634 0;

BA_ "GenMsgCycleTime" BO_ 401 70.000;
BA_ "GenMsgSendType" BO_ 401 0;

BA_ "GenMsgCycleTime" BO_ 278 20.000;
BA_ "GenMsgSendType" BO_ 278 0;

BA_ "GenMsgCycleTime" BO_ 569 150.000;
BA_ "GenMsgSendType" BO_ 569 0;

BA_ "GenMsgCycleTime" BO_ 649 100.000;
BA_ "GenMsgSendType" BO_ 649 0;

BA_ "GenMsgCycleTime" BO_ 309 20.000;
BA_ "GenMsgSendType" BO_ 309 0;

BA_ "GenMsgCycleTime" BO_ 310 20.000;
BA_ "GenMsgSendType" BO_ 310 0;

BA_ "GenMsgDelayTime" BO_ 1302 20.000;
BA_ "GenMsgSendType" BO_ 1302 1;

BA_ "GenMsgCycleTime" BO_ 1366 500.000;
BA_ "GenMsgSendType" BO_ 1366 0;

BA_ "GenMsgDelayTime" BO_ 1587 5.000;
BA_ "GenMsgSendType" BO_ 1587 1;

BA_ "GenMsgDelayTime" BO_ 1410 5.000;
BA_ "GenMsgSendType" BO_ 1410 1;

BA_ "GenMsgDelayTime" BO_ 1412 5.000;
BA_ "GenMsgSendType" BO_ 1412 1;

BA_ "GenMsgDelayTime" BO_ 1418 5.000;
BA_ "GenMsgSendType" BO_ 1418 1;

BA_ "GenMsgCycleTime" BO_ 314 20.000;
BA_ "GenMsgSendType" BO_ 314 0;

BA_ "GenMsgCycleTime" BO_ 342 20.000;
BA_ "GenMsgSendType" BO_ 342 0;

BA_ "GenMsgCycleTime" BO_ 149 10.000;
BA_ "GenMsgSendType" BO_ 149 0;

BA_ "GenMsgCycleTime" BO_ 391 100.000;
BA_ "GenMsgSendType" BO_ 391 0;

BA_ "GenMsgCycleTime" BO_ 593 200.000;
BA_ "GenMsgSendType" BO_ 593 0;

BA_ "GenMsgCycleTime" BO_ 299 20.000;
BA_ "GenMsgSendType" BO_ 299 0;

BA_ "GenMsgCycleTime" BO_ 53 200.000;
BA_ "GenMsgDelayTime" BO_ 53 10.000;
BA_ "GenMsgSendType" BO_ 53 5;

BA_ "GenMsgCycleTime" BO_ 681 250.000;
BA_ "GenMsgSendType" BO_ 681 0;

BA_ "GenMsgCycleTime" BO_ 678 250.000;
BA_ "GenMsgSendType" BO_ 678 0;

BA_ "GenMsgCycleTime" BO_ 684 250.000;
BA_ "GenMsgSendType" BO_ 684 0;

BA_ "GenMsgCycleTime" BO_ 1057 1000.000;
BA_ "GenMsgSendType" BO_ 1057 0;

BA_ "GenMsgCycleTime" BO_ 869 450.000;
BA_ "GenMsgSendType" BO_ 869 0;

BA_ "GenMsgCycleTime" BO_ 880 450.000;
BA_ "GenMsgSendType" BO_ 880 0;

BA_ "GenMsgCycleTime" BO_ 672 250.000;
BA_ "GenMsgSendType" BO_ 672 0;

BA_ "GenMsgCycleTime" BO_ 675 250.000;
BA_ "GenMsgSendType" BO_ 675 0;

BA_ "GenMsgDelayTime" BO_ 1336 20.000;
BA_ "GenMsgSendType" BO_ 1336 1;

BA_ "GenMsgDelayTime" BO_ 1595 5.000;
BA_ "GenMsgSendType" BO_ 1595 1;

BA_ "GenMsgDelayTime" BO_ 1770 5.000;
BA_ "GenMsgSendType" BO_ 1770 1;

BA_ "GenMsgDelayTime" BO_ 1771 5.000;
BA_ "GenMsgSendType" BO_ 1771 1;

BA_ "GenMsgCycleTime" BO_ 377 100.000;
BA_ "GenMsgSendType" BO_ 377 0;

BA_ "GenMsgCycleTime" BO_ 337 30.000;
BA_ "GenMsgSendType" BO_ 337 0;

BA_ "GenMsgCycleTime" BO_ 302 20.000;
BA_ "GenMsgSendType" BO_ 302 0;

BA_ "GenMsgCycleTime" BO_ 118 15.000;
BA_ "GenMsgSendType" BO_ 118 0;

BA_ "GenMsgDelayTime" BO_ 565 120.000;
BA_ "GenMsgSendType" BO_ 565 1;

BA_ "GenMsgCycleTime" BO_ 65 10.000;
BA_ "GenMsgSendType" BO_ 65 0;

BA_ "GenMsgCycleTime" BO_ 129 15.000;
BA_ "GenMsgSendType" BO_ 129 0;

BA_ "GenMsgCycleTime" BO_ 313 25.000;
BA_ "GenMsgSendType" BO_ 313 0;

BA_ "GenMsgCycleTime" BO_ 353 25.000;
BA_ "GenMsgSendType" BO_ 353 0;

BA_ "GenMsgCycleTime" BO_ 609 80.000;
BA_ "GenMsgSendType" BO_ 609 0;

BA_ "GenMsgCycleTime" BO_ 597 80.000;
BA_ "GenMsgSendType" BO_ 597 0;

BA_ "GenMsgCycleTime" BO_ 354 50.000;
BA_ "GenMsgSendType" BO_ 354 0;

BA_ "GenMsgCycleTime" BO_ 86 15.000;
BA_ "GenMsgSendType" BO_ 86 0;

BA_ "GenMsgCycleTime" BO_ 645 200.000;
BA_ "GenMsgSendType" BO_ 645 0;

BA_ "GenMsgDelayTime" BO_ 566 120.000;
BA_ "GenMsgSendType" BO_ 566 1;

BA_ "GenMsgCycleTime" BO_ 667 200.000;
BA_ "GenMsgSendType" BO_ 667 0;

BA_ "GenMsgCycleTime" BO_ 49 15.000;
BA_ "GenMsgSendType" BO_ 49 0;

BA_ "GenMsgCycleTime" BO_ 1051 500.000;
BA_ "GenMsgSendType" BO_ 1051 0;

BA_ "GenMsgCycleTime" BO_ 304 30.000;
BA_ "GenMsgSendType" BO_ 304 0;

BA_ "GenMsgDelayTime" BO_ 1143 120.000;
BA_ "GenMsgSendType" BO_ 1143 1;

BA_ "GenMsgDelayTime" BO_ 375 80.000;
BA_ "GenMsgSendType" BO_ 375 1;

BA_ "GenMsgCycleTime" BO_ 819 1000.000;
BA_ "GenMsgSendType" BO_ 819 0;

BA_ "GenMsgCycleTime" BO_ 57 10.000;
BA_ "GenMsgSendType" BO_ 57 0;

BA_ "GenMsgDelayTime" BO_ 279 20.000;
BA_ "GenMsgSendType" BO_ 279 1;

BA_ "GenMsgCycleTime" BO_ 568 160.000;
BA_ "GenMsgSendType" BO_ 568 0;

BA_ "GenMsgCycleTime" BO_ 282 20.000;
BA_ "GenMsgSendType" BO_ 282 0;

BA_ "GenMsgCycleTime" BO_ 786 600.000;
BA_ "GenMsgSendType" BO_ 786 0;

BA_ "GenMsgDelayTime" BO_ 2020 5.000;
BA_ "GenMsgSendType" BO_ 2020 1;

BA_ "GenMsgCycleTime" BO_ 563 160.000;
BA_ "GenMsgSendType" BO_ 563 0;

BA_ "GenMsgCycleTime" BO_ 633 300.000;
BA_ "GenMsgSendType" BO_ 633 0;

BA_ "GenMsgCycleTime" BO_ 1156 1000.000;
BA_ "GenMsgSendType" BO_ 1156 0;

BA_ "GenMsgCycleTime" BO_ 1152 1000.000;
BA_ "GenMsgSendType" BO_ 1152 0;

BA_ "GenMsgCycleTime" BO_ 1173 1000.000;
BA_ "GenMsgSendType" BO_ 1173 0;

BA_ "GenMsgDelayTime" BO_ 1312 20.000;
BA_ "GenMsgSendType" BO_ 1312 1;

BA_ "GenMsgCycleTime" BO_ 1376 500.000;
BA_ "GenMsgSendType" BO_ 1376 0;

BA_ "GenMsgDelayTime" BO_ 2030 5.000;
BA_ "GenMsgSendType" BO_ 2030 1;

BA_ "GenMsgCycleTime" BO_ 1349 500.000;
BA_ "GenMsgSendType" BO_ 1349 0;

BA_ "GenMsgDelayTime" BO_ 1285 20.000;
BA_ "GenMsgSendType" BO_ 1285 1;
BA_ "GenMsgILSupport" BO_ 1302 0;
BA_ "GenMsgILSupport" BO_ 1336 0;
BA_ "GenMsgILSupport" BO_ 1312 0;
BA_ "GenMsgILSupport" BO_ 1285 0;
BA_ "NmAsrMessage" BO_ 1302 1;
BA_ "NmAsrMessage" BO_ 1336 1;
BA_ "NmAsrMessage" BO_ 1312 1;
BA_ "NmAsrMessage" BO_ 1285 1;
BA_ "GenSigSendType" SG_ 1156 ACAndThermCnsDrvCyc 0;
BA_ "GenSigSendType" SG_ 129 ADataRawSafeALat 0;
BA_ "GenSigSendType" SG_ 129 ADataRawSafeALat1Qf 0;
BA_ "GenSigStartValue" SG_ 129 ADataRawSafeALat1Qf 1;
BA_ "GenSigSendType" SG_ 129 ADataRawSafeALgt 0;
BA_ "GenSigSendType" SG_ 129 ADataRawSafeALgt1Qf 0;
BA_ "GenSigStartValue" SG_ 129 ADataRawSafeALgt1Qf 1;
BA_ "GenSigSendType" SG_ 129 ADataRawSafeAVert 0;
BA_ "GenSigStartValue" SG_ 129 ADataRawSafeAVert 1155;
BA_ "GenSigSendType" SG_ 129 ADataRawSafeAVertQf 0;
BA_ "GenSigStartValue" SG_ 129 ADataRawSafeAVertQf 1;
BA_ "GenSigDataID" SG_ 129 ADataRawSafeChks "0x22";
BA_ "GenSigFuncType" SG_ 129 ADataRawSafeChks 15;
BA_ "GenSigSendType" SG_ 129 ADataRawSafeChks 0;
BA_ "GenSigStartValue" SG_ 129 ADataRawSafeChks 255;
BA_ "GenSigFuncType" SG_ 129 ADataRawSafeCntr 16;
BA_ "GenSigSendType" SG_ 129 ADataRawSafeCntr 0;
BA_ "GenSigSendType" SG_ 278 AccrPedlPsdAccrPedlPsd 0;
BA_ "GenSigDataID" SG_ 278 AccrPedlPsdChks "0x48";
BA_ "GenSigFuncType" SG_ 278 AccrPedlPsdChks 15;
BA_ "GenSigSendType" SG_ 278 AccrPedlPsdChks 0;
BA_ "GenSigStartValue" SG_ 278 AccrPedlPsdChks 255;
BA_ "GenSigFuncType" SG_ 278 AccrPedlPsdCntr 16;
BA_ "GenSigSendType" SG_ 278 AccrPedlPsdCntr 0;
BA_ "GenSigSendType" SG_ 278 AccrPedlPsdSts 0;
BA_ "GenSigSendType" SG_ 568 ActvnOfSymIllmn 0;
BA_ "GenSigSendType" SG_ 1051 AmbTEstimdAmbTEstimd 0;
BA_ "GenSigStartValue" SG_ 1051 AmbTEstimdAmbTEstimd 700;
BA_ "GenSigSendType" SG_ 1051 AmbTEstimdQf 0;
BA_ "GenSigSendType" SG_ 645 AmbTRawAmbTVal 0;
BA_ "GenSigStartValue" SG_ 645 AmbTRawAmbTVal 700;
BA_ "GenSigSendType" SG_ 645 AmbTRawQly 0;
BA_ "GenSigSendType" SG_ 1152 BattChrgnDrvCyc 0;
BA_ "GenSigSendType" SG_ 1173 BattDchaDrvCyc 0;
BA_ "GenSigSendType" SG_ 609 BattPreHeatgLvl 1;
BA_ "GenSigSendType" SG_ 375 BattPreHeatgTiDif 1;
BA_ "GenSigSendType" SG_ 1057 BexvNVMFltFromTMCU 0;
BA_ "GenSigSendType" SG_ 569 BexvPosnReqExvCalibReq 0;
BA_ "GenSigSendType" SG_ 569 BexvPosnReqExvHeatdReq 0;
BA_ "GenSigSendType" SG_ 569 BexvPosnReqExvMovEnable 0;
BA_ "GenSigSendType" SG_ 569 BexvPosnReqExvPosnReq 0;
BA_ "GenSigSendType" SG_ 672 BexvStsFromTMCUExvActrPosn 0;
BA_ "GenSigSendType" SG_ 672 BexvStsFromTMCUExvBlkErr 0;
BA_ "GenSigSendType" SG_ 672 BexvStsFromTMCUExvCalibSts 0;
BA_ "GenSigSendType" SG_ 672 BexvStsFromTMCUExvElecStsErr 0;
BA_ "GenSigSendType" SG_ 672 BexvStsFromTMCUExvMovSts 0;
BA_ "GenSigSendType" SG_ 672 BexvStsFromTMCUExvOvrTempErr 0;
BA_ "GenSigSendType" SG_ 672 BexvStsFromTMCUExvOvrTrvlErr 0;
BA_ "GenSigSendType" SG_ 672 BexvStsFromTMCUExvPreHeatgSts 0;
BA_ "GenSigSendType" SG_ 672 BexvStsFromTMCUExvVoltgRangErr 0;
BA_ "GenSigSendType" SG_ 645 BkpOfDstTrvld 0;
BA_ "GenSigSendType" SG_ 279 BookChrgnActvdReq 1;
BA_ "GenSigSendType" SG_ 279 BookStopTiAchieved 1;
BA_ "GenSigSendType" SG_ 118 BrkPedlPsdBrkPedlNotPsdSafe 0;
BA_ "GenSigSendType" SG_ 118 BrkPedlPsdBrkPedlPsd 0;
BA_ "GenSigDataID" SG_ 118 BrkPedlPsdChks "0x38";
BA_ "GenSigFuncType" SG_ 118 BrkPedlPsdChks 15;
BA_ "GenSigSendType" SG_ 118 BrkPedlPsdChks 0;
BA_ "GenSigFuncType" SG_ 118 BrkPedlPsdCntr 16;
BA_ "GenSigSendType" SG_ 118 BrkPedlPsdCntr 0;
BA_ "GenSigSendType" SG_ 118 BrkPedlPsdQf 0;
BA_ "GenSigSendType" SG_ 354 CarTiGlb 0;
BA_ "GenSigSendType" SG_ 633 CcvPosReqDftPos 0;
BA_ "GenSigSendType" SG_ 633 CcvPosReqPosReq 0;
BA_ "GenSigSendType" SG_ 633 CcvPosReqReqEnad 0;
BA_ "GenSigSendType" SG_ 633 CcvPosReqRstPos 0;
BA_ "GenSigSendType" SG_ 633 CcvPosReqTrqReq 0;
BA_ "GenSigSendType" SG_ 880 CcvVlvSts2PosStsFromTMCU 0;
BA_ "GenSigStartValue" SG_ 880 CcvVlvSts2PosStsFromTMCU 170.6666634;
BA_ "GenSigSendType" SG_ 880 CcvVlvStsFromTMCUARC 0;
BA_ "GenSigSendType" SG_ 880 CcvVlvStsFromTMCUIntFlt 0;
BA_ "GenSigSendType" SG_ 880 CcvVlvStsFromTMCUOprFlt 0;
BA_ "GenSigSendType" SG_ 880 CcvVlvStsFromTMCUTrqSts 0;
BA_ "GenSigSendType" SG_ 633 CcvmCmdVlvActvSaveReq 0;
BA_ "GenSigSendType" SG_ 633 CcvmCmdVlvCalibReq 0;
BA_ "GenSigSendType" SG_ 633 CcvmCmdVlvHeatdReq 0;
BA_ "GenSigSendType" SG_ 633 CcvmCmdVlvMovEna 0;
BA_ "GenSigSendType" SG_ 633 CcvmCmdVlvPosn 0;
BA_ "GenSigSendType" SG_ 633 CcvmCmdVlvSpdLvlReq 0;
BA_ "GenSigSendType" SG_ 869 CcvmStsFromTMCUVlvBlkFlt 0;
BA_ "GenSigSendType" SG_ 869 CcvmStsFromTMCUVlvCalibSts 0;
BA_ "GenSigSendType" SG_ 869 CcvmStsFromTMCUVlvCmdPosnErr 0;
BA_ "GenSigSendType" SG_ 869 CcvmStsFromTMCUVlvLoTErr 0;
BA_ "GenSigSendType" SG_ 869 CcvmStsFromTMCUVlvMoveSts 0;
BA_ "GenSigSendType" SG_ 869 CcvmStsFromTMCUVlvNVMFlt 0;
BA_ "GenSigSendType" SG_ 869 CcvmStsFromTMCUVlvOpenCircFlt 0;
BA_ "GenSigSendType" SG_ 869 CcvmStsFromTMCUVlvOverTErr 0;
BA_ "GenSigSendType" SG_ 869 CcvmStsFromTMCUVlvOverTWarn 0;
BA_ "GenSigSendType" SG_ 869 CcvmStsFromTMCUVlvOverTrvlFlt 0;
BA_ "GenSigSendType" SG_ 869 CcvmStsFromTMCUVlvOverUErr 0;
BA_ "GenSigSendType" SG_ 869 CcvmStsFromTMCUVlvPosn 0;
BA_ "GenSigSendType" SG_ 869 CcvmStsFromTMCUVlvPosnCtrlTimeOutFlt 0;
BA_ "GenSigSendType" SG_ 869 CcvmStsFromTMCUVlvPosnUkwnFlt 0;
BA_ "GenSigSendType" SG_ 869 CcvmStsFromTMCUVlvPreHeatgSts 0;
BA_ "GenSigSendType" SG_ 869 CcvmStsFromTMCUVlvSelfLearnFlt 0;
BA_ "GenSigSendType" SG_ 869 CcvmStsFromTMCUVlvShoCircFlt 0;
BA_ "GenSigSendType" SG_ 869 CcvmStsFromTMCUVlvSpdLvlSts 0;
BA_ "GenSigSendType" SG_ 869 CcvmStsFromTMCUVlvUnderUErr 0;
BA_ "GenSigSendType" SG_ 667 ChrgLidAcSts 0;
BA_ "GenSigSendType" SG_ 49 ChrgLidDCorAcDcSts 0;
BA_ "GenSigSendType" SG_ 279 ChrgNowReq 1;
BA_ "GenSigSendType" SG_ 279 ChrgSoftSwCtrlSt 1;
BA_ "GenSigSendType" SG_ 279 ChrgnCtrlToEndOrRetartFromApp 1;
BA_ "GenSigSendType" SG_ 86 ChrgnUReq 0;
BA_ "GenSigSendType" SG_ 86 CnclBookTrvlReq 1;
BA_ "GenSigDataID" SG_ 53 CrashStsSafeChks "0x40B";
BA_ "GenSigFuncType" SG_ 53 CrashStsSafeChks 15;
BA_ "GenSigSendType" SG_ 53 CrashStsSafeChks 1;
BA_ "GenSigStartValue" SG_ 53 CrashStsSafeChks 255;
BA_ "GenSigFuncType" SG_ 53 CrashStsSafeCntr 16;
BA_ "GenSigSendType" SG_ 53 CrashStsSafeCntr 1;
BA_ "GenSigSendType" SG_ 53 CrashStsSafeSts 1;
BA_ "GenSigSendType" SG_ 57 DoorDrvrLockSts 0;
BA_ "GenSigSendType" SG_ 667 DrvModReq 0;
BA_ "GenSigSendType" SG_ 634 DrvgCyc 0;
BA_ "GenSigDataID" SG_ 310 DrvrGearShiftDirReq1Chks "0x39";
BA_ "GenSigFuncType" SG_ 310 DrvrGearShiftDirReq1Chks 15;
BA_ "GenSigSendType" SG_ 310 DrvrGearShiftDirReq1Chks 0;
BA_ "GenSigFuncType" SG_ 310 DrvrGearShiftDirReq1Cntr 16;
BA_ "GenSigSendType" SG_ 310 DrvrGearShiftDirReq1Cntr 0;
BA_ "GenSigSendType" SG_ 310 DrvrGearShiftDirReq1DwnDwnTipAut 0;
BA_ "GenSigSendType" SG_ 310 DrvrGearShiftDirReq1DwnTipAut 0;
BA_ "GenSigSendType" SG_ 310 DrvrGearShiftDirReq1PosnAut 0;
BA_ "GenSigSendType" SG_ 310 DrvrGearShiftDirReq1UpTipAut 0;
BA_ "GenSigSendType" SG_ 310 DrvrGearShiftDirReq1UpUpTipAut 0;
BA_ "GenSigDataID" SG_ 310 DrvrGearShiftDirReq2Chks "0x62";
BA_ "GenSigFuncType" SG_ 310 DrvrGearShiftDirReq2Chks 15;
BA_ "GenSigSendType" SG_ 310 DrvrGearShiftDirReq2Chks 0;
BA_ "GenSigFuncType" SG_ 310 DrvrGearShiftDirReq2Cntr 16;
BA_ "GenSigSendType" SG_ 310 DrvrGearShiftDirReq2Cntr 0;
BA_ "GenSigSendType" SG_ 310 DrvrGearShiftDirReq2DwnDwnTipAut 0;
BA_ "GenSigSendType" SG_ 310 DrvrGearShiftDirReq2DwnTipAut 0;
BA_ "GenSigSendType" SG_ 310 DrvrGearShiftDirReq2PosnAut 0;
BA_ "GenSigSendType" SG_ 310 DrvrGearShiftDirReq2UpTipAut 0;
BA_ "GenSigSendType" SG_ 310 DrvrGearShiftDirReq2UpUpTipAut 0;
BA_ "GenSigSendType" SG_ 309 DrvrGearShiftManReqDwnDwnTipReq 0;
BA_ "GenSigSendType" SG_ 309 DrvrGearShiftManReqDwnTipReq 0;
BA_ "GenSigSendType" SG_ 309 DrvrGearShiftManReqSteerWhlDwnReq1 0;
BA_ "GenSigSendType" SG_ 309 DrvrGearShiftManReqSteerWhlUpReq 0;
BA_ "GenSigSendType" SG_ 309 DrvrGearShiftManReqTipReq1 0;
BA_ "GenSigSendType" SG_ 309 DrvrGearShiftManReqUpTipReq1 0;
BA_ "GenSigSendType" SG_ 309 DrvrGearShiftManReqUpUpTipReq 0;
BA_ "GenSigSendType" SG_ 309 DrvrGearShiftParkReq1 0;
BA_ "GenSigDataID" SG_ 309 DrvrGearShiftParkReqChks "0x20F";
BA_ "GenSigFuncType" SG_ 309 DrvrGearShiftParkReqChks 15;
BA_ "GenSigSendType" SG_ 309 DrvrGearShiftParkReqChks 0;
BA_ "GenSigFuncType" SG_ 309 DrvrGearShiftParkReqCntr 16;
BA_ "GenSigSendType" SG_ 309 DrvrGearShiftParkReqCntr 0;
BA_ "GenSigSendType" SG_ 309 DrvrGearShiftParkReqSts 0;
BA_ "GenSigSendType" SG_ 563 Edcp2PmpCmdCooltPmpPostRunReq 0;
BA_ "GenSigSendType" SG_ 563 Edcp2PmpCmdCooltPmpSpdReq 0;
BA_ "GenSigSendType" SG_ 684 Edcp2PmpStsFromTMCUCooltPmpDryErr 0;
BA_ "GenSigSendType" SG_ 684 Edcp2PmpStsFromTMCUCooltPmpEmgyModSts 0;
BA_ "GenSigSendType" SG_ 684 Edcp2PmpStsFromTMCUCooltPmpErrSts 0;
BA_ "GenSigSendType" SG_ 684 Edcp2PmpStsFromTMCUCooltPmpI 0;
BA_ "GenSigSendType" SG_ 684 Edcp2PmpStsFromTMCUCooltPmpIErr 0;
BA_ "GenSigSendType" SG_ 684 Edcp2PmpStsFromTMCUCooltPmpMonrSpd 0;
BA_ "GenSigSendType" SG_ 684 Edcp2PmpStsFromTMCUCooltPmpPostRunSts 0;
BA_ "GenSigSendType" SG_ 684 Edcp2PmpStsFromTMCUCooltPmpSetPostRunReq 0;
BA_ "GenSigSendType" SG_ 684 Edcp2PmpStsFromTMCUCooltPmpSetSpdReq 0;
BA_ "GenSigSendType" SG_ 684 Edcp2PmpStsFromTMCUCooltPmpSpd 0;
BA_ "GenSigSendType" SG_ 684 Edcp2PmpStsFromTMCUCooltPmpT 0;
BA_ "GenSigStartValue" SG_ 684 Edcp2PmpStsFromTMCUCooltPmpT 100;
BA_ "GenSigSendType" SG_ 684 Edcp2PmpStsFromTMCUCooltPmpTErr 0;
BA_ "GenSigSendType" SG_ 684 Edcp2PmpStsFromTMCUCooltPmpU 0;
BA_ "GenSigSendType" SG_ 684 Edcp2PmpStsFromTMCUCooltPmpUErr 0;
BA_ "GenSigSendType" SG_ 684 Edcp2PmpStsFromTMCUCooltPmpUnstallSts 0;
BA_ "GenSigSendType" SG_ 1057 EexvNVMFltFromTMCU 0;
BA_ "GenSigSendType" SG_ 563 EexvPosnReqExvCalibReq 0;
BA_ "GenSigSendType" SG_ 563 EexvPosnReqExvHeatdReq 0;
BA_ "GenSigSendType" SG_ 563 EexvPosnReqExvMovEnable 0;
BA_ "GenSigSendType" SG_ 563 EexvPosnReqExvPosnReq 0;
BA_ "GenSigSendType" SG_ 672 EexvStsFromTMCUExvActrPosn 0;
BA_ "GenSigSendType" SG_ 672 EexvStsFromTMCUExvBlkErr 0;
BA_ "GenSigSendType" SG_ 672 EexvStsFromTMCUExvCalibSts 0;
BA_ "GenSigSendType" SG_ 672 EexvStsFromTMCUExvElecStsErr 0;
BA_ "GenSigSendType" SG_ 672 EexvStsFromTMCUExvMovSts 0;
BA_ "GenSigSendType" SG_ 672 EexvStsFromTMCUExvOvrTempErr 0;
BA_ "GenSigSendType" SG_ 672 EexvStsFromTMCUExvOvrTrvlErr 0;
BA_ "GenSigSendType" SG_ 672 EexvStsFromTMCUExvPreHeatgSts 0;
BA_ "GenSigSendType" SG_ 672 EexvStsFromTMCUExvVoltgRangErr 0;
BA_ "GenSigDataID" SG_ 75 EngSt1WdStsChks "0x89";
BA_ "GenSigFuncType" SG_ 75 EngSt1WdStsChks 15;
BA_ "GenSigSendType" SG_ 75 EngSt1WdStsChks 0;
BA_ "GenSigFuncType" SG_ 75 EngSt1WdStsCntr 16;
BA_ "GenSigSendType" SG_ 75 EngSt1WdStsCntr 0;
BA_ "GenSigSendType" SG_ 75 EngSt1WdStsEngSt1WdSts 0;
BA_ "GenSigDataID" SG_ 302 EscVariantToDmcChks "0x19A4";
BA_ "GenSigFuncType" SG_ 302 EscVariantToDmcChks 15;
BA_ "GenSigSendType" SG_ 302 EscVariantToDmcChks 0;
BA_ "GenSigFuncType" SG_ 302 EscVariantToDmcCntr 16;
BA_ "GenSigSendType" SG_ 302 EscVariantToDmcCntr 0;
BA_ "GenSigSendType" SG_ 302 EscVariantToDmcEscVariantToDmc 0;
BA_ "GenSigSendType" SG_ 1057 ExvNVMFltFromTMCU 0;
BA_ "GenSigSendType" SG_ 563 ExvPosnReqExvCalibReq 0;
BA_ "GenSigSendType" SG_ 563 ExvPosnReqExvHeatdReq 0;
BA_ "GenSigSendType" SG_ 563 ExvPosnReqExvMovEnable 0;
BA_ "GenSigSendType" SG_ 563 ExvPosnReqExvPosnReq 0;
BA_ "GenSigSendType" SG_ 675 ExvStsFromTMCUExvActrPosn 0;
BA_ "GenSigSendType" SG_ 675 ExvStsFromTMCUExvBlkErr 0;
BA_ "GenSigSendType" SG_ 675 ExvStsFromTMCUExvCalibSts 0;
BA_ "GenSigSendType" SG_ 675 ExvStsFromTMCUExvElecStsErr 0;
BA_ "GenSigSendType" SG_ 675 ExvStsFromTMCUExvMovSts 0;
BA_ "GenSigSendType" SG_ 675 ExvStsFromTMCUExvOvrTempErr 0;
BA_ "GenSigSendType" SG_ 675 ExvStsFromTMCUExvOvrTrvlErr 0;
BA_ "GenSigSendType" SG_ 675 ExvStsFromTMCUExvPreHeatgSts 0;
BA_ "GenSigSendType" SG_ 675 ExvStsFromTMCUExvVoltgRangErr 0;
BA_ "GenSigSendType" SG_ 401 FrntHeatModEnad 0;
BA_ "GenSigStartValue" SG_ 401 FrntHeatModEnad 2;
BA_ "GenSigSendType" SG_ 309 GearLock 0;
BA_ "GenSigSendType" SG_ 75 GearLvrIndcn 0;
BA_ "GenSigStartValue" SG_ 75 GearLvrIndcn 7;
BA_ "GenSigSendType" SG_ 309 GearShiftUnitSts 0;
BA_ "GenSigSendType" SG_ 819 GpsStatus 0;
BA_ "GenSigStartValue" SG_ 819 GpsStatus 1;
BA_ "GenSigSendType" SG_ 633 HctvCmdVlvActvSaveReq 0;
BA_ "GenSigSendType" SG_ 633 HctvCmdVlvCalibReq 0;
BA_ "GenSigSendType" SG_ 633 HctvCmdVlvHeatdReq 0;
BA_ "GenSigSendType" SG_ 633 HctvCmdVlvMovEna 0;
BA_ "GenSigSendType" SG_ 633 HctvCmdVlvPosn 0;
BA_ "GenSigSendType" SG_ 633 HctvCmdVlvSpdLvlReq 0;
BA_ "GenSigSendType" SG_ 675 HctvStsFromTMCUVlvBlkFlt 0;
BA_ "GenSigSendType" SG_ 675 HctvStsFromTMCUVlvCalibSts 0;
BA_ "GenSigSendType" SG_ 675 HctvStsFromTMCUVlvCmdPosnErr 0;
BA_ "GenSigSendType" SG_ 675 HctvStsFromTMCUVlvLoTErr 0;
BA_ "GenSigSendType" SG_ 675 HctvStsFromTMCUVlvMoveSts 0;
BA_ "GenSigSendType" SG_ 675 HctvStsFromTMCUVlvNVMFlt 0;
BA_ "GenSigSendType" SG_ 675 HctvStsFromTMCUVlvOpenCircFlt 0;
BA_ "GenSigSendType" SG_ 675 HctvStsFromTMCUVlvOverTErr 0;
BA_ "GenSigSendType" SG_ 675 HctvStsFromTMCUVlvOverTWarn 0;
BA_ "GenSigSendType" SG_ 675 HctvStsFromTMCUVlvOverTrvlFlt 0;
BA_ "GenSigSendType" SG_ 675 HctvStsFromTMCUVlvOverUErr 0;
BA_ "GenSigSendType" SG_ 675 HctvStsFromTMCUVlvPosn 0;
BA_ "GenSigSendType" SG_ 675 HctvStsFromTMCUVlvPosnCtrlTimeOutFlt 0;
BA_ "GenSigSendType" SG_ 675 HctvStsFromTMCUVlvPosnUkwnFlt 0;
BA_ "GenSigSendType" SG_ 675 HctvStsFromTMCUVlvPreHeatgSts 0;
BA_ "GenSigSendType" SG_ 675 HctvStsFromTMCUVlvSelfLearnFlt 0;
BA_ "GenSigSendType" SG_ 675 HctvStsFromTMCUVlvShoCircFlt 0;
BA_ "GenSigSendType" SG_ 675 HctvStsFromTMCUVlvSpdLvlSts 0;
BA_ "GenSigSendType" SG_ 675 HctvStsFromTMCUVlvUnderUErr 0;
BA_ "GenSigSendType" SG_ 563 HeatrPmpCmdCooltPmpPostRunReq 0;
BA_ "GenSigSendType" SG_ 563 HeatrPmpCmdCooltPmpSpdReq 0;
BA_ "GenSigSendType" SG_ 678 HeatrPmpStatFromTMCUCooltPmpDryErr 0;
BA_ "GenSigSendType" SG_ 678 HeatrPmpStatFromTMCUCooltPmpEmgyModSts 0;
BA_ "GenSigSendType" SG_ 678 HeatrPmpStatFromTMCUCooltPmpErrSts 0;
BA_ "GenSigSendType" SG_ 678 HeatrPmpStatFromTMCUCooltPmpI 0;
BA_ "GenSigSendType" SG_ 678 HeatrPmpStatFromTMCUCooltPmpIErr 0;
BA_ "GenSigSendType" SG_ 678 HeatrPmpStatFromTMCUCooltPmpMonrSpd 0;
BA_ "GenSigSendType" SG_ 678 HeatrPmpStatFromTMCUCooltPmpPostRunSts 0;
BA_ "GenSigSendType" SG_ 678 HeatrPmpStatFromTMCUCooltPmpSetPostRunReq 0;
BA_ "GenSigSendType" SG_ 678 HeatrPmpStatFromTMCUCooltPmpSetSpdReq 0;
BA_ "GenSigSendType" SG_ 678 HeatrPmpStatFromTMCUCooltPmpSpd 0;
BA_ "GenSigSendType" SG_ 678 HeatrPmpStatFromTMCUCooltPmpT 0;
BA_ "GenSigStartValue" SG_ 678 HeatrPmpStatFromTMCUCooltPmpT 100;
BA_ "GenSigSendType" SG_ 678 HeatrPmpStatFromTMCUCooltPmpTErr 0;
BA_ "GenSigSendType" SG_ 678 HeatrPmpStatFromTMCUCooltPmpU 0;
BA_ "GenSigSendType" SG_ 678 HeatrPmpStatFromTMCUCooltPmpUErr 0;
BA_ "GenSigSendType" SG_ 678 HeatrPmpStatFromTMCUCooltPmpUnstallSts 0;
BA_ "GenSigSendType" SG_ 593 HmiSteerWhlHeatLvlReq 0;
BA_ "GenSigStartValue" SG_ 593 HmiSteerWhlHeatLvlReq 7;
BA_ "GenSigSendType" SG_ 278 HvAuxActPwr 0;
BA_ "GenSigSendType" SG_ 649 HvBattChrgnEgyCnsAllwd1 0;
BA_ "GenSigSendType" SG_ 649 HvBattChrgnILim 0;
BA_ "GenSigSendType" SG_ 649 HvBattCoolgEgyCnsAllwd1 0;
BA_ "GenSigSendType" SG_ 569 HvBattLowSOCIndcn 0;
BA_ "GenSigSendType" SG_ 563 HvBattPmpCmdCooltPmpPostRunReq 0;
BA_ "GenSigSendType" SG_ 563 HvBattPmpCmdCooltPmpSpdReq 0;
BA_ "GenSigSendType" SG_ 681 HvBattPmpStatFromTMCUCooltPmpDryErr 0;
BA_ "GenSigSendType" SG_ 681 HvBattPmpStatFromTMCUCooltPmpEmgyModSts 0;
BA_ "GenSigSendType" SG_ 681 HvBattPmpStatFromTMCUCooltPmpErrSts 0;
BA_ "GenSigSendType" SG_ 681 HvBattPmpStatFromTMCUCooltPmpI 0;
BA_ "GenSigSendType" SG_ 681 HvBattPmpStatFromTMCUCooltPmpIErr 0;
BA_ "GenSigSendType" SG_ 681 HvBattPmpStatFromTMCUCooltPmpMonrSpd 0;
BA_ "GenSigSendType" SG_ 681 HvBattPmpStatFromTMCUCooltPmpPostRunSts 0;
BA_ "GenSigSendType" SG_ 681 HvBattPmpStatFromTMCUCooltPmpSetPostRunReq 0;
BA_ "GenSigSendType" SG_ 681 HvBattPmpStatFromTMCUCooltPmpSetSpdReq 0;
BA_ "GenSigSendType" SG_ 681 HvBattPmpStatFromTMCUCooltPmpSpd 0;
BA_ "GenSigSendType" SG_ 681 HvBattPmpStatFromTMCUCooltPmpT 0;
BA_ "GenSigStartValue" SG_ 681 HvBattPmpStatFromTMCUCooltPmpT 100;
BA_ "GenSigSendType" SG_ 681 HvBattPmpStatFromTMCUCooltPmpTErr 0;
BA_ "GenSigSendType" SG_ 681 HvBattPmpStatFromTMCUCooltPmpU 0;
BA_ "GenSigSendType" SG_ 681 HvBattPmpStatFromTMCUCooltPmpUErr 0;
BA_ "GenSigSendType" SG_ 681 HvBattPmpStatFromTMCUCooltPmpUnstallSts 0;
BA_ "GenSigSendType" SG_ 569 HvBattThermPreSts 0;
BA_ "GenSigSendType" SG_ 597 ImobEngMgrReq2ImobEngDataMgrReq0 0;
BA_ "GenSigSendType" SG_ 597 ImobEngMgrReq2ImobEngDataMgrReq1 0;
BA_ "GenSigSendType" SG_ 597 ImobEngMgrReq2ImobEngDataMgrReq2 0;
BA_ "GenSigSendType" SG_ 597 ImobEngMgrReq2ImobEngDataMgrReq3 0;
BA_ "GenSigSendType" SG_ 597 ImobEngMgrReq2ImobEngDataMgrReq4 0;
BA_ "GenSigSendType" SG_ 597 ImobEngMgrReq2ImobEngDataMgrReq5 0;
BA_ "GenSigSendType" SG_ 597 ImobEngMgrReq2ImobEngDataMgrReq6 0;
BA_ "GenSigSendType" SG_ 597 ImobEngMgrReq2ImobEngMgrCmdTar1 0;
BA_ "GenSigSendType" SG_ 86 IntrBriSts 0;
BA_ "GenSigSendType" SG_ 314 IsgCooltT 0;
BA_ "GenSigStartValue" SG_ 314 IsgCooltT 40;
BA_ "GenSigSendType" SG_ 391 IsgFcnResvSigGrp 0;
BA_ "GenSigSendType" SG_ 391 IsgFcnResvSigGrp1 0;
BA_ "GenSigSendType" SG_ 149 IsgModSts 0;
BA_ "GenSigSendType" SG_ 342 IsgUDc 0;
BA_ "GenSigSendType" SG_ 299 LimdPwrPerc 0;
BA_ "GenSigStartValue" SG_ 299 LimdPwrPerc 1000;
BA_ "GenSigSendType" SG_ 313 LockgCenStsLockSt 0;
BA_ "GenSigSendType" SG_ 313 LockgCenStsTrigSrc 0;
BA_ "GenSigSendType" SG_ 313 LockgCenStsUpdEve 0;
BA_ "GenSigSendType" SG_ 609 MaintainBattTCtrl 1;
BA_ "GenSigSendType" SG_ 667 MaxAcInpCurrentSet 1;
BA_ "GenSigSendType" SG_ 786 OnBdDiagLostCom 0;
BA_ "GenSigSendType" SG_ 1156 PTMPwrSaveDrvCyc 0;
BA_ "GenSigSendType" SG_ 1156 PTMStateVeh 0;
BA_ "GenSigSendType" SG_ 1152 PTMTotPwrSaveAmnt 0;
BA_ "GenSigSendType" SG_ 377 PrpsnFcnResvSigGrp 0;
BA_ "GenSigSendType" SG_ 377 PrpsnFcnResvSigGrp1 0;
BA_ "GenSigDataID" SG_ 65 PtTqAtAxleMaxReqChks "0x455";
BA_ "GenSigFuncType" SG_ 65 PtTqAtAxleMaxReqChks 15;
BA_ "GenSigSendType" SG_ 65 PtTqAtAxleMaxReqChks 0;
BA_ "GenSigFuncType" SG_ 65 PtTqAtAxleMaxReqCntr 16;
BA_ "GenSigSendType" SG_ 65 PtTqAtAxleMaxReqCntr 0;
BA_ "GenSigSendType" SG_ 65 PtTqAtAxleMaxReqPtTqAtAxleFrntReq 0;
BA_ "GenSigStartValue" SG_ 65 PtTqAtAxleMaxReqPtTqAtAxleFrntReq 20000;
BA_ "GenSigSendType" SG_ 65 PtTqAtAxleMaxReqPtTqAtAxleReReq 0;
BA_ "GenSigStartValue" SG_ 65 PtTqAtAxleMaxReqPtTqAtAxleReReq 20000;
BA_ "GenSigSendType" SG_ 313 SpdRotlForWhlsAtAxleRe 0;
BA_ "GenSigDataID" SG_ 282 StcStsToDmcChks "0x19A5";
BA_ "GenSigFuncType" SG_ 282 StcStsToDmcChks 15;
BA_ "GenSigSendType" SG_ 282 StcStsToDmcChks 0;
BA_ "GenSigFuncType" SG_ 282 StcStsToDmcCntr 16;
BA_ "GenSigSendType" SG_ 282 StcStsToDmcCntr 0;
BA_ "GenSigSendType" SG_ 282 StcStsToDmcEngRotTarSpdDMCFrnt 0;
BA_ "GenSigSendType" SG_ 282 StcStsToDmcEngRotTarSpdDMCRear 0;
BA_ "GenSigSendType" SG_ 282 StcStsToDmcFrnt 0;
BA_ "GenSigSendType" SG_ 282 StcStsToDmcRear 0;
BA_ "GenSigSendType" SG_ 279 TelmBookChrgnReq 1;
BA_ "GenSigSendType" SG_ 337 TiAndDateIndcnDataValid 0;
BA_ "GenSigSendType" SG_ 337 TiAndDateIndcnDay 0;
BA_ "GenSigStartValue" SG_ 337 TiAndDateIndcnDay 1;
BA_ "GenSigSendType" SG_ 337 TiAndDateIndcnHr1 0;
BA_ "GenSigSendType" SG_ 337 TiAndDateIndcnMins1 0;
BA_ "GenSigSendType" SG_ 337 TiAndDateIndcnMth1 0;
BA_ "GenSigStartValue" SG_ 337 TiAndDateIndcnMth1 1;
BA_ "GenSigSendType" SG_ 337 TiAndDateIndcnSec1 0;
BA_ "GenSigSendType" SG_ 337 TiAndDateIndcnYr1 0;
BA_ "GenSigSendType" SG_ 86 TwliBriSts 0;
BA_ "GenSigSendType" SG_ 819 UTCTiFromEthDataValid 0;
BA_ "GenSigSendType" SG_ 819 UTCTiFromEthDay 0;
BA_ "GenSigStartValue" SG_ 819 UTCTiFromEthDay 1;
BA_ "GenSigSendType" SG_ 819 UTCTiFromEthHr1 0;
BA_ "GenSigSendType" SG_ 819 UTCTiFromEthMins1 0;
BA_ "GenSigSendType" SG_ 819 UTCTiFromEthMth1 0;
BA_ "GenSigStartValue" SG_ 819 UTCTiFromEthMth1 1;
BA_ "GenSigSendType" SG_ 819 UTCTiFromEthSec1 0;
BA_ "GenSigSendType" SG_ 819 UTCTiFromEthYr1 0;
BA_ "GenSigSendType" SG_ 353 V2XDchaSwt 1;
BA_ "GenSigSendType" SG_ 634 V2XDchaSwtFb1 0;
BA_ "GenSigSendType" SG_ 1366 VFCVectorEGSMBlockID 1;
BA_ "GenSigSendType" SG_ 1366 VFCVectorEGSMVFCid0 1;
BA_ "GenSigSendType" SG_ 1366 VFCVectorEGSMVFCid1 1;
BA_ "GenSigSendType" SG_ 1366 VFCVectorEGSMVFCid10 1;
BA_ "GenSigSendType" SG_ 1366 VFCVectorEGSMVFCid11 1;
BA_ "GenSigSendType" SG_ 1366 VFCVectorEGSMVFCid12 1;
BA_ "GenSigSendType" SG_ 1366 VFCVectorEGSMVFCid13 1;
BA_ "GenSigSendType" SG_ 1366 VFCVectorEGSMVFCid14 1;
BA_ "GenSigSendType" SG_ 1366 VFCVectorEGSMVFCid15 1;
BA_ "GenSigSendType" SG_ 1366 VFCVectorEGSMVFCid16 1;
BA_ "GenSigSendType" SG_ 1366 VFCVectorEGSMVFCid17 1;
BA_ "GenSigSendType" SG_ 1366 VFCVectorEGSMVFCid18 1;
BA_ "GenSigSendType" SG_ 1366 VFCVectorEGSMVFCid19 1;
BA_ "GenSigSendType" SG_ 1366 VFCVectorEGSMVFCid2 1;
BA_ "GenSigSendType" SG_ 1366 VFCVectorEGSMVFCid20 1;
BA_ "GenSigSendType" SG_ 1366 VFCVectorEGSMVFCid21 1;
BA_ "GenSigSendType" SG_ 1366 VFCVectorEGSMVFCid22 1;
BA_ "GenSigSendType" SG_ 1366 VFCVectorEGSMVFCid23 1;
BA_ "GenSigSendType" SG_ 1366 VFCVectorEGSMVFCid24 1;
BA_ "GenSigSendType" SG_ 1366 VFCVectorEGSMVFCid25 1;
BA_ "GenSigSendType" SG_ 1366 VFCVectorEGSMVFCid26 1;
BA_ "GenSigSendType" SG_ 1366 VFCVectorEGSMVFCid27 1;
BA_ "GenSigSendType" SG_ 1366 VFCVectorEGSMVFCid28 1;
BA_ "GenSigSendType" SG_ 1366 VFCVectorEGSMVFCid29 1;
BA_ "GenSigSendType" SG_ 1366 VFCVectorEGSMVFCid3 1;
BA_ "GenSigSendType" SG_ 1366 VFCVectorEGSMVFCid30 1;
BA_ "GenSigSendType" SG_ 1366 VFCVectorEGSMVFCid31 1;
BA_ "GenSigSendType" SG_ 1366 VFCVectorEGSMVFCid32 1;
BA_ "GenSigSendType" SG_ 1366 VFCVectorEGSMVFCid33 1;
BA_ "GenSigSendType" SG_ 1366 VFCVectorEGSMVFCid34 1;
BA_ "GenSigSendType" SG_ 1366 VFCVectorEGSMVFCid35 1;
BA_ "GenSigSendType" SG_ 1366 VFCVectorEGSMVFCid36 1;
BA_ "GenSigSendType" SG_ 1366 VFCVectorEGSMVFCid37 1;
BA_ "GenSigSendType" SG_ 1366 VFCVectorEGSMVFCid38 1;
BA_ "GenSigSendType" SG_ 1366 VFCVectorEGSMVFCid39 1;
BA_ "GenSigSendType" SG_ 1366 VFCVectorEGSMVFCid4 1;
BA_ "GenSigSendType" SG_ 1366 VFCVectorEGSMVFCid40 1;
BA_ "GenSigSendType" SG_ 1366 VFCVectorEGSMVFCid41 1;
BA_ "GenSigSendType" SG_ 1366 VFCVectorEGSMVFCid42 1;
BA_ "GenSigSendType" SG_ 1366 VFCVectorEGSMVFCid43 1;
BA_ "GenSigSendType" SG_ 1366 VFCVectorEGSMVFCid44 1;
BA_ "GenSigSendType" SG_ 1366 VFCVectorEGSMVFCid45 1;
BA_ "GenSigSendType" SG_ 1366 VFCVectorEGSMVFCid46 1;
BA_ "GenSigSendType" SG_ 1366 VFCVectorEGSMVFCid47 1;
BA_ "GenSigSendType" SG_ 1366 VFCVectorEGSMVFCid48 1;
BA_ "GenSigSendType" SG_ 1366 VFCVectorEGSMVFCid49 1;
BA_ "GenSigSendType" SG_ 1366 VFCVectorEGSMVFCid5 1;
BA_ "GenSigSendType" SG_ 1366 VFCVectorEGSMVFCid50 1;
BA_ "GenSigSendType" SG_ 1366 VFCVectorEGSMVFCid51 1;
BA_ "GenSigSendType" SG_ 1366 VFCVectorEGSMVFCid52 1;
BA_ "GenSigSendType" SG_ 1366 VFCVectorEGSMVFCid53 1;
BA_ "GenSigSendType" SG_ 1366 VFCVectorEGSMVFCid54 1;
BA_ "GenSigSendType" SG_ 1366 VFCVectorEGSMVFCid55 1;
BA_ "GenSigSendType" SG_ 1366 VFCVectorEGSMVFCid56 1;
BA_ "GenSigSendType" SG_ 1366 VFCVectorEGSMVFCid57 1;
BA_ "GenSigSendType" SG_ 1366 VFCVectorEGSMVFCid58 1;
BA_ "GenSigSendType" SG_ 1366 VFCVectorEGSMVFCid59 1;
BA_ "GenSigSendType" SG_ 1366 VFCVectorEGSMVFCid6 1;
BA_ "GenSigSendType" SG_ 1366 VFCVectorEGSMVFCid60 1;
BA_ "GenSigSendType" SG_ 1366 VFCVectorEGSMVFCid61 1;
BA_ "GenSigSendType" SG_ 1366 VFCVectorEGSMVFCid7 1;
BA_ "GenSigSendType" SG_ 1366 VFCVectorEGSMVFCid8 1;
BA_ "GenSigSendType" SG_ 1366 VFCVectorEGSMVFCid9 1;
BA_ "GenSigSendType" SG_ 1376 VFCVectorXCUBlockID 0;
BA_ "GenSigSendType" SG_ 1376 VFCVectorXCUVFCid0 0;
BA_ "GenSigSendType" SG_ 1376 VFCVectorXCUVFCid1 0;
BA_ "GenSigSendType" SG_ 1376 VFCVectorXCUVFCid10 0;
BA_ "GenSigSendType" SG_ 1376 VFCVectorXCUVFCid11 0;
BA_ "GenSigSendType" SG_ 1376 VFCVectorXCUVFCid12 0;
BA_ "GenSigSendType" SG_ 1376 VFCVectorXCUVFCid13 0;
BA_ "GenSigSendType" SG_ 1376 VFCVectorXCUVFCid14 0;
BA_ "GenSigSendType" SG_ 1376 VFCVectorXCUVFCid15 0;
BA_ "GenSigSendType" SG_ 1376 VFCVectorXCUVFCid16 0;
BA_ "GenSigSendType" SG_ 1376 VFCVectorXCUVFCid17 0;
BA_ "GenSigSendType" SG_ 1376 VFCVectorXCUVFCid18 0;
BA_ "GenSigSendType" SG_ 1376 VFCVectorXCUVFCid19 0;
BA_ "GenSigSendType" SG_ 1376 VFCVectorXCUVFCid2 0;
BA_ "GenSigSendType" SG_ 1376 VFCVectorXCUVFCid20 0;
BA_ "GenSigSendType" SG_ 1376 VFCVectorXCUVFCid21 0;
BA_ "GenSigSendType" SG_ 1376 VFCVectorXCUVFCid22 0;
BA_ "GenSigSendType" SG_ 1376 VFCVectorXCUVFCid23 0;
BA_ "GenSigSendType" SG_ 1376 VFCVectorXCUVFCid24 0;
BA_ "GenSigSendType" SG_ 1376 VFCVectorXCUVFCid25 0;
BA_ "GenSigSendType" SG_ 1376 VFCVectorXCUVFCid26 0;
BA_ "GenSigSendType" SG_ 1376 VFCVectorXCUVFCid27 0;
BA_ "GenSigSendType" SG_ 1376 VFCVectorXCUVFCid28 0;
BA_ "GenSigSendType" SG_ 1376 VFCVectorXCUVFCid29 0;
BA_ "GenSigSendType" SG_ 1376 VFCVectorXCUVFCid3 0;
BA_ "GenSigSendType" SG_ 1376 VFCVectorXCUVFCid30 0;
BA_ "GenSigSendType" SG_ 1376 VFCVectorXCUVFCid31 0;
BA_ "GenSigSendType" SG_ 1376 VFCVectorXCUVFCid32 0;
BA_ "GenSigSendType" SG_ 1376 VFCVectorXCUVFCid33 0;
BA_ "GenSigSendType" SG_ 1376 VFCVectorXCUVFCid34 0;
BA_ "GenSigSendType" SG_ 1376 VFCVectorXCUVFCid35 0;
BA_ "GenSigSendType" SG_ 1376 VFCVectorXCUVFCid36 0;
BA_ "GenSigSendType" SG_ 1376 VFCVectorXCUVFCid37 0;
BA_ "GenSigSendType" SG_ 1376 VFCVectorXCUVFCid38 0;
BA_ "GenSigSendType" SG_ 1376 VFCVectorXCUVFCid39 0;
BA_ "GenSigSendType" SG_ 1376 VFCVectorXCUVFCid4 0;
BA_ "GenSigSendType" SG_ 1376 VFCVectorXCUVFCid40 0;
BA_ "GenSigSendType" SG_ 1376 VFCVectorXCUVFCid41 0;
BA_ "GenSigSendType" SG_ 1376 VFCVectorXCUVFCid42 0;
BA_ "GenSigSendType" SG_ 1376 VFCVectorXCUVFCid43 0;
BA_ "GenSigSendType" SG_ 1376 VFCVectorXCUVFCid44 0;
BA_ "GenSigSendType" SG_ 1376 VFCVectorXCUVFCid45 0;
BA_ "GenSigSendType" SG_ 1376 VFCVectorXCUVFCid46 0;
BA_ "GenSigSendType" SG_ 1376 VFCVectorXCUVFCid47 0;
BA_ "GenSigSendType" SG_ 1376 VFCVectorXCUVFCid48 0;
BA_ "GenSigSendType" SG_ 1376 VFCVectorXCUVFCid49 0;
BA_ "GenSigSendType" SG_ 1376 VFCVectorXCUVFCid5 0;
BA_ "GenSigSendType" SG_ 1376 VFCVectorXCUVFCid50 0;
BA_ "GenSigSendType" SG_ 1376 VFCVectorXCUVFCid51 0;
BA_ "GenSigSendType" SG_ 1376 VFCVectorXCUVFCid52 0;
BA_ "GenSigSendType" SG_ 1376 VFCVectorXCUVFCid53 0;
BA_ "GenSigSendType" SG_ 1376 VFCVectorXCUVFCid54 0;
BA_ "GenSigSendType" SG_ 1376 VFCVectorXCUVFCid55 0;
BA_ "GenSigSendType" SG_ 1376 VFCVectorXCUVFCid56 0;
BA_ "GenSigSendType" SG_ 1376 VFCVectorXCUVFCid57 0;
BA_ "GenSigSendType" SG_ 1376 VFCVectorXCUVFCid58 0;
BA_ "GenSigSendType" SG_ 1376 VFCVectorXCUVFCid59 0;
BA_ "GenSigSendType" SG_ 1376 VFCVectorXCUVFCid6 0;
BA_ "GenSigSendType" SG_ 1376 VFCVectorXCUVFCid60 0;
BA_ "GenSigSendType" SG_ 1376 VFCVectorXCUVFCid61 0;
BA_ "GenSigSendType" SG_ 1376 VFCVectorXCUVFCid7 0;
BA_ "GenSigSendType" SG_ 1376 VFCVectorXCUVFCid8 0;
BA_ "GenSigSendType" SG_ 1376 VFCVectorXCUVFCid9 0;
BA_ "GenSigSendType" SG_ 1349 VFCVectorZCUDMBlockID 0;
BA_ "GenSigSendType" SG_ 1349 VFCVectorZCUDMVFCid0 0;
BA_ "GenSigSendType" SG_ 1349 VFCVectorZCUDMVFCid1 0;
BA_ "GenSigSendType" SG_ 1349 VFCVectorZCUDMVFCid10 0;
BA_ "GenSigSendType" SG_ 1349 VFCVectorZCUDMVFCid11 0;
BA_ "GenSigSendType" SG_ 1349 VFCVectorZCUDMVFCid12 0;
BA_ "GenSigSendType" SG_ 1349 VFCVectorZCUDMVFCid13 0;
BA_ "GenSigSendType" SG_ 1349 VFCVectorZCUDMVFCid14 0;
BA_ "GenSigSendType" SG_ 1349 VFCVectorZCUDMVFCid15 0;
BA_ "GenSigSendType" SG_ 1349 VFCVectorZCUDMVFCid16 0;
BA_ "GenSigSendType" SG_ 1349 VFCVectorZCUDMVFCid17 0;
BA_ "GenSigSendType" SG_ 1349 VFCVectorZCUDMVFCid18 0;
BA_ "GenSigSendType" SG_ 1349 VFCVectorZCUDMVFCid19 0;
BA_ "GenSigSendType" SG_ 1349 VFCVectorZCUDMVFCid2 0;
BA_ "GenSigSendType" SG_ 1349 VFCVectorZCUDMVFCid20 0;
BA_ "GenSigSendType" SG_ 1349 VFCVectorZCUDMVFCid21 0;
BA_ "GenSigSendType" SG_ 1349 VFCVectorZCUDMVFCid22 0;
BA_ "GenSigSendType" SG_ 1349 VFCVectorZCUDMVFCid23 0;
BA_ "GenSigSendType" SG_ 1349 VFCVectorZCUDMVFCid24 0;
BA_ "GenSigSendType" SG_ 1349 VFCVectorZCUDMVFCid25 0;
BA_ "GenSigSendType" SG_ 1349 VFCVectorZCUDMVFCid26 0;
BA_ "GenSigSendType" SG_ 1349 VFCVectorZCUDMVFCid27 0;
BA_ "GenSigSendType" SG_ 1349 VFCVectorZCUDMVFCid28 0;
BA_ "GenSigSendType" SG_ 1349 VFCVectorZCUDMVFCid29 0;
BA_ "GenSigSendType" SG_ 1349 VFCVectorZCUDMVFCid3 0;
BA_ "GenSigSendType" SG_ 1349 VFCVectorZCUDMVFCid30 0;
BA_ "GenSigSendType" SG_ 1349 VFCVectorZCUDMVFCid31 0;
BA_ "GenSigSendType" SG_ 1349 VFCVectorZCUDMVFCid32 0;
BA_ "GenSigSendType" SG_ 1349 VFCVectorZCUDMVFCid33 0;
BA_ "GenSigSendType" SG_ 1349 VFCVectorZCUDMVFCid34 0;
BA_ "GenSigSendType" SG_ 1349 VFCVectorZCUDMVFCid35 0;
BA_ "GenSigSendType" SG_ 1349 VFCVectorZCUDMVFCid36 0;
BA_ "GenSigSendType" SG_ 1349 VFCVectorZCUDMVFCid37 0;
BA_ "GenSigSendType" SG_ 1349 VFCVectorZCUDMVFCid38 0;
BA_ "GenSigSendType" SG_ 1349 VFCVectorZCUDMVFCid39 0;
BA_ "GenSigSendType" SG_ 1349 VFCVectorZCUDMVFCid4 0;
BA_ "GenSigSendType" SG_ 1349 VFCVectorZCUDMVFCid40 0;
BA_ "GenSigSendType" SG_ 1349 VFCVectorZCUDMVFCid41 0;
BA_ "GenSigSendType" SG_ 1349 VFCVectorZCUDMVFCid42 0;
BA_ "GenSigSendType" SG_ 1349 VFCVectorZCUDMVFCid43 0;
BA_ "GenSigSendType" SG_ 1349 VFCVectorZCUDMVFCid44 0;
BA_ "GenSigSendType" SG_ 1349 VFCVectorZCUDMVFCid45 0;
BA_ "GenSigSendType" SG_ 1349 VFCVectorZCUDMVFCid46 0;
BA_ "GenSigSendType" SG_ 1349 VFCVectorZCUDMVFCid47 0;
BA_ "GenSigSendType" SG_ 1349 VFCVectorZCUDMVFCid48 0;
BA_ "GenSigSendType" SG_ 1349 VFCVectorZCUDMVFCid49 0;
BA_ "GenSigSendType" SG_ 1349 VFCVectorZCUDMVFCid5 0;
BA_ "GenSigSendType" SG_ 1349 VFCVectorZCUDMVFCid50 0;
BA_ "GenSigSendType" SG_ 1349 VFCVectorZCUDMVFCid51 0;
BA_ "GenSigSendType" SG_ 1349 VFCVectorZCUDMVFCid52 0;
BA_ "GenSigSendType" SG_ 1349 VFCVectorZCUDMVFCid53 0;
BA_ "GenSigSendType" SG_ 1349 VFCVectorZCUDMVFCid54 0;
BA_ "GenSigSendType" SG_ 1349 VFCVectorZCUDMVFCid55 0;
BA_ "GenSigSendType" SG_ 1349 VFCVectorZCUDMVFCid56 0;
BA_ "GenSigSendType" SG_ 1349 VFCVectorZCUDMVFCid57 0;
BA_ "GenSigSendType" SG_ 1349 VFCVectorZCUDMVFCid58 0;
BA_ "GenSigSendType" SG_ 1349 VFCVectorZCUDMVFCid59 0;
BA_ "GenSigSendType" SG_ 1349 VFCVectorZCUDMVFCid6 0;
BA_ "GenSigSendType" SG_ 1349 VFCVectorZCUDMVFCid60 0;
BA_ "GenSigSendType" SG_ 1349 VFCVectorZCUDMVFCid61 0;
BA_ "GenSigSendType" SG_ 1349 VFCVectorZCUDMVFCid7 0;
BA_ "GenSigSendType" SG_ 1349 VFCVectorZCUDMVFCid8 0;
BA_ "GenSigSendType" SG_ 1349 VFCVectorZCUDMVFCid9 0;
BA_ "GenSigSendType" SG_ 645 VehBattUSysU 0;
BA_ "GenSigSendType" SG_ 645 VehBattUSysUQf 0;
BA_ "GenSigStartValue" SG_ 645 VehBattUSysUQf 1;
BA_ "GenSigSendType" SG_ 565 VehCfgPrmBlkIDBytePosn1 1;
BA_ "GenSigSendType" SG_ 565 VehCfgPrmCCPBytePosn2 1;
BA_ "GenSigSendType" SG_ 565 VehCfgPrmCCPBytePosn3 1;
BA_ "GenSigSendType" SG_ 565 VehCfgPrmCCPBytePosn4 1;
BA_ "GenSigSendType" SG_ 565 VehCfgPrmCCPBytePosn5 1;
BA_ "GenSigSendType" SG_ 565 VehCfgPrmCCPBytePosn6 1;
BA_ "GenSigSendType" SG_ 565 VehCfgPrmCCPBytePosn7 1;
BA_ "GenSigSendType" SG_ 565 VehCfgPrmCCPBytePosn8 1;
BA_ "GenSigSendType" SG_ 566 VehCfgPrmExtBlkIDBytePosn1 1;
BA_ "GenSigSendType" SG_ 566 VehCfgPrmExtCCPBytePosn2 1;
BA_ "GenSigSendType" SG_ 566 VehCfgPrmExtCCPBytePosn3 1;
BA_ "GenSigSendType" SG_ 566 VehCfgPrmExtCCPBytePosn4 1;
BA_ "GenSigSendType" SG_ 566 VehCfgPrmExtCCPBytePosn5 1;
BA_ "GenSigSendType" SG_ 566 VehCfgPrmExtCCPBytePosn6 1;
BA_ "GenSigSendType" SG_ 566 VehCfgPrmExtCCPBytePosn7 1;
BA_ "GenSigSendType" SG_ 566 VehCfgPrmExtCCPBytePosn8 1;
BA_ "GenSigSendType" SG_ 86 VehModMngtGlbSafe1CarModSts1 0;
BA_ "GenSigSendType" SG_ 86 VehModMngtGlbSafe1CarModSubtypWdCarModSubtyp 0;
BA_ "GenSigDataID" SG_ 86 VehModMngtGlbSafe1Chks "0x74";
BA_ "GenSigFuncType" SG_ 86 VehModMngtGlbSafe1Chks 15;
BA_ "GenSigSendType" SG_ 86 VehModMngtGlbSafe1Chks 0;
BA_ "GenSigFuncType" SG_ 86 VehModMngtGlbSafe1Cntr 16;
BA_ "GenSigSendType" SG_ 86 VehModMngtGlbSafe1Cntr 0;
BA_ "GenSigSendType" SG_ 86 VehModMngtGlbSafe1EgyLvlElecMai 0;
BA_ "GenSigSendType" SG_ 86 VehModMngtGlbSafe1EgyLvlElecSubtyp 0;
BA_ "GenSigSendType" SG_ 86 VehModMngtGlbSafe1FltEgyCnsWdSts 0;
BA_ "GenSigSendType" SG_ 86 VehModMngtGlbSafe1PwrLvlElecMai 0;
BA_ "GenSigSendType" SG_ 86 VehModMngtGlbSafe1PwrLvlElecSubtyp 0;
BA_ "GenSigSendType" SG_ 86 VehModMngtGlbSafe1UsgModSts 0;
BA_ "GenSigStartValue" SG_ 86 VehModMngtGlbSafe1UsgModSts 1;
BA_ "GenSigDataID" SG_ 118 VehMtnStChks "0x36";
BA_ "GenSigFuncType" SG_ 118 VehMtnStChks 15;
BA_ "GenSigSendType" SG_ 118 VehMtnStChks 0;
BA_ "GenSigFuncType" SG_ 118 VehMtnStCntr 16;
BA_ "GenSigSendType" SG_ 118 VehMtnStCntr 0;
BA_ "GenSigSendType" SG_ 118 VehMtnStVehMtnSt 0;
BA_ "GenSigSendType" SG_ 118 VehSpdLgtA 0;
BA_ "GenSigDataID" SG_ 118 VehSpdLgtChks "0x37";
BA_ "GenSigFuncType" SG_ 118 VehSpdLgtChks 15;
BA_ "GenSigSendType" SG_ 118 VehSpdLgtChks 0;
BA_ "GenSigFuncType" SG_ 118 VehSpdLgtCntr 16;
BA_ "GenSigSendType" SG_ 118 VehSpdLgtCntr 0;
BA_ "GenSigSendType" SG_ 118 VehSpdLgtQf 0;
BA_ "GenSigStartValue" SG_ 118 VehSpdLgtQf 1;
BA_ "GenSigSendType" SG_ 1143 VinBlockNr 1;
BA_ "GenSigSendType" SG_ 1143 VinVINSignalPos1 1;
BA_ "GenSigSendType" SG_ 1143 VinVINSignalPos2 1;
BA_ "GenSigSendType" SG_ 1143 VinVINSignalPos3 1;
BA_ "GenSigSendType" SG_ 1143 VinVINSignalPos4 1;
BA_ "GenSigSendType" SG_ 1143 VinVINSignalPos5 1;
BA_ "GenSigSendType" SG_ 1143 VinVINSignalPos6 1;
BA_ "GenSigSendType" SG_ 1143 VinVINSignalPos7 1;
BA_ "GenSigSendType" SG_ 1312 WakeUpReasonsforXCU 0;
BA_ "GenSigSendType" SG_ 1285 WakeUpReasonsforZCUDM 0;
VAL_ 75 EngSt1WdStsEngSt1WdSts 0 "EngSt1_Ini" 1 "EngSt1_Awake" 2 "EngSt1_Rdy" 3 "EngSt1_PreStrtg" 4 "EngSt1_StrtgInProgs" 5 "EngSt1_RunngRunng" 6 "EngSt1_RunngStb" 7 "EngSt1_RunngStrtgInProgs" 8 "EngSt1_RunngRemStrtd" 9 "EngSt1_AftRun";
VAL_ 75 GearLvrIndcn 0 "GearLvrIndcn2_ParkIndcn" 1 "GearLvrIndcn2_RvsIndcn" 2 "GearLvrIndcn2_NeutIndcn" 3 "GearLvrIndcn2_DrvIndcn" 4 "GearLvrIndcn2_ManModeIndcn" 5 "GearLvrIndcn2_Resd1" 6 "GearLvrIndcn2_Resd2" 7 "GearLvrIndcn2_Undefd";
VAL_ 634 DrvgCyc 0 "OnOff1_Off" 1 "OnOff1_On";
VAL_ 634 V2XDchaSwtFb1 0 "DisChrgrSW_Off" 1 "DisChrgrSW_V2V" 2 "DisChrgrSW_V2L";
VAL_ 401 FrntHeatModEnad 0 "FrntHeatModEnad_Heatg" 1 "FrntHeatModEnad_PwrLoss" 2 "FrntHeatModEnad_Off" 3 "FrntHeatModEnad_Reserved";
VAL_ 278 AccrPedlPsdAccrPedlPsd 0 "NoYes1_No" 1 "NoYes1_Yes";
VAL_ 278 AccrPedlPsdSts 0 "NoYes1_No" 1 "NoYes1_Yes";
VAL_ 569 BexvPosnReqExvCalibReq 0 "ExvCalibReq_NoReq" 1 "ExvCalibReq_InitializationReq";
VAL_ 569 BexvPosnReqExvHeatdReq 0 "ExvHeatdReq_NoReq" 1 "ExvHeatdReq_PreHeatedReq";
VAL_ 569 BexvPosnReqExvMovEnable 0 "EXVNotEnable" 1 "EXVEnable";
VAL_ 569 HvBattLowSOCIndcn 0 "HvBattLowSOCIndcn_Default" 1 "HvBattLowSOCIndcn_Yellow" 2 "HvBattLowSOCIndcn_Red" 3 "HvBattLowSOCIndcn_Reserved1";
VAL_ 569 HvBattThermPreSts 0 "OnOff1_Off" 1 "OnOff1_On";
VAL_ 309 DrvrGearShiftManReqDwnDwnTipReq 0 "DwnDwnTipReq_NotActv" 1 "DwnDwnTipReq_Actv";
VAL_ 309 DrvrGearShiftManReqDwnTipReq 0 "DwnTipReq_DwnTipReqNotActv" 1 "DwnTipReq_DwnTipReqActv";
VAL_ 309 DrvrGearShiftManReqSteerWhlDwnReq1 0 "SteerWhlDwnReq1_SteerWhlDwnReqNotActv" 1 "SteerWhlDwnReq1_SteerWhlDwnReqActv";
VAL_ 309 DrvrGearShiftManReqSteerWhlUpReq 0 "SteerWhlUpReq_SteerWhlUpReqNotActv" 1 "SteerWhlUpReq_SteerWhlUpReqActv";
VAL_ 309 DrvrGearShiftManReqTipReq1 0 "TipReq1_TipReqNotActv" 1 "TipReq1_TipReqActv";
VAL_ 309 DrvrGearShiftManReqUpTipReq1 0 "UpTipReq1_UpTipReqNotActv" 1 "UpTipReq1_UpTipReqActv";
VAL_ 309 DrvrGearShiftManReqUpUpTipReq 0 "UpUpTipReq_NotActv" 1 "UpUpTipReq_Actv";
VAL_ 309 DrvrGearShiftParkReq1 0 "SwtPark1_SwtParkNotActv" 1 "SwtPark1_SwtParkActv";
VAL_ 309 DrvrGearShiftParkReqSts 0 "ClutchPedlPsd_No" 1 "ClutchPedlPsd_Yes" 2 "ClutchPedlPsd_Reserved1" 3 "ClutchPedlPsd_Reserved2";
VAL_ 309 GearLock 0 "ActvInActv_Active" 1 "ActvInActv_Inactive";
VAL_ 309 GearShiftUnitSts 0 "NoFlt" 1 "NoUpTipAut" 2 "NoDwnTipAut" 3 "NoPark" 4 "SrvRqrd" 5 "NoUpUpTipAut" 6 "NoDownDownTipAut" 7 "Nounlock";
VAL_ 310 DrvrGearShiftDirReq1DwnDwnTipAut 0 "NotActvActv1_NotActv" 1 "NotActvActv1_Actv";
VAL_ 310 DrvrGearShiftDirReq1DwnTipAut 0 "DwnTipAut1_DwnTipAutNotActv" 1 "DwnTipAut1_DwnTipAutActv";
VAL_ 310 DrvrGearShiftDirReq1PosnAut 0 "PosnAut_PosnAutNotActv" 1 "PosnAut_PosnAutActv";
VAL_ 310 DrvrGearShiftDirReq1UpTipAut 0 "UpTipAut1_UpTipAutNotActv" 1 "UpTipAut1_UpTipAutActv";
VAL_ 310 DrvrGearShiftDirReq1UpUpTipAut 0 "NotActvActv1_NotActv" 1 "NotActvActv1_Actv";
VAL_ 310 DrvrGearShiftDirReq2DwnDwnTipAut 0 "NotActvActv1_NotActv" 1 "NotActvActv1_Actv";
VAL_ 310 DrvrGearShiftDirReq2DwnTipAut 0 "DwnTipAut1_DwnTipAutNotActv" 1 "DwnTipAut1_DwnTipAutActv";
VAL_ 310 DrvrGearShiftDirReq2PosnAut 0 "PosnAut_PosnAutNotActv" 1 "PosnAut_PosnAutActv";
VAL_ 310 DrvrGearShiftDirReq2UpTipAut 0 "UpTipAut1_UpTipAutNotActv" 1 "UpTipAut1_UpTipAutActv";
VAL_ 310 DrvrGearShiftDirReq2UpUpTipAut 0 "NotActvActv1_NotActv" 1 "NotActvActv1_Actv";
VAL_ 1366 VFCVectorEGSMVFCid0 0 "VFCOnOff_Off" 1 "VFCOnOff_On";
VAL_ 1366 VFCVectorEGSMVFCid1 0 "VFCOnOff_Off" 1 "VFCOnOff_On";
VAL_ 1366 VFCVectorEGSMVFCid10 0 "VFCOnOff_Off" 1 "VFCOnOff_On";
VAL_ 1366 VFCVectorEGSMVFCid11 0 "VFCOnOff_Off" 1 "VFCOnOff_On";
VAL_ 1366 VFCVectorEGSMVFCid12 0 "VFCOnOff_Off" 1 "VFCOnOff_On";
VAL_ 1366 VFCVectorEGSMVFCid13 0 "VFCOnOff_Off" 1 "VFCOnOff_On";
VAL_ 1366 VFCVectorEGSMVFCid14 0 "VFCOnOff_Off" 1 "VFCOnOff_On";
VAL_ 1366 VFCVectorEGSMVFCid15 0 "VFCOnOff_Off" 1 "VFCOnOff_On";
VAL_ 1366 VFCVectorEGSMVFCid16 0 "VFCOnOff_Off" 1 "VFCOnOff_On";
VAL_ 1366 VFCVectorEGSMVFCid17 0 "VFCOnOff_Off" 1 "VFCOnOff_On";
VAL_ 1366 VFCVectorEGSMVFCid18 0 "VFCOnOff_Off" 1 "VFCOnOff_On";
VAL_ 1366 VFCVectorEGSMVFCid19 0 "VFCOnOff_Off" 1 "VFCOnOff_On";
VAL_ 1366 VFCVectorEGSMVFCid2 0 "VFCOnOff_Off" 1 "VFCOnOff_On";
VAL_ 1366 VFCVectorEGSMVFCid20 0 "VFCOnOff_Off" 1 "VFCOnOff_On";
VAL_ 1366 VFCVectorEGSMVFCid21 0 "VFCOnOff_Off" 1 "VFCOnOff_On";
VAL_ 1366 VFCVectorEGSMVFCid22 0 "VFCOnOff_Off" 1 "VFCOnOff_On";
VAL_ 1366 VFCVectorEGSMVFCid23 0 "VFCOnOff_Off" 1 "VFCOnOff_On";
VAL_ 1366 VFCVectorEGSMVFCid24 0 "VFCOnOff_Off" 1 "VFCOnOff_On";
VAL_ 1366 VFCVectorEGSMVFCid25 0 "VFCOnOff_Off" 1 "VFCOnOff_On";
VAL_ 1366 VFCVectorEGSMVFCid26 0 "VFCOnOff_Off" 1 "VFCOnOff_On";
VAL_ 1366 VFCVectorEGSMVFCid27 0 "VFCOnOff_Off" 1 "VFCOnOff_On";
VAL_ 1366 VFCVectorEGSMVFCid28 0 "VFCOnOff_Off" 1 "VFCOnOff_On";
VAL_ 1366 VFCVectorEGSMVFCid29 0 "VFCOnOff_Off" 1 "VFCOnOff_On";
VAL_ 1366 VFCVectorEGSMVFCid3 0 "VFCOnOff_Off" 1 "VFCOnOff_On";
VAL_ 1366 VFCVectorEGSMVFCid30 0 "VFCOnOff_Off" 1 "VFCOnOff_On";
VAL_ 1366 VFCVectorEGSMVFCid31 0 "VFCOnOff_Off" 1 "VFCOnOff_On";
VAL_ 1366 VFCVectorEGSMVFCid32 0 "VFCOnOff_Off" 1 "VFCOnOff_On";
VAL_ 1366 VFCVectorEGSMVFCid33 0 "VFCOnOff_Off" 1 "VFCOnOff_On";
VAL_ 1366 VFCVectorEGSMVFCid34 0 "VFCOnOff_Off" 1 "VFCOnOff_On";
VAL_ 1366 VFCVectorEGSMVFCid35 0 "VFCOnOff_Off" 1 "VFCOnOff_On";
VAL_ 1366 VFCVectorEGSMVFCid36 0 "VFCOnOff_Off" 1 "VFCOnOff_On";
VAL_ 1366 VFCVectorEGSMVFCid37 0 "VFCOnOff_Off" 1 "VFCOnOff_On";
VAL_ 1366 VFCVectorEGSMVFCid38 0 "VFCOnOff_Off" 1 "VFCOnOff_On";
VAL_ 1366 VFCVectorEGSMVFCid39 0 "VFCOnOff_Off" 1 "VFCOnOff_On";
VAL_ 1366 VFCVectorEGSMVFCid4 0 "VFCOnOff_Off" 1 "VFCOnOff_On";
VAL_ 1366 VFCVectorEGSMVFCid40 0 "VFCOnOff_Off" 1 "VFCOnOff_On";
VAL_ 1366 VFCVectorEGSMVFCid41 0 "VFCOnOff_Off" 1 "VFCOnOff_On";
VAL_ 1366 VFCVectorEGSMVFCid42 0 "VFCOnOff_Off" 1 "VFCOnOff_On";
VAL_ 1366 VFCVectorEGSMVFCid43 0 "VFCOnOff_Off" 1 "VFCOnOff_On";
VAL_ 1366 VFCVectorEGSMVFCid44 0 "VFCOnOff_Off" 1 "VFCOnOff_On";
VAL_ 1366 VFCVectorEGSMVFCid45 0 "VFCOnOff_Off" 1 "VFCOnOff_On";
VAL_ 1366 VFCVectorEGSMVFCid46 0 "VFCOnOff_Off" 1 "VFCOnOff_On";
VAL_ 1366 VFCVectorEGSMVFCid47 0 "VFCOnOff_Off" 1 "VFCOnOff_On";
VAL_ 1366 VFCVectorEGSMVFCid48 0 "VFCOnOff_Off" 1 "VFCOnOff_On";
VAL_ 1366 VFCVectorEGSMVFCid49 0 "VFCOnOff_Off" 1 "VFCOnOff_On";
VAL_ 1366 VFCVectorEGSMVFCid5 0 "VFCOnOff_Off" 1 "VFCOnOff_On";
VAL_ 1366 VFCVectorEGSMVFCid50 0 "VFCOnOff_Off" 1 "VFCOnOff_On";
VAL_ 1366 VFCVectorEGSMVFCid51 0 "VFCOnOff_Off" 1 "VFCOnOff_On";
VAL_ 1366 VFCVectorEGSMVFCid52 0 "VFCOnOff_Off" 1 "VFCOnOff_On";
VAL_ 1366 VFCVectorEGSMVFCid53 0 "VFCOnOff_Off" 1 "VFCOnOff_On";
VAL_ 1366 VFCVectorEGSMVFCid54 0 "VFCOnOff_Off" 1 "VFCOnOff_On";
VAL_ 1366 VFCVectorEGSMVFCid55 0 "VFCOnOff_Off" 1 "VFCOnOff_On";
VAL_ 1366 VFCVectorEGSMVFCid56 0 "VFCOnOff_Off" 1 "VFCOnOff_On";
VAL_ 1366 VFCVectorEGSMVFCid57 0 "VFCOnOff_Off" 1 "VFCOnOff_On";
VAL_ 1366 VFCVectorEGSMVFCid58 0 "VFCOnOff_Off" 1 "VFCOnOff_On";
VAL_ 1366 VFCVectorEGSMVFCid59 0 "VFCOnOff_Off" 1 "VFCOnOff_On";
VAL_ 1366 VFCVectorEGSMVFCid6 0 "VFCOnOff_Off" 1 "VFCOnOff_On";
VAL_ 1366 VFCVectorEGSMVFCid60 0 "VFCOnOff_Off" 1 "VFCOnOff_On";
VAL_ 1366 VFCVectorEGSMVFCid61 0 "VFCOnOff_Off" 1 "VFCOnOff_On";
VAL_ 1366 VFCVectorEGSMVFCid7 0 "VFCOnOff_Off" 1 "VFCOnOff_On";
VAL_ 1366 VFCVectorEGSMVFCid8 0 "VFCOnOff_Off" 1 "VFCOnOff_On";
VAL_ 1366 VFCVectorEGSMVFCid9 0 "VFCOnOff_Off" 1 "VFCOnOff_On";
VAL_ 149 IsgModSts 0 "IsgModTyp2_Inin" 1 "IsgModTyp2_Stb" 2 "IsgModTyp2_TqCtrl" 3 "IsgModTyp2_SpdCtrl" 4 "IsgModTyp2_UDcCtrl" 5 "IsgModTyp2_PreChrg" 6 "IsgModTyp2_PwrDwn" 7 "IsgModTyp2_Flt" 8 "IsgModTyp2_TcsCtrl" 9 "IsgModTyp2_CluOpe";
VAL_ 593 HmiSteerWhlHeatLvlReq 0 "SeatClimaLvl1_Off" 1 "SeatClimaLvl1_Lvl1" 2 "SeatClimaLvl1_Lvl2" 3 "SeatClimaLvl1_Lvl3" 4 "SeatClimaLvl1_Auto" 5 "SeatClimaLvl1_Resvd1" 6 "SeatClimaLvl1_Resvd2" 7 "SeatClimaLvl1_idle";
VAL_ 53 CrashStsSafeSts 0 "CrashSts2_NoCrash" 1 "CrashSts2_Crash";
VAL_ 681 HvBattPmpStatFromTMCUCooltPmpDryErr 0 "CooltPmpDryErr_RunDryNotDetd" 1 "CooltPmpDryErr_RunDryDetd" 2 "CooltPmpDryErr_Resd1" 3 "CooltPmpDryErr_Resd2";
VAL_ 681 HvBattPmpStatFromTMCUCooltPmpEmgyModSts 0 "CooltPmpEmgyModSts_EmgyRunNotActv" 1 "CooltPmpEmgyModSts_EmgyRunActv" 2 "CooltPmpEmgyModSts_Resd1" 3 "CooltPmpEmgyModSts_Resd2";
VAL_ 681 HvBattPmpStatFromTMCUCooltPmpErrSts 0 "CooltPmpErrSts_StNoErr" 1 "CooltPmpErrSts_StErr" 2 "CooltPmpErrSts_StNewErr" 3 "CooltPmpErrSts_Resd";
VAL_ 681 HvBattPmpStatFromTMCUCooltPmpIErr 0 "CooltPmpIErr_INoErr" 1 "CooltPmpIErr_IErr" 2 "CooltPmpIErr_Resd1" 3 "CooltPmpIErr_Resd2";
VAL_ 681 HvBattPmpStatFromTMCUCooltPmpMonrSpd 0 "CooltPmpMonrSpd_MonrSpdActv" 1 "CooltPmpMonrSpd_MonrSpdNoActv" 2 "CooltPmpMonrSpd_Resd1" 3 "CooltPmpMonrSpd_Resd2";
VAL_ 681 HvBattPmpStatFromTMCUCooltPmpPostRunSts 0 "CooltPmpPostRunSts_CooltPmpPostRunFinshd" 1 "CooltPmpPostRunSts_CooltPmpPostRunCncld" 2 "CooltPmpPostRunSts_Resd1" 3 "CooltPmpPostRunSts_Resd2";
VAL_ 681 HvBattPmpStatFromTMCUCooltPmpSetPostRunReq 0 "CooltPmpSetPostRunReq_CooltPmpSetNoPostRun" 1 "CooltPmpSetPostRunReq_CooltPmpSetPostRun1" 2 "CooltPmpSetPostRunReq_CooltPmpSetPostRun2" 3 "CooltPmpSetPostRunReq_CooltPmpSetPostRun3" 4 "CooltPmpSetPostRunReq_CooltPmpSetPostRun4" 5 "CooltPmpSetPostRunReq_CooltPmpSetPostRun5" 6 "CooltPmpSetPostRunReq_Resd1" 7 "CooltPmpSetPostRunReq_Resd2";
VAL_ 681 HvBattPmpStatFromTMCUCooltPmpTErr 0 "CooltPmpTErr_CooltPmpNoTErr" 1 "CooltPmpTErr_CooltPmpTErr" 2 "CooltPmpTErr_Resd1" 3 "CooltPmpTErr_Resd2";
VAL_ 681 HvBattPmpStatFromTMCUCooltPmpUErr 0 "CooltPmpUErr_CooltPmpNoUErr" 1 "CooltPmpUErr_CooltPmpUErr" 2 "CooltPmpUErr_Resd1" 3 "CooltPmpUErr_Resd2";
VAL_ 681 HvBattPmpStatFromTMCUCooltPmpUnstallSts 0 "CooltPmpUnstallSts_CooltPmpUnstallNotActv" 1 "CooltPmpUnstallSts_CooltPmpUnstallActv" 2 "CooltPmpUnstallSts_Resd1" 3 "CooltPmpUnstallSts_Resd2";
VAL_ 678 HeatrPmpStatFromTMCUCooltPmpDryErr 0 "CooltPmpDryErr_RunDryNotDetd" 1 "CooltPmpDryErr_RunDryDetd" 2 "CooltPmpDryErr_Resd1" 3 "CooltPmpDryErr_Resd2";
VAL_ 678 HeatrPmpStatFromTMCUCooltPmpEmgyModSts 0 "CooltPmpEmgyModSts_EmgyRunNotActv" 1 "CooltPmpEmgyModSts_EmgyRunActv" 2 "CooltPmpEmgyModSts_Resd1" 3 "CooltPmpEmgyModSts_Resd2";
VAL_ 678 HeatrPmpStatFromTMCUCooltPmpErrSts 0 "CooltPmpErrSts_StNoErr" 1 "CooltPmpErrSts_StErr" 2 "CooltPmpErrSts_StNewErr" 3 "CooltPmpErrSts_Resd";
VAL_ 678 HeatrPmpStatFromTMCUCooltPmpIErr 0 "CooltPmpIErr_INoErr" 1 "CooltPmpIErr_IErr" 2 "CooltPmpIErr_Resd1" 3 "CooltPmpIErr_Resd2";
VAL_ 678 HeatrPmpStatFromTMCUCooltPmpMonrSpd 0 "CooltPmpMonrSpd_MonrSpdActv" 1 "CooltPmpMonrSpd_MonrSpdNoActv" 2 "CooltPmpMonrSpd_Resd1" 3 "CooltPmpMonrSpd_Resd2";
VAL_ 678 HeatrPmpStatFromTMCUCooltPmpPostRunSts 0 "CooltPmpPostRunSts_CooltPmpPostRunFinshd" 1 "CooltPmpPostRunSts_CooltPmpPostRunCncld" 2 "CooltPmpPostRunSts_Resd1" 3 "CooltPmpPostRunSts_Resd2";
VAL_ 678 HeatrPmpStatFromTMCUCooltPmpSetPostRunReq 0 "CooltPmpSetPostRunReq_CooltPmpSetNoPostRun" 1 "CooltPmpSetPostRunReq_CooltPmpSetPostRun1" 2 "CooltPmpSetPostRunReq_CooltPmpSetPostRun2" 3 "CooltPmpSetPostRunReq_CooltPmpSetPostRun3" 4 "CooltPmpSetPostRunReq_CooltPmpSetPostRun4" 5 "CooltPmpSetPostRunReq_CooltPmpSetPostRun5" 6 "CooltPmpSetPostRunReq_Resd1" 7 "CooltPmpSetPostRunReq_Resd2";
VAL_ 678 HeatrPmpStatFromTMCUCooltPmpTErr 0 "CooltPmpTErr_CooltPmpNoTErr" 1 "CooltPmpTErr_CooltPmpTErr" 2 "CooltPmpTErr_Resd1" 3 "CooltPmpTErr_Resd2";
VAL_ 678 HeatrPmpStatFromTMCUCooltPmpUErr 0 "CooltPmpUErr_CooltPmpNoUErr" 1 "CooltPmpUErr_CooltPmpUErr" 2 "CooltPmpUErr_Resd1" 3 "CooltPmpUErr_Resd2";
VAL_ 678 HeatrPmpStatFromTMCUCooltPmpUnstallSts 0 "CooltPmpUnstallSts_CooltPmpUnstallNotActv" 1 "CooltPmpUnstallSts_CooltPmpUnstallActv" 2 "CooltPmpUnstallSts_Resd1" 3 "CooltPmpUnstallSts_Resd2";
VAL_ 684 Edcp2PmpStsFromTMCUCooltPmpDryErr 0 "CooltPmpDryErr_RunDryNotDetd" 1 "CooltPmpDryErr_RunDryDetd" 2 "CooltPmpDryErr_Resd1" 3 "CooltPmpDryErr_Resd2";
VAL_ 684 Edcp2PmpStsFromTMCUCooltPmpEmgyModSts 0 "CooltPmpEmgyModSts_EmgyRunNotActv" 1 "CooltPmpEmgyModSts_EmgyRunActv" 2 "CooltPmpEmgyModSts_Resd1" 3 "CooltPmpEmgyModSts_Resd2";
VAL_ 684 Edcp2PmpStsFromTMCUCooltPmpErrSts 0 "CooltPmpErrSts_StNoErr" 1 "CooltPmpErrSts_StErr" 2 "CooltPmpErrSts_StNewErr" 3 "CooltPmpErrSts_Resd";
VAL_ 684 Edcp2PmpStsFromTMCUCooltPmpIErr 0 "CooltPmpIErr_INoErr" 1 "CooltPmpIErr_IErr" 2 "CooltPmpIErr_Resd1" 3 "CooltPmpIErr_Resd2";
VAL_ 684 Edcp2PmpStsFromTMCUCooltPmpMonrSpd 0 "CooltPmpMonrSpd_MonrSpdActv" 1 "CooltPmpMonrSpd_MonrSpdNoActv" 2 "CooltPmpMonrSpd_Resd1" 3 "CooltPmpMonrSpd_Resd2";
VAL_ 684 Edcp2PmpStsFromTMCUCooltPmpPostRunSts 0 "CooltPmpPostRunSts_CooltPmpPostRunFinshd" 1 "CooltPmpPostRunSts_CooltPmpPostRunCncld" 2 "CooltPmpPostRunSts_Resd1" 3 "CooltPmpPostRunSts_Resd2";
VAL_ 684 Edcp2PmpStsFromTMCUCooltPmpSetPostRunReq 0 "CooltPmpSetPostRunReq_CooltPmpSetNoPostRun" 1 "CooltPmpSetPostRunReq_CooltPmpSetPostRun1" 2 "CooltPmpSetPostRunReq_CooltPmpSetPostRun2" 3 "CooltPmpSetPostRunReq_CooltPmpSetPostRun3" 4 "CooltPmpSetPostRunReq_CooltPmpSetPostRun4" 5 "CooltPmpSetPostRunReq_CooltPmpSetPostRun5" 6 "CooltPmpSetPostRunReq_Resd1" 7 "CooltPmpSetPostRunReq_Resd2";
VAL_ 684 Edcp2PmpStsFromTMCUCooltPmpTErr 0 "CooltPmpTErr_CooltPmpNoTErr" 1 "CooltPmpTErr_CooltPmpTErr" 2 "CooltPmpTErr_Resd1" 3 "CooltPmpTErr_Resd2";
VAL_ 684 Edcp2PmpStsFromTMCUCooltPmpUErr 0 "CooltPmpUErr_CooltPmpNoUErr" 1 "CooltPmpUErr_CooltPmpUErr" 2 "CooltPmpUErr_Resd1" 3 "CooltPmpUErr_Resd2";
VAL_ 684 Edcp2PmpStsFromTMCUCooltPmpUnstallSts 0 "CooltPmpUnstallSts_CooltPmpUnstallNotActv" 1 "CooltPmpUnstallSts_CooltPmpUnstallActv" 2 "CooltPmpUnstallSts_Resd1" 3 "CooltPmpUnstallSts_Resd2";
VAL_ 1057 BexvNVMFltFromTMCU 0 "Flt_NoFault" 1 "Flt_Fault";
VAL_ 1057 EexvNVMFltFromTMCU 0 "Flt_NoFault" 1 "Flt_Fault";
VAL_ 1057 ExvNVMFltFromTMCU 0 "Flt_NoFault" 1 "Flt_Fault";
VAL_ 869 CcvmStsFromTMCUVlvBlkFlt 0 "Boolean_FALSE" 1 "Boolean_TRUE";
VAL_ 869 CcvmStsFromTMCUVlvCalibSts 0 "VlvCalibSts_NotInitialized" 1 "VlvCalibSts_Initializing" 2 "VlvCalibSts_Initialized" 3 "VlvCalibSts_Reserved";
VAL_ 869 CcvmStsFromTMCUVlvCmdPosnErr 0 "Boolean_FALSE" 1 "Boolean_TRUE";
VAL_ 869 CcvmStsFromTMCUVlvLoTErr 0 "Boolean_FALSE" 1 "Boolean_TRUE";
VAL_ 869 CcvmStsFromTMCUVlvMoveSts 0 "Boolean_FALSE" 1 "Boolean_TRUE";
VAL_ 869 CcvmStsFromTMCUVlvNVMFlt 0 "Boolean_FALSE" 1 "Boolean_TRUE";
VAL_ 869 CcvmStsFromTMCUVlvOpenCircFlt 0 "Boolean_FALSE" 1 "Boolean_TRUE";
VAL_ 869 CcvmStsFromTMCUVlvOverTErr 0 "Boolean_FALSE" 1 "Boolean_TRUE";
VAL_ 869 CcvmStsFromTMCUVlvOverTrvlFlt 0 "Boolean_FALSE" 1 "Boolean_TRUE";
VAL_ 869 CcvmStsFromTMCUVlvOverTWarn 0 "Boolean_FALSE" 1 "Boolean_TRUE";
VAL_ 869 CcvmStsFromTMCUVlvOverUErr 0 "Boolean_FALSE" 1 "Boolean_TRUE";
VAL_ 869 CcvmStsFromTMCUVlvPosnCtrlTimeOutFlt 0 "Boolean_FALSE" 1 "Boolean_TRUE";
VAL_ 869 CcvmStsFromTMCUVlvPosnUkwnFlt 0 "Boolean_FALSE" 1 "Boolean_TRUE";
VAL_ 869 CcvmStsFromTMCUVlvPreHeatgSts 0 "Boolean_FALSE" 1 "Boolean_TRUE";
VAL_ 869 CcvmStsFromTMCUVlvSelfLearnFlt 0 "Boolean_FALSE" 1 "Boolean_TRUE";
VAL_ 869 CcvmStsFromTMCUVlvShoCircFlt 0 "Boolean_FALSE" 1 "Boolean_TRUE";
VAL_ 869 CcvmStsFromTMCUVlvSpdLvlSts 0 "VlvSpdLvlReq_Invalid" 1 "VlvSpdLvlReq_Level1" 2 "VlvSpdLvlReq_Level2" 3 "VlvSpdLvlReq_Reserved";
VAL_ 869 CcvmStsFromTMCUVlvUnderUErr 0 "Boolean_FALSE" 1 "Boolean_TRUE";
VAL_ 880 CcvVlvStsFromTMCUIntFlt 0 "Boolean_FALSE" 1 "Boolean_TRUE";
VAL_ 880 CcvVlvStsFromTMCUOprFlt 0 "Boolean_FALSE" 1 "Boolean_TRUE";
VAL_ 880 CcvVlvStsFromTMCUTrqSts 0 "VlvTqSts_NoTorque" 1 "VlvTqSts_NominalTorque" 2 "VlvTqSts_Boost20perc" 3 "VlvTqSts_Boost40perc" 4 "VlvTqSts_Boost60perc" 5 "VlvTqSts_Boost80perc" 6 "VlvTqSts_Boost100perc";
VAL_ 672 BexvStsFromTMCUExvBlkErr 0 "Err1_NoErr" 1 "Err1_Err";
VAL_ 672 BexvStsFromTMCUExvCalibSts 0 "ExvCalibSts_NotInitialized" 1 "ExvCalibSts_InitializationInProcess" 2 "ExvCalibSts_Initialized" 3 "ExvCalibSts_Reserved";
VAL_ 672 BexvStsFromTMCUExvElecStsErr 0 "ExvElecStsErr_NoError" 1 "ExvElecStsErr_OpenCircuit" 2 "ExvElecStsErr_ShortCircuit" 3 "ExvElecStsErr_OverTemperatureShutdown" 4 "ExvElecStsErr_IndeterminateElectricFault" 5 "ExvElecStsErr_Reserved";
VAL_ 672 BexvStsFromTMCUExvMovSts 0 "ExvMovSts_NotMove" 1 "ExvMovSts_Moving";
VAL_ 672 BexvStsFromTMCUExvOvrTempErr 0 "Err1_NoErr" 1 "Err1_Err";
VAL_ 672 BexvStsFromTMCUExvOvrTrvlErr 0 "Err1_NoErr" 1 "Err1_Err";
VAL_ 672 BexvStsFromTMCUExvPreHeatgSts 0 "OnOff1_Off" 1 "OnOff1_On";
VAL_ 672 BexvStsFromTMCUExvVoltgRangErr 0 "VoltgRangErr_NoErr" 1 "VoltgRangErr_UnderVoltageErr" 2 "VoltgRangErr_OverVoltageErr" 3 "VoltgRangErr_Reserved";
VAL_ 672 EexvStsFromTMCUExvBlkErr 0 "Err1_NoErr" 1 "Err1_Err";
VAL_ 672 EexvStsFromTMCUExvCalibSts 0 "ExvCalibSts_NotInitialized" 1 "ExvCalibSts_InitializationInProcess" 2 "ExvCalibSts_Initialized" 3 "ExvCalibSts_Reserved";
VAL_ 672 EexvStsFromTMCUExvElecStsErr 0 "ExvElecStsErr_NoError" 1 "ExvElecStsErr_OpenCircuit" 2 "ExvElecStsErr_ShortCircuit" 3 "ExvElecStsErr_OverTemperatureShutdown" 4 "ExvElecStsErr_IndeterminateElectricFault" 5 "ExvElecStsErr_Reserved";
VAL_ 672 EexvStsFromTMCUExvMovSts 0 "ExvMovSts_NotMove" 1 "ExvMovSts_Moving";
VAL_ 672 EexvStsFromTMCUExvOvrTempErr 0 "Err1_NoErr" 1 "Err1_Err";
VAL_ 672 EexvStsFromTMCUExvOvrTrvlErr 0 "Err1_NoErr" 1 "Err1_Err";
VAL_ 672 EexvStsFromTMCUExvPreHeatgSts 0 "OnOff1_Off" 1 "OnOff1_On";
VAL_ 672 EexvStsFromTMCUExvVoltgRangErr 0 "VoltgRangErr_NoErr" 1 "VoltgRangErr_UnderVoltageErr" 2 "VoltgRangErr_OverVoltageErr" 3 "VoltgRangErr_Reserved";
VAL_ 675 ExvStsFromTMCUExvBlkErr 0 "Err1_NoErr" 1 "Err1_Err";
VAL_ 675 ExvStsFromTMCUExvCalibSts 0 "ExvCalibSts_NotInitialized" 1 "ExvCalibSts_InitializationInProcess" 2 "ExvCalibSts_Initialized" 3 "ExvCalibSts_Reserved";
VAL_ 675 ExvStsFromTMCUExvElecStsErr 0 "ExvElecStsErr_NoError" 1 "ExvElecStsErr_OpenCircuit" 2 "ExvElecStsErr_ShortCircuit" 3 "ExvElecStsErr_OverTemperatureShutdown" 4 "ExvElecStsErr_IndeterminateElectricFault" 5 "ExvElecStsErr_Reserved";
VAL_ 675 ExvStsFromTMCUExvMovSts 0 "ExvMovSts_NotMove" 1 "ExvMovSts_Moving";
VAL_ 675 ExvStsFromTMCUExvOvrTempErr 0 "Err1_NoErr" 1 "Err1_Err";
VAL_ 675 ExvStsFromTMCUExvOvrTrvlErr 0 "Err1_NoErr" 1 "Err1_Err";
VAL_ 675 ExvStsFromTMCUExvPreHeatgSts 0 "OnOff1_Off" 1 "OnOff1_On";
VAL_ 675 ExvStsFromTMCUExvVoltgRangErr 0 "VoltgRangErr_NoErr" 1 "VoltgRangErr_UnderVoltageErr" 2 "VoltgRangErr_OverVoltageErr" 3 "VoltgRangErr_Reserved";
VAL_ 675 HctvStsFromTMCUVlvBlkFlt 0 "Boolean_FALSE" 1 "Boolean_TRUE";
VAL_ 675 HctvStsFromTMCUVlvCalibSts 0 "VlvCalibSts_NotInitialized" 1 "VlvCalibSts_Initializing" 2 "VlvCalibSts_Initialized" 3 "VlvCalibSts_Reserved";
VAL_ 675 HctvStsFromTMCUVlvCmdPosnErr 0 "Boolean_FALSE" 1 "Boolean_TRUE";
VAL_ 675 HctvStsFromTMCUVlvLoTErr 0 "Boolean_FALSE" 1 "Boolean_TRUE";
VAL_ 675 HctvStsFromTMCUVlvMoveSts 0 "Boolean_FALSE" 1 "Boolean_TRUE";
VAL_ 675 HctvStsFromTMCUVlvNVMFlt 0 "Boolean_FALSE" 1 "Boolean_TRUE";
VAL_ 675 HctvStsFromTMCUVlvOpenCircFlt 0 "Boolean_FALSE" 1 "Boolean_TRUE";
VAL_ 675 HctvStsFromTMCUVlvOverTErr 0 "Boolean_FALSE" 1 "Boolean_TRUE";
VAL_ 675 HctvStsFromTMCUVlvOverTrvlFlt 0 "Boolean_FALSE" 1 "Boolean_TRUE";
VAL_ 675 HctvStsFromTMCUVlvOverTWarn 0 "Boolean_FALSE" 1 "Boolean_TRUE";
VAL_ 675 HctvStsFromTMCUVlvOverUErr 0 "Boolean_FALSE" 1 "Boolean_TRUE";
VAL_ 675 HctvStsFromTMCUVlvPosnCtrlTimeOutFlt 0 "Boolean_FALSE" 1 "Boolean_TRUE";
VAL_ 675 HctvStsFromTMCUVlvPosnUkwnFlt 0 "Boolean_FALSE" 1 "Boolean_TRUE";
VAL_ 675 HctvStsFromTMCUVlvPreHeatgSts 0 "Boolean_FALSE" 1 "Boolean_TRUE";
VAL_ 675 HctvStsFromTMCUVlvSelfLearnFlt 0 "Boolean_FALSE" 1 "Boolean_TRUE";
VAL_ 675 HctvStsFromTMCUVlvShoCircFlt 0 "Boolean_FALSE" 1 "Boolean_TRUE";
VAL_ 675 HctvStsFromTMCUVlvSpdLvlSts 0 "VlvSpdLvlReq_Invalid" 1 "VlvSpdLvlReq_Level1" 2 "VlvSpdLvlReq_Level2" 3 "VlvSpdLvlReq_Reserved";
VAL_ 675 HctvStsFromTMCUVlvUnderUErr 0 "Boolean_FALSE" 1 "Boolean_TRUE";
VAL_ 337 TiAndDateIndcnDataValid 0 "NoYes1_No" 1 "NoYes1_Yes";
VAL_ 282 StcStsToDmcFrnt 0 "ModeDMC_Off" 1 "ModeDMC_Rpm" 2 "ModeDMC_Trq";
VAL_ 282 StcStsToDmcRear 0 "ModeDMC_Off" 1 "ModeDMC_Rpm" 2 "ModeDMC_Trq";
VAL_ 118 BrkPedlPsdBrkPedlNotPsdSafe 0 "NoYes1_No" 1 "NoYes1_Yes";
VAL_ 118 BrkPedlPsdBrkPedlPsd 0 "NoYes1_No" 1 "NoYes1_Yes";
VAL_ 118 BrkPedlPsdQf 0 "GenQf1_UndefindDataAccur" 1 "GenQf1_TmpUndefdData" 2 "GenQf1_DataAccurNotWithinSpcn" 3 "GenQf1_AccurData";
VAL_ 118 VehMtnStVehMtnSt 0 "VehMtnSt2_Ukwn" 1 "VehMtnSt2_StandStillVal1" 2 "VehMtnSt2_StandStillVal2" 3 "VehMtnSt2_StandStillVal3" 4 "VehMtnSt2_RollgFwdVal1" 5 "VehMtnSt2_RollgFwdVal2" 6 "VehMtnSt2_RollgBackwVal1" 7 "VehMtnSt2_RollgBackwVal2";
VAL_ 118 VehSpdLgtQf 0 "GenQf1_UndefindDataAccur" 1 "GenQf1_TmpUndefdData" 2 "GenQf1_DataAccurNotWithinSpcn" 3 "GenQf1_AccurData";
VAL_ 129 ADataRawSafeALat1Qf 0 "Qf1_DevOfDataUndefd" 1 "Qf1_DataTmpUndefdAndEvlnInProgs" 2 "Qf1_DevOfDataNotWithinRngAllwd" 3 "Qf1_DataCalcdWithDevDefd";
VAL_ 129 ADataRawSafeALgt1Qf 0 "Qf1_DevOfDataUndefd" 1 "Qf1_DataTmpUndefdAndEvlnInProgs" 2 "Qf1_DevOfDataNotWithinRngAllwd" 3 "Qf1_DataCalcdWithDevDefd";
VAL_ 129 ADataRawSafeAVertQf 0 "Qf1_DevOfDataUndefd" 1 "Qf1_DataTmpUndefdAndEvlnInProgs" 2 "Qf1_DevOfDataNotWithinRngAllwd" 3 "Qf1_DataCalcdWithDevDefd";
VAL_ 313 LockgCenStsLockSt 0 "LockSt3_LockUndefd" 1 "LockSt3_LockUnlckd" 2 "LockSt3_LockTrUnlckd" 3 "LockSt3_LockLockd";
VAL_ 313 LockgCenStsTrigSrc 0 "LockTrigSrc2_NoTrigSrc" 1 "LockTrigSrc2_KeyRem" 2 "LockTrigSrc2_Keyls" 3 "LockTrigSrc2_IntrSwt" 4 "LockTrigSrc2_SpdAut" 5 "LockTrigSrc2_TmrAut" 6 "LockTrigSrc2_Slam" 7 "LockTrigSrc2_Telm" 8 "LockTrigSrc2_Crash" 9 "LockTrigSrc2_Apprch" 10 "LockTrigSrc2_OutsOth" 11 "LockTrigSrc2_InsOth";
VAL_ 313 LockgCenStsUpdEve 0 "Boolean_FALSE" 1 "Boolean_TRUE";
VAL_ 353 V2XDchaSwt 0 "DisChrgrSW_Off" 1 "DisChrgrSW_V2V" 2 "DisChrgrSW_V2L";
VAL_ 609 BattPreHeatgLvl 0 "ModeLvl_Default" 1 "ModeLvl_Econ" 2 "ModeLvl_Sport" 3 "ModeLvl_Reserved";
VAL_ 609 MaintainBattTCtrl 0 "OnOff1_Off" 1 "OnOff1_On";
VAL_ 597 ImobEngMgrReq2ImobEngMgrCmdTar1 0 "ImobEngMgrReqCmd_ImobEngCmdTarIdle" 1 "ImobEngMgrReqCmd_ImobEngMtnStrtReqCmd" 2 "ImobEngMgrReqCmd_ImobEngNoMtnStrtReqCmd" 3 "ImobEngMgrReqCmd_ImobEngTurnOffCmd";
VAL_ 86 CnclBookTrvlReq 0 "ReqSts1_NotReqd" 1 "ReqSts1_Reqd";
VAL_ 86 TwliBriSts 0 "TwliBriSts1_Night" 1 "TwliBriSts1_Day";
VAL_ 86 VehModMngtGlbSafe1CarModSts1 0 "CarModSts1_CarModNorm" 1 "CarModSts1_CarModTrnsp" 2 "CarModSts1_CarModFcy" 3 "CarModSts1_CarModCrash" 5 "CarModSts1_CarModDyno";
VAL_ 86 VehModMngtGlbSafe1FltEgyCnsWdSts 0 "FltEgyCns1_NoFlt" 1 "FltEgyCns1_Flt";
VAL_ 86 VehModMngtGlbSafe1UsgModSts 0 "UsgModSts1_UsgModAbdnd" 1 "UsgModSts1_UsgModInActv" 2 "UsgModSts1_UsgModCnvinc" 11 "UsgModSts1_UsgModActv" 13 "UsgModSts1_UsgModDrvg";
VAL_ 645 AmbTRawQly 0 "GenQf1_UndefindDataAccur" 1 "GenQf1_TmpUndefdData" 2 "GenQf1_DataAccurNotWithinSpcn" 3 "GenQf1_AccurData";
VAL_ 645 VehBattUSysUQf 0 "GenQf1_UndefindDataAccur" 1 "GenQf1_TmpUndefdData" 2 "GenQf1_DataAccurNotWithinSpcn" 3 "GenQf1_AccurData";
VAL_ 667 ChrgLidAcSts 0 "DoorSts2_Ukwn" 1 "DoorSts2_Opend" 2 "DoorSts2_Clsd";
VAL_ 667 DrvModReq 0 "DrvModReqType1_Undefd" 1 "DrvModReqType1_ECO" 2 "DrvModReqType1_Comfort_Normal" 3 "DrvModReqType1_Dynamic_Sport" 4 "DrvModReqType1_Individual" 5 "DrvModReqType1_Offroad_CrossTerrain" 6 "DrvModReqType1_Adaptive" 7 "DrvModReqType1_Race" 8 "DrvModReqType1_Pure_EV" 9 "DrvModReqType1_Hybrid" 10 "DrvModReqType1_Power" 11 "DrvModReqType1_Snow" 12 "DrvModReqType1_Sand" 13 "DrvModReqType1_Mud" 14 "DrvModReqType1_Rock" 15 "DrvModReqType1_Err";
VAL_ 49 ChrgLidDCorAcDcSts 0 "DoorSts2_Ukwn" 1 "DoorSts2_Opend" 2 "DoorSts2_Clsd";
VAL_ 1051 AmbTEstimdQf 0 "HvacTIfQf_SnsrDataNotOk" 1 "HvacTIfQf_SnsrDataOk";
VAL_ 304 PtActrReModReq 0 "PtActrMod1_NoReq" 1 "PtActrMod1_ActrMod1" 2 "PtActrMod1_ActrMod2" 3 "PtActrMod1_ActrMod3";
VAL_ 819 GpsStatus 0 "NoYes1_No" 1 "NoYes1_Yes";
VAL_ 819 UTCTiFromEthDataValid 0 "NoYes1_No" 1 "NoYes1_Yes";
VAL_ 57 DoorDrvrLockSts 0 "LockSts2_LockStsUkwn" 1 "LockSts2_Unlckd" 2 "LockSts2_Lockd" 3 "LockSts2_SafeLockd";
VAL_ 279 BookChrgnActvdReq 0 "Boolean_FALSE" 1 "Boolean_TRUE";
VAL_ 279 BookStopTiAchieved 0 "Boolean_FALSE" 1 "Boolean_TRUE";
VAL_ 279 ChrgnCtrlToEndOrRetartFromApp 0 "OnOffNoReq_NoReq" 1 "OnOffNoReq_On" 2 "OnOffNoReq_Off";
VAL_ 279 ChrgNowReq 0 "Boolean_FALSE" 1 "Boolean_TRUE";
VAL_ 279 ChrgSoftSwCtrlSt 0 "OnOffNoReq_NoReq" 1 "OnOffNoReq_On" 2 "OnOffNoReq_Off";
VAL_ 279 TelmBookChrgnReq 0 "OnOffNoReq_NoReq" 1 "OnOffNoReq_On" 2 "OnOffNoReq_Off";
VAL_ 568 ActvnOfSymIllmn 0 "Boolean_FALSE" 1 "Boolean_TRUE";
VAL_ 563 Edcp2PmpCmdCooltPmpPostRunReq 0 "CooltPmpPostRun_CooltPmpNoPostRun" 1 "CooltPmpPostRun_CooltPmpPostRun1" 2 "CooltPmpPostRun_CooltPmpPostRun2" 3 "CooltPmpPostRun_CooltPmpPostRun3" 4 "CooltPmpPostRun_CooltPmpPostRun4" 5 "CooltPmpPostRun_Resvd1" 6 "CooltPmpPostRun_Resvd2" 7 "CooltPmpPostRun_Resvd3";
VAL_ 563 EexvPosnReqExvCalibReq 0 "ExvCalibReq_NoReq" 1 "ExvCalibReq_InitializationReq";
VAL_ 563 EexvPosnReqExvHeatdReq 0 "ExvHeatdReq_NoReq" 1 "ExvHeatdReq_PreHeatedReq";
VAL_ 563 EexvPosnReqExvMovEnable 0 "EXVNotEnable" 1 "EXVEnable";
VAL_ 563 ExvPosnReqExvCalibReq 0 "ExvCalibReq_NoReq" 1 "ExvCalibReq_InitializationReq";
VAL_ 563 ExvPosnReqExvHeatdReq 0 "ExvHeatdReq_NoReq" 1 "ExvHeatdReq_PreHeatedReq";
VAL_ 563 ExvPosnReqExvMovEnable 0 "EXVNotEnable" 1 "EXVEnable";
VAL_ 563 HeatrPmpCmdCooltPmpPostRunReq 0 "CooltPmpPostRun_CooltPmpNoPostRun" 1 "CooltPmpPostRun_CooltPmpPostRun1" 2 "CooltPmpPostRun_CooltPmpPostRun2" 3 "CooltPmpPostRun_CooltPmpPostRun3" 4 "CooltPmpPostRun_CooltPmpPostRun4" 5 "CooltPmpPostRun_Resvd1" 6 "CooltPmpPostRun_Resvd2" 7 "CooltPmpPostRun_Resvd3";
VAL_ 563 HvBattPmpCmdCooltPmpPostRunReq 0 "CooltPmpPostRun_CooltPmpNoPostRun" 1 "CooltPmpPostRun_CooltPmpPostRun1" 2 "CooltPmpPostRun_CooltPmpPostRun2" 3 "CooltPmpPostRun_CooltPmpPostRun3" 4 "CooltPmpPostRun_CooltPmpPostRun4" 5 "CooltPmpPostRun_Resvd1" 6 "CooltPmpPostRun_Resvd2" 7 "CooltPmpPostRun_Resvd3";
VAL_ 633 CcvmCmdVlvActvSaveReq 0 "Boolean_FALSE" 1 "Boolean_TRUE";
VAL_ 633 CcvmCmdVlvCalibReq 0 "Boolean_FALSE" 1 "Boolean_TRUE";
VAL_ 633 CcvmCmdVlvHeatdReq 0 "Boolean_FALSE" 1 "Boolean_TRUE";
VAL_ 633 CcvmCmdVlvMovEna 0 "EXVNotEnable" 1 "EXVEnable";
VAL_ 633 CcvmCmdVlvSpdLvlReq 0 "VlvSpdLvlReq_Invalid" 1 "VlvSpdLvlReq_Level1" 2 "VlvSpdLvlReq_Level2" 3 "VlvSpdLvlReq_Reserved";
VAL_ 633 CcvPosReqReqEnad 0 "Boolean_FALSE" 1 "Boolean_TRUE";
VAL_ 633 CcvPosReqRstPos 0 "VlvRst_NoReset" 1 "VlvRst_ResetToLow" 2 "VlvRst_ResetToHigh" 3 "VlvRst_Reserved";
VAL_ 633 CcvPosReqTrqReq 0 "VlvTqSts_NoTorque" 1 "VlvTqSts_NominalTorque" 2 "VlvTqSts_Boost20perc" 3 "VlvTqSts_Boost40perc" 4 "VlvTqSts_Boost60perc" 5 "VlvTqSts_Boost80perc" 6 "VlvTqSts_Boost100perc";
VAL_ 633 HctvCmdVlvActvSaveReq 0 "Boolean_FALSE" 1 "Boolean_TRUE";
VAL_ 633 HctvCmdVlvCalibReq 0 "Boolean_FALSE" 1 "Boolean_TRUE";
VAL_ 633 HctvCmdVlvHeatdReq 0 "Boolean_FALSE" 1 "Boolean_TRUE";
VAL_ 633 HctvCmdVlvMovEna 0 "EXVNotEnable" 1 "EXVEnable";
VAL_ 633 HctvCmdVlvSpdLvlReq 0 "VlvSpdLvlReq_Invalid" 1 "VlvSpdLvlReq_Level1" 2 "VlvSpdLvlReq_Level2" 3 "VlvSpdLvlReq_Reserved";
VAL_ 1156 PTMStateVeh 0 "PTMStateVeh_Init" 1 "PTMStateVeh_StandBy" 2 "PTMStateVeh_ServiceRequest" 3 "PTMStateVeh_Working" 4 "PTMStateVeh_TemporaryExit" 5 "PTMStateVeh_Fault";
VAL_ 1312 WakeUpReasonsforXCU 0 "WakeupReasons_667949" 1 "WakeupReasons_667950" 2 "WakeupReasons_169654" 3 "WakeupReasons_667951" 4 "WakeupReasons_168965" 5 "WakeupReasons_197643" 6 "WakeupReasons_264933" 7 "WakeupReasons_45654" 8 "WakeupReasons_22058" 9 "WakeupReasons_49446" 10 "WakeupReasons_22060" 11 "WakeupReasons_269740" 12 "WakeupReasons_269735" 13 "WakeupReasons_269739" 14 "WakeupReasons_658500" 15 "WakeupReasons_21901" 16 "WakeupReasons_45793" 17 "WakeupReasons_45794" 18 "WakeupReasons_22005" 19 "WakeupReasons_22013" 20 "WakeupReasons_22100" 21 "WakeupReasons_45659" 22 "WakeupReasons_45657" 23 "WakeupReasons_140084" 24 "WakeupReasons_21973" 25 "WakeupReasons_91253" 26 "WakeupReasons_88123" 27 "WakeupReasons_88125" 28 "WakeupReasons_321583" 29 "WakeupReasons_74188" 30 "WakeupReasons_667945" 31 "WakeupReasons_169655" 32 "WakeupReasons_667948" 33 "WakeupReasons_168966" 34 "WakeupReasons_170865" 35 "WakeupReasons_197642" 36 "WakeupReasons_264876" 37 "WakeupReasons_191050" 38 "WakeupReasons_182033" 39 "WakeupReasons_200937" 40 "WakeupReasons_170807" 41 "WakeupReasons_319139" 42 "WakeupReasons_100298" 43 "WakeupReasons_100275" 44 "WakeupReasons_100300" 45 "WakeupReasons_100278" 46 "WakeupReasons_100281" 47 "WakeupReasons_265333" 48 "WakeupReasons_108776" 49 "WakeupReasons_176921" 50 "WakeupReasons_197826" 51 "WakeupReasons_185670" 52 "WakeupReasons_161066" 53 "WakeupReasons_200156" 54 "WakeupReasons_225696" 55 "WakeupReasons_21997" 56 "WakeupReasons_45656" 57 "WakeupReasons_266860" 58 "WakeupReasons_169894" 59 "WakeupReasons_320282" 60 "WakeupReasons_319422" 61 "WakeupReasons_320277" 62 "WakeupReasons_355601" 63 "WakeupReasons_360904" 64 "WakeupReasons_361505" 65 "WakeupReasons_361509" 66 "WakeupReasons_645094" 67 "WakeupReasons_68676" 68 "WakeupReasons_360008" 69 "WakeupReasons_109382" 70 "WakeupReasons_119273" 71 "WakeupReasons_224065" 72 "WakeupReasons_68644" 73 "WakeupReasons_109364" 74 "WakeupReasons_68481" 75 "WakeupReasons_224061" 76 "WakeupReasons_360006" 77 "WakeupReasons_138997" 78 "WakeupReasons_634696" 79 "WakeupReasons_645810" 80 "WakeupReasons_297868" 81 "WakeupReasons_315364" 82 "WakeupReasons_109367" 83 "WakeupReasons_320126" 84 "WakeupReasons_109387" 85 "WakeupReasons_634710" 86 "WakeupReasons_338820" 87 "WakeupReasons_67182" 88 "WakeupReasons_152237" 89 "WakeupReasons_145707" 90 "WakeupReasons_199172" 91 "WakeupReasons_144897" 92 "WakeupReasons_186489" 93 "WakeupReasons_144970" 94 "WakeupReasons_152786" 95 "WakeupReasons_264932" 96 "WakeupReasons_264934" 97 "WakeupReasons_356190" 98 "WakeupReasons_145688" 99 "WakeupReasons_95444" 100 "WakeupReasons_169945" 101 "WakeupReasons_140678" 102 "WakeupReasons_222553" 103 "WakeupReasons_224831" 104 "WakeupReasons_201815" 105 "WakeupReasons_45864" 106 "WakeupReasons_659549" 107 "WakeupReasons_45866" 108 "WakeupReasons_45867" 109 "WakeupReasons_169884" 110 "WakeupReasons_264962" 111 "WakeupReasons_201348" 112 "WakeupReasons_320287" 113 "WakeupReasons_156412" 114 "WakeupReasons_133749" 115 "WakeupReasons_355409" 116 "WakeupReasons_636692" 117 "WakeupReasons_533044" 118 "WakeupReasons_106774" 119 "WakeupReasons_145311" 120 "WakeupReasons_145319" 121 "WakeupReasons_152774" 122 "WakeupReasons_145330" 123 "WakeupReasons_145388" 124 "WakeupReasons_145399" 125 "WakeupReasons_145362" 126 "WakeupReasons_145385" 127 "WakeupReasons_145373" 128 "WakeupReasons_145288" 129 "WakeupReasons_145419" 130 "WakeupReasons_145454" 131 "WakeupReasons_145462" 132 "WakeupReasons_269156" 133 "WakeupReasons_300427" 134 "WakeupReasons_220322" 135 "WakeupReasons_224617" 136 "WakeupReasons_224634" 137 "WakeupReasons_300682" 138 "WakeupReasons_264958" 139 "WakeupReasons_160597" 140 "WakeupReasons_160602" 141 "WakeupReasons_108841" 142 "WakeupReasons_265569" 143 "WakeupReasons_526429" 144 "WakeupReasons_514545" 145 "WakeupReasons_265232" 146 "WakeupReasons_644550" 147 "WakeupReasons_317616" 148 "WakeupReasons_354791" 149 "WakeupReasons_320631" 150 "WakeupReasons_337565" 151 "WakeupReasons_532007" 152 "WakeupReasons_514503" 153 "WakeupReasons_299117" 154 "WakeupReasons_340667" 155 "WakeupReasons_321845" 156 "WakeupReasons_179103" 157 "WakeupReasons_108810" 158 "WakeupReasons_322857" 159 "WakeupReasons_658603" 160 "WakeupReasons_197648" 161 "WakeupReasons_160596" 162 "WakeupReasons_361272" 163 "WakeupReasons_361279" 164 "WakeupReasons_265305" 165 "WakeupReasons_265328" 166 "WakeupReasons_265330" 167 "WakeupReasons_298808" 168 "WakeupReasons_515804" 169 "WakeupReasons_514502" 170 "WakeupReasons_645753" 171 "WakeupReasons_646109" 172 "WakeupReasons_299547" 173 "WakeupReasons_318342" 174 "WakeupReasons_360543" 175 "WakeupReasons_356549" 176 "WakeupReasons_198484" 177 "WakeupReasons_300681" 178 "WakeupReasons_359211" 179 "WakeupReasons_534077" 180 "WakeupReasons_525705" 181 "WakeupReasons_360299" 182 "WakeupReasons_526445" 183 "WakeupReasons_534145" 184 "WakeupReasons_192030" 185 "WakeupReasons_652361" 186 "WakeupReasons_355214" 187 "WakeupReasons_321317" 188 "WakeupReasons_359187" 189 "WakeupReasons_321057" 190 "WakeupReasons_321319" 191 "WakeupReasons_321323" 192 "WakeupReasons_321077" 193 "WakeupReasons_320895" 194 "WakeupReasons_655340" 195 "WakeupReasons_636556" 196 "WakeupReasons_108834" 197 "WakeupReasons_265937" 198 "WakeupReasons_533050" 199 "WakeupReasons_526426" 200 "WakeupReasons_264712" 201 "WakeupReasons_319401" 202 "WakeupReasons_643973" 203 "WakeupReasons_223715" 204 "WakeupReasons_199159" 205 "WakeupReasons_318382" 206 "WakeupReasons_226967" 207 "WakeupReasons_531743" 208 "WakeupReasons_360542" 209 "WakeupReasons_264726" 210 "WakeupReasons_535214" 211 "WakeupReasons_335068" 212 "WakeupReasons_316796" 213 "WakeupReasons_526438" 214 "WakeupReasons_198433" 215 "WakeupReasons_225961" 216 "WakeupReasons_197665" 217 "WakeupReasons_224550" 218 "WakeupReasons_667962" 219 "WakeupReasons_667953" 220 "WakeupReasons_110885" 221 "WakeupReasons_224552" 222 "WakeupReasons_224553" 223 "WakeupReasons_652546" 224 "WakeupReasons_331194" 225 "WakeupReasons_667820" 226 "WakeupReasons_659350" 227 "WakeupReasons_101706" 228 "WakeupReasons_101725" 229 "WakeupReasons_101728" 230 "WakeupReasons_101727" 231 "WakeupReasons_166267" 232 "WakeupReasons_156440" 233 "WakeupReasons_95949" 234 "WakeupReasons_112799" 235 "WakeupReasons_146470" 236 "WakeupReasons_176748" 237 "WakeupReasons_223920" 238 "WakeupReasons_668531" 239 "WakeupReasons_670087" 240 "WakeupReasons_668529" 241 "WakeupReasons_45858" 242 "WakeupReasons_315981" 243 "WakeupReasons_533370" 244 "WakeupReasons_533371" 245 "WakeupReasons_533372" 246 "WakeupReasons_241902" 247 "WakeupReasons_359559" 248 "WakeupReasons_516327" 249 "WakeupReasons_533872" 250 "WakeupReasons_45856" 251 "WakeupReasons_45853" 252 "WakeupReasons_45854" 253 "WakeupReasons_45852" 254 "WakeupReasons_45851" 255 "WakeupReasons_45850" 256 "WakeupReasons_45849" 257 "WakeupReasons_636801" 258 "WakeupReasons_109466" 259 "WakeupReasons_109467" 260 "WakeupReasons_670345" 261 "WakeupReasons_NMPDUReceived" 262 "WakeupReasons_358832" 263 "WakeupReasons_200683" 264 "WakeupReasons_198452" 265 "WakeupReasons_185457" 266 "WakeupReasons_185490" 267 "WakeupReasons_4471" 268 "WakeupReasons_269034" 269 "WakeupReasons_215560" 270 "WakeupReasons_312881" 271 "WakeupReasons_269140" 272 "WakeupReasons_197653" 273 "WakeupReasons_337991" 274 "WakeupReasons_658188" 275 "WakeupReasons_674953" 276 "WakeupReasons_675064" 277 "WakeupReasons_674958" 278 "WakeupReasons_675494" 279 "WakeupReasons_675837" 280 "WakeupReasons_667879" 281 "WakeupReasons_667947" 282 "WakeupReasons_676265" 283 "WakeupReasons_669465" 284 "WakeupReasons_670928" 285 "WakeupReasons_669447" 286 "WakeupReasons_667922" 287 "WakeupReasons_670753" 288 "WakeupReasons_668395" 289 "WakeupReasons_668393" 290 "WakeupReasons_667850" 291 "WakeupReasons_667848" 292 "WakeupReasons_311279" 293 "WakeupReasons_182918" 294 "WakeupReasons_667988" 295 "WakeupReasons_532555" 296 "WakeupReasons_532556" 297 "WakeupReasons_113348" 298 "WakeupReasons_193474" 299 "WakeupReasons_667871" 300 "WakeupReasons_670966" 301 "WakeupReasons_667985" 302 "WakeupReasons_670354" 303 "WakeupReasons_46017" 304 "WakeupReasons_675742" 305 "WakeupReasons_106669" 306 "WakeupReasons_80609" 307 "WakeupReasons_199714" 308 "WakeupReasons_200090" 309 "WakeupReasons_139075" 310 "WakeupReasons_268983" 311 "WakeupReasons_265131" 312 "WakeupReasons_263473" 313 "WakeupReasons_45887" 314 "WakeupReasons_69678" 315 "WakeupReasons_69679" 316 "WakeupReasons_45897" 317 "WakeupReasons_45898" 318 "WakeupReasons_80608" 319 "WakeupReasons_45869" 320 "WakeupReasons_45870" 321 "WakeupReasons_45872" 322 "WakeupReasons_45875" 323 "WakeupReasons_45871" 324 "WakeupReasons_45876" 325 "WakeupReasons_667980" 326 "WakeupReasons_45877" 327 "WakeupReasons_667973" 328 "WakeupReasons_670962" 329 "WakeupReasons_45888" 330 "WakeupReasons_45890" 331 "WakeupReasons_667869" 332 "WakeupReasons_45846" 333 "WakeupReasons_45847" 334 "WakeupReasons_45848" 335 "WakeupReasons_262872" 336 "WakeupReasons_127924" 337 "WakeupReasons_127926" 338 "WakeupReasons_674223" 339 "WakeupReasons_667982" 340 "WakeupReasons_657121" 341 "WakeupReasons_265745" 342 "WakeupReasons_657120" 343 "WakeupReasons_675564" 344 "WakeupReasons_197644" 345 "WakeupReasons_264943" 346 "WakeupReasons_264697" 347 "WakeupReasons_69216" 348 "WakeupReasons_128671" 349 "WakeupReasons_356598" 350 "WakeupReasons_675745" 351 "WakeupReasons_667983" 352 "WakeupReasons_667987" 353 "WakeupReasons_75103" 354 "WakeupReasons_305818" 355 "WakeupReasons_670942" 356 "WakeupReasons_532932" 357 "WakeupReasons_532933" 358 "WakeupReasons_83199" 359 "WakeupReasons_45900" 360 "WakeupReasons_88458" 361 "WakeupReasons_329457" 362 "WakeupReasons_45902" 363 "WakeupReasons_224211" 364 "WakeupReasons_667981" 365 "WakeupReasons_667874" 366 "WakeupReasons_46020" 367 "WakeupReasons_667842" 368 "WakeupReasons_145161" 369 "WakeupReasons_233755" 370 "WakeupReasons_297056" 371 "WakeupReasons_264691" 372 "WakeupReasons_262871" 373 "WakeupReasons_264964" 374 "WakeupReasons_667872" 375 "WakeupReasons_45655" 376 "WakeupReasons_177214" 377 "WakeupReasons_671005" 378 "WakeupReasons_680712" 379 "WakeupReasons_669822" 380 "WakeupReasons_668523" 381 "WakeupReasons_680974" 382 "WakeupReasons_680975" 383 "WakeupReasons_681028" 384 "WakeupReasons_670462" 385 "WakeupReasons_681134" 386 "WakeupReasons_681031" 387 "WakeupReasons_681711" 388 "WakeupReasons_682034" 389 "WakeupReasons_674839" 390 "WakeupReasons_681915" 391 "WakeupReasons_682032" 392 "WakeupReasons_682037" 393 "WakeupReasons_682688" 394 "WakeupReasons_681789" 395 "WakeupReasons_682023" 396 "WakeupReasons_681023" 397 "WakeupReasons_676285" 398 "WakeupReasons_682077" 399 "WakeupReasons_682076" 400 "WakeupReasons_682078" 401 "WakeupReasons_682153" 402 "WakeupReasons_682155" 403 "WakeupReasons_682152" 404 "WakeupReasons_682154" 405 "WakeupReasons_682074";
VAL_ 1376 VFCVectorXCUVFCid0 0 "VFCOnOff_Off" 1 "VFCOnOff_On";
VAL_ 1376 VFCVectorXCUVFCid1 0 "VFCOnOff_Off" 1 "VFCOnOff_On";
VAL_ 1376 VFCVectorXCUVFCid10 0 "VFCOnOff_Off" 1 "VFCOnOff_On";
VAL_ 1376 VFCVectorXCUVFCid11 0 "VFCOnOff_Off" 1 "VFCOnOff_On";
VAL_ 1376 VFCVectorXCUVFCid12 0 "VFCOnOff_Off" 1 "VFCOnOff_On";
VAL_ 1376 VFCVectorXCUVFCid13 0 "VFCOnOff_Off" 1 "VFCOnOff_On";
VAL_ 1376 VFCVectorXCUVFCid14 0 "VFCOnOff_Off" 1 "VFCOnOff_On";
VAL_ 1376 VFCVectorXCUVFCid15 0 "VFCOnOff_Off" 1 "VFCOnOff_On";
VAL_ 1376 VFCVectorXCUVFCid16 0 "VFCOnOff_Off" 1 "VFCOnOff_On";
VAL_ 1376 VFCVectorXCUVFCid17 0 "VFCOnOff_Off" 1 "VFCOnOff_On";
VAL_ 1376 VFCVectorXCUVFCid18 0 "VFCOnOff_Off" 1 "VFCOnOff_On";
VAL_ 1376 VFCVectorXCUVFCid19 0 "VFCOnOff_Off" 1 "VFCOnOff_On";
VAL_ 1376 VFCVectorXCUVFCid2 0 "VFCOnOff_Off" 1 "VFCOnOff_On";
VAL_ 1376 VFCVectorXCUVFCid20 0 "VFCOnOff_Off" 1 "VFCOnOff_On";
VAL_ 1376 VFCVectorXCUVFCid21 0 "VFCOnOff_Off" 1 "VFCOnOff_On";
VAL_ 1376 VFCVectorXCUVFCid22 0 "VFCOnOff_Off" 1 "VFCOnOff_On";
VAL_ 1376 VFCVectorXCUVFCid23 0 "VFCOnOff_Off" 1 "VFCOnOff_On";
VAL_ 1376 VFCVectorXCUVFCid24 0 "VFCOnOff_Off" 1 "VFCOnOff_On";
VAL_ 1376 VFCVectorXCUVFCid25 0 "VFCOnOff_Off" 1 "VFCOnOff_On";
VAL_ 1376 VFCVectorXCUVFCid26 0 "VFCOnOff_Off" 1 "VFCOnOff_On";
VAL_ 1376 VFCVectorXCUVFCid27 0 "VFCOnOff_Off" 1 "VFCOnOff_On";
VAL_ 1376 VFCVectorXCUVFCid28 0 "VFCOnOff_Off" 1 "VFCOnOff_On";
VAL_ 1376 VFCVectorXCUVFCid29 0 "VFCOnOff_Off" 1 "VFCOnOff_On";
VAL_ 1376 VFCVectorXCUVFCid3 0 "VFCOnOff_Off" 1 "VFCOnOff_On";
VAL_ 1376 VFCVectorXCUVFCid30 0 "VFCOnOff_Off" 1 "VFCOnOff_On";
VAL_ 1376 VFCVectorXCUVFCid31 0 "VFCOnOff_Off" 1 "VFCOnOff_On";
VAL_ 1376 VFCVectorXCUVFCid32 0 "VFCOnOff_Off" 1 "VFCOnOff_On";
VAL_ 1376 VFCVectorXCUVFCid33 0 "VFCOnOff_Off" 1 "VFCOnOff_On";
VAL_ 1376 VFCVectorXCUVFCid34 0 "VFCOnOff_Off" 1 "VFCOnOff_On";
VAL_ 1376 VFCVectorXCUVFCid35 0 "VFCOnOff_Off" 1 "VFCOnOff_On";
VAL_ 1376 VFCVectorXCUVFCid36 0 "VFCOnOff_Off" 1 "VFCOnOff_On";
VAL_ 1376 VFCVectorXCUVFCid37 0 "VFCOnOff_Off" 1 "VFCOnOff_On";
VAL_ 1376 VFCVectorXCUVFCid38 0 "VFCOnOff_Off" 1 "VFCOnOff_On";
VAL_ 1376 VFCVectorXCUVFCid39 0 "VFCOnOff_Off" 1 "VFCOnOff_On";
VAL_ 1376 VFCVectorXCUVFCid4 0 "VFCOnOff_Off" 1 "VFCOnOff_On";
VAL_ 1376 VFCVectorXCUVFCid40 0 "VFCOnOff_Off" 1 "VFCOnOff_On";
VAL_ 1376 VFCVectorXCUVFCid41 0 "VFCOnOff_Off" 1 "VFCOnOff_On";
VAL_ 1376 VFCVectorXCUVFCid42 0 "VFCOnOff_Off" 1 "VFCOnOff_On";
VAL_ 1376 VFCVectorXCUVFCid43 0 "VFCOnOff_Off" 1 "VFCOnOff_On";
VAL_ 1376 VFCVectorXCUVFCid44 0 "VFCOnOff_Off" 1 "VFCOnOff_On";
VAL_ 1376 VFCVectorXCUVFCid45 0 "VFCOnOff_Off" 1 "VFCOnOff_On";
VAL_ 1376 VFCVectorXCUVFCid46 0 "VFCOnOff_Off" 1 "VFCOnOff_On";
VAL_ 1376 VFCVectorXCUVFCid47 0 "VFCOnOff_Off" 1 "VFCOnOff_On";
VAL_ 1376 VFCVectorXCUVFCid48 0 "VFCOnOff_Off" 1 "VFCOnOff_On";
VAL_ 1376 VFCVectorXCUVFCid49 0 "VFCOnOff_Off" 1 "VFCOnOff_On";
VAL_ 1376 VFCVectorXCUVFCid5 0 "VFCOnOff_Off" 1 "VFCOnOff_On";
VAL_ 1376 VFCVectorXCUVFCid50 0 "VFCOnOff_Off" 1 "VFCOnOff_On";
VAL_ 1376 VFCVectorXCUVFCid51 0 "VFCOnOff_Off" 1 "VFCOnOff_On";
VAL_ 1376 VFCVectorXCUVFCid52 0 "VFCOnOff_Off" 1 "VFCOnOff_On";
VAL_ 1376 VFCVectorXCUVFCid53 0 "VFCOnOff_Off" 1 "VFCOnOff_On";
VAL_ 1376 VFCVectorXCUVFCid54 0 "VFCOnOff_Off" 1 "VFCOnOff_On";
VAL_ 1376 VFCVectorXCUVFCid55 0 "VFCOnOff_Off" 1 "VFCOnOff_On";
VAL_ 1376 VFCVectorXCUVFCid56 0 "VFCOnOff_Off" 1 "VFCOnOff_On";
VAL_ 1376 VFCVectorXCUVFCid57 0 "VFCOnOff_Off" 1 "VFCOnOff_On";
VAL_ 1376 VFCVectorXCUVFCid58 0 "VFCOnOff_Off" 1 "VFCOnOff_On";
VAL_ 1376 VFCVectorXCUVFCid59 0 "VFCOnOff_Off" 1 "VFCOnOff_On";
VAL_ 1376 VFCVectorXCUVFCid6 0 "VFCOnOff_Off" 1 "VFCOnOff_On";
VAL_ 1376 VFCVectorXCUVFCid60 0 "VFCOnOff_Off" 1 "VFCOnOff_On";
VAL_ 1376 VFCVectorXCUVFCid61 0 "VFCOnOff_Off" 1 "VFCOnOff_On";
VAL_ 1376 VFCVectorXCUVFCid7 0 "VFCOnOff_Off" 1 "VFCOnOff_On";
VAL_ 1376 VFCVectorXCUVFCid8 0 "VFCOnOff_Off" 1 "VFCOnOff_On";
VAL_ 1376 VFCVectorXCUVFCid9 0 "VFCOnOff_Off" 1 "VFCOnOff_On";
VAL_ 1349 VFCVectorZCUDMVFCid0 0 "VFCOnOff_Off" 1 "VFCOnOff_On";
VAL_ 1349 VFCVectorZCUDMVFCid1 0 "VFCOnOff_Off" 1 "VFCOnOff_On";
VAL_ 1349 VFCVectorZCUDMVFCid10 0 "VFCOnOff_Off" 1 "VFCOnOff_On";
VAL_ 1349 VFCVectorZCUDMVFCid11 0 "VFCOnOff_Off" 1 "VFCOnOff_On";
VAL_ 1349 VFCVectorZCUDMVFCid12 0 "VFCOnOff_Off" 1 "VFCOnOff_On";
VAL_ 1349 VFCVectorZCUDMVFCid13 0 "VFCOnOff_Off" 1 "VFCOnOff_On";
VAL_ 1349 VFCVectorZCUDMVFCid14 0 "VFCOnOff_Off" 1 "VFCOnOff_On";
VAL_ 1349 VFCVectorZCUDMVFCid15 0 "VFCOnOff_Off" 1 "VFCOnOff_On";
VAL_ 1349 VFCVectorZCUDMVFCid16 0 "VFCOnOff_Off" 1 "VFCOnOff_On";
VAL_ 1349 VFCVectorZCUDMVFCid17 0 "VFCOnOff_Off" 1 "VFCOnOff_On";
VAL_ 1349 VFCVectorZCUDMVFCid18 0 "VFCOnOff_Off" 1 "VFCOnOff_On";
VAL_ 1349 VFCVectorZCUDMVFCid19 0 "VFCOnOff_Off" 1 "VFCOnOff_On";
VAL_ 1349 VFCVectorZCUDMVFCid2 0 "VFCOnOff_Off" 1 "VFCOnOff_On";
VAL_ 1349 VFCVectorZCUDMVFCid20 0 "VFCOnOff_Off" 1 "VFCOnOff_On";
VAL_ 1349 VFCVectorZCUDMVFCid21 0 "VFCOnOff_Off" 1 "VFCOnOff_On";
VAL_ 1349 VFCVectorZCUDMVFCid22 0 "VFCOnOff_Off" 1 "VFCOnOff_On";
VAL_ 1349 VFCVectorZCUDMVFCid23 0 "VFCOnOff_Off" 1 "VFCOnOff_On";
VAL_ 1349 VFCVectorZCUDMVFCid24 0 "VFCOnOff_Off" 1 "VFCOnOff_On";
VAL_ 1349 VFCVectorZCUDMVFCid25 0 "VFCOnOff_Off" 1 "VFCOnOff_On";
VAL_ 1349 VFCVectorZCUDMVFCid26 0 "VFCOnOff_Off" 1 "VFCOnOff_On";
VAL_ 1349 VFCVectorZCUDMVFCid27 0 "VFCOnOff_Off" 1 "VFCOnOff_On";
VAL_ 1349 VFCVectorZCUDMVFCid28 0 "VFCOnOff_Off" 1 "VFCOnOff_On";
VAL_ 1349 VFCVectorZCUDMVFCid29 0 "VFCOnOff_Off" 1 "VFCOnOff_On";
VAL_ 1349 VFCVectorZCUDMVFCid3 0 "VFCOnOff_Off" 1 "VFCOnOff_On";
VAL_ 1349 VFCVectorZCUDMVFCid30 0 "VFCOnOff_Off" 1 "VFCOnOff_On";
VAL_ 1349 VFCVectorZCUDMVFCid31 0 "VFCOnOff_Off" 1 "VFCOnOff_On";
VAL_ 1349 VFCVectorZCUDMVFCid32 0 "VFCOnOff_Off" 1 "VFCOnOff_On";
VAL_ 1349 VFCVectorZCUDMVFCid33 0 "VFCOnOff_Off" 1 "VFCOnOff_On";
VAL_ 1349 VFCVectorZCUDMVFCid34 0 "VFCOnOff_Off" 1 "VFCOnOff_On";
VAL_ 1349 VFCVectorZCUDMVFCid35 0 "VFCOnOff_Off" 1 "VFCOnOff_On";
VAL_ 1349 VFCVectorZCUDMVFCid36 0 "VFCOnOff_Off" 1 "VFCOnOff_On";
VAL_ 1349 VFCVectorZCUDMVFCid37 0 "VFCOnOff_Off" 1 "VFCOnOff_On";
VAL_ 1349 VFCVectorZCUDMVFCid38 0 "VFCOnOff_Off" 1 "VFCOnOff_On";
VAL_ 1349 VFCVectorZCUDMVFCid39 0 "VFCOnOff_Off" 1 "VFCOnOff_On";
VAL_ 1349 VFCVectorZCUDMVFCid4 0 "VFCOnOff_Off" 1 "VFCOnOff_On";
VAL_ 1349 VFCVectorZCUDMVFCid40 0 "VFCOnOff_Off" 1 "VFCOnOff_On";
VAL_ 1349 VFCVectorZCUDMVFCid41 0 "VFCOnOff_Off" 1 "VFCOnOff_On";
VAL_ 1349 VFCVectorZCUDMVFCid42 0 "VFCOnOff_Off" 1 "VFCOnOff_On";
VAL_ 1349 VFCVectorZCUDMVFCid43 0 "VFCOnOff_Off" 1 "VFCOnOff_On";
VAL_ 1349 VFCVectorZCUDMVFCid44 0 "VFCOnOff_Off" 1 "VFCOnOff_On";
VAL_ 1349 VFCVectorZCUDMVFCid45 0 "VFCOnOff_Off" 1 "VFCOnOff_On";
VAL_ 1349 VFCVectorZCUDMVFCid46 0 "VFCOnOff_Off" 1 "VFCOnOff_On";
VAL_ 1349 VFCVectorZCUDMVFCid47 0 "VFCOnOff_Off" 1 "VFCOnOff_On";
VAL_ 1349 VFCVectorZCUDMVFCid48 0 "VFCOnOff_Off" 1 "VFCOnOff_On";
VAL_ 1349 VFCVectorZCUDMVFCid49 0 "VFCOnOff_Off" 1 "VFCOnOff_On";
VAL_ 1349 VFCVectorZCUDMVFCid5 0 "VFCOnOff_Off" 1 "VFCOnOff_On";
VAL_ 1349 VFCVectorZCUDMVFCid50 0 "VFCOnOff_Off" 1 "VFCOnOff_On";
VAL_ 1349 VFCVectorZCUDMVFCid51 0 "VFCOnOff_Off" 1 "VFCOnOff_On";
VAL_ 1349 VFCVectorZCUDMVFCid52 0 "VFCOnOff_Off" 1 "VFCOnOff_On";
VAL_ 1349 VFCVectorZCUDMVFCid53 0 "VFCOnOff_Off" 1 "VFCOnOff_On";
VAL_ 1349 VFCVectorZCUDMVFCid54 0 "VFCOnOff_Off" 1 "VFCOnOff_On";
VAL_ 1349 VFCVectorZCUDMVFCid55 0 "VFCOnOff_Off" 1 "VFCOnOff_On";
VAL_ 1349 VFCVectorZCUDMVFCid56 0 "VFCOnOff_Off" 1 "VFCOnOff_On";
VAL_ 1349 VFCVectorZCUDMVFCid57 0 "VFCOnOff_Off" 1 "VFCOnOff_On";
VAL_ 1349 VFCVectorZCUDMVFCid58 0 "VFCOnOff_Off" 1 "VFCOnOff_On";
VAL_ 1349 VFCVectorZCUDMVFCid59 0 "VFCOnOff_Off" 1 "VFCOnOff_On";
VAL_ 1349 VFCVectorZCUDMVFCid6 0 "VFCOnOff_Off" 1 "VFCOnOff_On";
VAL_ 1349 VFCVectorZCUDMVFCid60 0 "VFCOnOff_Off" 1 "VFCOnOff_On";
VAL_ 1349 VFCVectorZCUDMVFCid61 0 "VFCOnOff_Off" 1 "VFCOnOff_On";
VAL_ 1349 VFCVectorZCUDMVFCid7 0 "VFCOnOff_Off" 1 "VFCOnOff_On";
VAL_ 1349 VFCVectorZCUDMVFCid8 0 "VFCOnOff_Off" 1 "VFCOnOff_On";
VAL_ 1349 VFCVectorZCUDMVFCid9 0 "VFCOnOff_Off" 1 "VFCOnOff_On";
VAL_ 1285 WakeUpReasonsforZCUDM 0 "WakeupReasons_667949" 1 "WakeupReasons_667950" 2 "WakeupReasons_169654" 3 "WakeupReasons_667951" 4 "WakeupReasons_168965" 5 "WakeupReasons_197643" 6 "WakeupReasons_264933" 7 "WakeupReasons_45654" 8 "WakeupReasons_22058" 9 "WakeupReasons_49446" 10 "WakeupReasons_22060" 11 "WakeupReasons_269740" 12 "WakeupReasons_269735" 13 "WakeupReasons_269739" 14 "WakeupReasons_658500" 15 "WakeupReasons_21901" 16 "WakeupReasons_45793" 17 "WakeupReasons_45794" 18 "WakeupReasons_22005" 19 "WakeupReasons_22013" 20 "WakeupReasons_22100" 21 "WakeupReasons_45659" 22 "WakeupReasons_45657" 23 "WakeupReasons_140084" 24 "WakeupReasons_21973" 25 "WakeupReasons_91253" 26 "WakeupReasons_88123" 27 "WakeupReasons_88125" 28 "WakeupReasons_321583" 29 "WakeupReasons_74188" 30 "WakeupReasons_667945" 31 "WakeupReasons_169655" 32 "WakeupReasons_667948" 33 "WakeupReasons_168966" 34 "WakeupReasons_170865" 35 "WakeupReasons_197642" 36 "WakeupReasons_264876" 37 "WakeupReasons_191050" 38 "WakeupReasons_182033" 39 "WakeupReasons_200937" 40 "WakeupReasons_170807" 41 "WakeupReasons_319139" 42 "WakeupReasons_100298" 43 "WakeupReasons_100275" 44 "WakeupReasons_100300" 45 "WakeupReasons_100278" 46 "WakeupReasons_100281" 47 "WakeupReasons_265333" 48 "WakeupReasons_108776" 49 "WakeupReasons_176921" 50 "WakeupReasons_197826" 51 "WakeupReasons_185670" 52 "WakeupReasons_161066" 53 "WakeupReasons_200156" 54 "WakeupReasons_225696" 55 "WakeupReasons_21997" 56 "WakeupReasons_45656" 57 "WakeupReasons_266860" 58 "WakeupReasons_169894" 59 "WakeupReasons_320282" 60 "WakeupReasons_319422" 61 "WakeupReasons_320277" 62 "WakeupReasons_355601" 63 "WakeupReasons_360904" 64 "WakeupReasons_361505" 65 "WakeupReasons_361509" 66 "WakeupReasons_645094" 67 "WakeupReasons_68676" 68 "WakeupReasons_360008" 69 "WakeupReasons_109382" 70 "WakeupReasons_119273" 71 "WakeupReasons_224065" 72 "WakeupReasons_68644" 73 "WakeupReasons_109364" 74 "WakeupReasons_68481" 75 "WakeupReasons_224061" 76 "WakeupReasons_360006" 77 "WakeupReasons_138997" 78 "WakeupReasons_634696" 79 "WakeupReasons_645810" 80 "WakeupReasons_297868" 81 "WakeupReasons_315364" 82 "WakeupReasons_109367" 83 "WakeupReasons_320126" 84 "WakeupReasons_109387" 85 "WakeupReasons_634710" 86 "WakeupReasons_338820" 87 "WakeupReasons_67182" 88 "WakeupReasons_152237" 89 "WakeupReasons_145707" 90 "WakeupReasons_199172" 91 "WakeupReasons_144897" 92 "WakeupReasons_186489" 93 "WakeupReasons_144970" 94 "WakeupReasons_152786" 95 "WakeupReasons_264932" 96 "WakeupReasons_264934" 97 "WakeupReasons_356190" 98 "WakeupReasons_145688" 99 "WakeupReasons_95444" 100 "WakeupReasons_169945" 101 "WakeupReasons_140678" 102 "WakeupReasons_222553" 103 "WakeupReasons_224831" 104 "WakeupReasons_201815" 105 "WakeupReasons_45864" 106 "WakeupReasons_659549" 107 "WakeupReasons_45866" 108 "WakeupReasons_45867" 109 "WakeupReasons_169884" 110 "WakeupReasons_264962" 111 "WakeupReasons_201348" 112 "WakeupReasons_320287" 113 "WakeupReasons_156412" 114 "WakeupReasons_133749" 115 "WakeupReasons_355409" 116 "WakeupReasons_636692" 117 "WakeupReasons_533044" 118 "WakeupReasons_106774" 119 "WakeupReasons_145311" 120 "WakeupReasons_145319" 121 "WakeupReasons_152774" 122 "WakeupReasons_145330" 123 "WakeupReasons_145388" 124 "WakeupReasons_145399" 125 "WakeupReasons_145362" 126 "WakeupReasons_145385" 127 "WakeupReasons_145373" 128 "WakeupReasons_145288" 129 "WakeupReasons_145419" 130 "WakeupReasons_145454" 131 "WakeupReasons_145462" 132 "WakeupReasons_269156" 133 "WakeupReasons_300427" 134 "WakeupReasons_220322" 135 "WakeupReasons_224617" 136 "WakeupReasons_224634" 137 "WakeupReasons_300682" 138 "WakeupReasons_264958" 139 "WakeupReasons_160597" 140 "WakeupReasons_160602" 141 "WakeupReasons_108841" 142 "WakeupReasons_265569" 143 "WakeupReasons_526429" 144 "WakeupReasons_514545" 145 "WakeupReasons_265232" 146 "WakeupReasons_644550" 147 "WakeupReasons_317616" 148 "WakeupReasons_354791" 149 "WakeupReasons_320631" 150 "WakeupReasons_337565" 151 "WakeupReasons_532007" 152 "WakeupReasons_514503" 153 "WakeupReasons_299117" 154 "WakeupReasons_340667" 155 "WakeupReasons_321845" 156 "WakeupReasons_179103" 157 "WakeupReasons_108810" 158 "WakeupReasons_322857" 159 "WakeupReasons_658603" 160 "WakeupReasons_197648" 161 "WakeupReasons_160596" 162 "WakeupReasons_361272" 163 "WakeupReasons_361279" 164 "WakeupReasons_265305" 165 "WakeupReasons_265328" 166 "WakeupReasons_265330" 167 "WakeupReasons_298808" 168 "WakeupReasons_515804" 169 "WakeupReasons_514502" 170 "WakeupReasons_645753" 171 "WakeupReasons_646109" 172 "WakeupReasons_299547" 173 "WakeupReasons_318342" 174 "WakeupReasons_360543" 175 "WakeupReasons_356549" 176 "WakeupReasons_198484" 177 "WakeupReasons_300681" 178 "WakeupReasons_359211" 179 "WakeupReasons_534077" 180 "WakeupReasons_525705" 181 "WakeupReasons_360299" 182 "WakeupReasons_526445" 183 "WakeupReasons_534145" 184 "WakeupReasons_192030" 185 "WakeupReasons_652361" 186 "WakeupReasons_355214" 187 "WakeupReasons_321317" 188 "WakeupReasons_359187" 189 "WakeupReasons_321057" 190 "WakeupReasons_321319" 191 "WakeupReasons_321323" 192 "WakeupReasons_321077" 193 "WakeupReasons_320895" 194 "WakeupReasons_655340" 195 "WakeupReasons_636556" 196 "WakeupReasons_108834" 197 "WakeupReasons_265937" 198 "WakeupReasons_533050" 199 "WakeupReasons_526426" 200 "WakeupReasons_264712" 201 "WakeupReasons_319401" 202 "WakeupReasons_643973" 203 "WakeupReasons_223715" 204 "WakeupReasons_199159" 205 "WakeupReasons_318382" 206 "WakeupReasons_226967" 207 "WakeupReasons_531743" 208 "WakeupReasons_360542" 209 "WakeupReasons_264726" 210 "WakeupReasons_535214" 211 "WakeupReasons_335068" 212 "WakeupReasons_316796" 213 "WakeupReasons_526438" 214 "WakeupReasons_198433" 215 "WakeupReasons_225961" 216 "WakeupReasons_197665" 217 "WakeupReasons_224550" 218 "WakeupReasons_667962" 219 "WakeupReasons_667953" 220 "WakeupReasons_110885" 221 "WakeupReasons_224552" 222 "WakeupReasons_224553" 223 "WakeupReasons_652546" 224 "WakeupReasons_331194" 225 "WakeupReasons_667820" 226 "WakeupReasons_659350" 227 "WakeupReasons_101706" 228 "WakeupReasons_101725" 229 "WakeupReasons_101728" 230 "WakeupReasons_101727" 231 "WakeupReasons_166267" 232 "WakeupReasons_156440" 233 "WakeupReasons_95949" 234 "WakeupReasons_112799" 235 "WakeupReasons_146470" 236 "WakeupReasons_176748" 237 "WakeupReasons_223920" 238 "WakeupReasons_668531" 239 "WakeupReasons_670087" 240 "WakeupReasons_668529" 241 "WakeupReasons_45858" 242 "WakeupReasons_315981" 243 "WakeupReasons_533370" 244 "WakeupReasons_533371" 245 "WakeupReasons_533372" 246 "WakeupReasons_241902" 247 "WakeupReasons_359559" 248 "WakeupReasons_516327" 249 "WakeupReasons_533872" 250 "WakeupReasons_45856" 251 "WakeupReasons_45853" 252 "WakeupReasons_45854" 253 "WakeupReasons_45852" 254 "WakeupReasons_45851" 255 "WakeupReasons_45850" 256 "WakeupReasons_45849" 257 "WakeupReasons_636801" 258 "WakeupReasons_109466" 259 "WakeupReasons_109467" 260 "WakeupReasons_670345" 261 "WakeupReasons_NMPDUReceived" 262 "WakeupReasons_358832" 263 "WakeupReasons_200683" 264 "WakeupReasons_198452" 265 "WakeupReasons_185457" 266 "WakeupReasons_185490" 267 "WakeupReasons_4471" 268 "WakeupReasons_269034" 269 "WakeupReasons_215560" 270 "WakeupReasons_312881" 271 "WakeupReasons_269140" 272 "WakeupReasons_197653" 273 "WakeupReasons_337991" 274 "WakeupReasons_658188" 275 "WakeupReasons_674953" 276 "WakeupReasons_675064" 277 "WakeupReasons_674958" 278 "WakeupReasons_675494" 279 "WakeupReasons_675837" 280 "WakeupReasons_667879" 281 "WakeupReasons_667947" 282 "WakeupReasons_676265" 283 "WakeupReasons_669465" 284 "WakeupReasons_670928" 285 "WakeupReasons_669447" 286 "WakeupReasons_667922" 287 "WakeupReasons_670753" 288 "WakeupReasons_668395" 289 "WakeupReasons_668393" 290 "WakeupReasons_667850" 291 "WakeupReasons_667848" 292 "WakeupReasons_311279" 293 "WakeupReasons_182918" 294 "WakeupReasons_667988" 295 "WakeupReasons_532555" 296 "WakeupReasons_532556" 297 "WakeupReasons_113348" 298 "WakeupReasons_193474" 299 "WakeupReasons_667871" 300 "WakeupReasons_670966" 301 "WakeupReasons_667985" 302 "WakeupReasons_670354" 303 "WakeupReasons_46017" 304 "WakeupReasons_675742" 305 "WakeupReasons_106669" 306 "WakeupReasons_80609" 307 "WakeupReasons_199714" 308 "WakeupReasons_200090" 309 "WakeupReasons_139075" 310 "WakeupReasons_268983" 311 "WakeupReasons_265131" 312 "WakeupReasons_263473" 313 "WakeupReasons_45887" 314 "WakeupReasons_69678" 315 "WakeupReasons_69679" 316 "WakeupReasons_45897" 317 "WakeupReasons_45898" 318 "WakeupReasons_80608" 319 "WakeupReasons_45869" 320 "WakeupReasons_45870" 321 "WakeupReasons_45872" 322 "WakeupReasons_45875" 323 "WakeupReasons_45871" 324 "WakeupReasons_45876" 325 "WakeupReasons_667980" 326 "WakeupReasons_45877" 327 "WakeupReasons_667973" 328 "WakeupReasons_670962" 329 "WakeupReasons_45888" 330 "WakeupReasons_45890" 331 "WakeupReasons_667869" 332 "WakeupReasons_45846" 333 "WakeupReasons_45847" 334 "WakeupReasons_45848" 335 "WakeupReasons_262872" 336 "WakeupReasons_127924" 337 "WakeupReasons_127926" 338 "WakeupReasons_674223" 339 "WakeupReasons_667982" 340 "WakeupReasons_657121" 341 "WakeupReasons_265745" 342 "WakeupReasons_657120" 343 "WakeupReasons_675564" 344 "WakeupReasons_197644" 345 "WakeupReasons_264943" 346 "WakeupReasons_264697" 347 "WakeupReasons_69216" 348 "WakeupReasons_128671" 349 "WakeupReasons_356598" 350 "WakeupReasons_675745" 351 "WakeupReasons_667983" 352 "WakeupReasons_667987" 353 "WakeupReasons_75103" 354 "WakeupReasons_305818" 355 "WakeupReasons_670942" 356 "WakeupReasons_532932" 357 "WakeupReasons_532933" 358 "WakeupReasons_83199" 359 "WakeupReasons_45900" 360 "WakeupReasons_88458" 361 "WakeupReasons_329457" 362 "WakeupReasons_45902" 363 "WakeupReasons_224211" 364 "WakeupReasons_667981" 365 "WakeupReasons_667874" 366 "WakeupReasons_46020" 367 "WakeupReasons_667842" 368 "WakeupReasons_145161" 369 "WakeupReasons_233755" 370 "WakeupReasons_297056" 371 "WakeupReasons_264691" 372 "WakeupReasons_262871" 373 "WakeupReasons_264964" 374 "WakeupReasons_667872" 375 "WakeupReasons_45655" 376 "WakeupReasons_177214" 377 "WakeupReasons_671005" 378 "WakeupReasons_680712" 379 "WakeupReasons_669822" 380 "WakeupReasons_668523" 381 "WakeupReasons_680974" 382 "WakeupReasons_680975" 383 "WakeupReasons_681028" 384 "WakeupReasons_670462" 385 "WakeupReasons_681134" 386 "WakeupReasons_681031" 387 "WakeupReasons_681711" 388 "WakeupReasons_682034" 389 "WakeupReasons_674839" 390 "WakeupReasons_681915" 391 "WakeupReasons_682032" 392 "WakeupReasons_682037" 393 "WakeupReasons_682688" 394 "WakeupReasons_681789" 395 "WakeupReasons_682023" 396 "WakeupReasons_681023" 397 "WakeupReasons_676285" 398 "WakeupReasons_682077" 399 "WakeupReasons_682076" 400 "WakeupReasons_682078" 401 "WakeupReasons_682153" 402 "WakeupReasons_682155" 403 "WakeupReasons_682152" 404 "WakeupReasons_682154" 405 "WakeupReasons_682074";
SIG_GROUP_ 278 AccrPedlPsd 1 : AccrPedlPsdAccrPedlPsd AccrPedlPsdChks AccrPedlPsdCntr AccrPedlPsdSts;
SIG_GROUP_ 129 ADataRawSafe 1 : ADataRawSafeALat ADataRawSafeALat1Qf ADataRawSafeALgt ADataRawSafeALgt1Qf ADataRawSafeAVert ADataRawSafeAVertQf ADataRawSafeChks ADataRawSafeCntr;
SIG_GROUP_ 1051 AmbTEstimd 1 : AmbTEstimdAmbTEstimd AmbTEstimdQf;
SIG_GROUP_ 645 AmbTRaw 1 : AmbTRawAmbTVal AmbTRawQly;
SIG_GROUP_ 569 BexvPosnReq 1 : BexvPosnReqExvCalibReq BexvPosnReqExvHeatdReq BexvPosnReqExvMovEnable BexvPosnReqExvPosnReq;
SIG_GROUP_ 672 BexvStsFromTMCU 1 : BexvStsFromTMCUExvActrPosn BexvStsFromTMCUExvBlkErr BexvStsFromTMCUExvCalibSts BexvStsFromTMCUExvElecStsErr BexvStsFromTMCUExvMovSts BexvStsFromTMCUExvOvrTempErr BexvStsFromTMCUExvOvrTrvlErr BexvStsFromTMCUExvPreHeatgSts BexvStsFromTMCUExvVoltgRangErr;
SIG_GROUP_ 118 BrkPedlPsd 1 : BrkPedlPsdBrkPedlNotPsdSafe BrkPedlPsdBrkPedlPsd BrkPedlPsdChks BrkPedlPsdCntr BrkPedlPsdQf;
SIG_GROUP_ 633 CcvmCmd 1 : CcvmCmdVlvActvSaveReq CcvmCmdVlvCalibReq CcvmCmdVlvHeatdReq CcvmCmdVlvMovEna CcvmCmdVlvPosn CcvmCmdVlvSpdLvlReq;
SIG_GROUP_ 869 CcvmStsFromTMCU 1 : CcvmStsFromTMCUVlvBlkFlt CcvmStsFromTMCUVlvCalibSts CcvmStsFromTMCUVlvCmdPosnErr CcvmStsFromTMCUVlvLoTErr CcvmStsFromTMCUVlvMoveSts CcvmStsFromTMCUVlvNVMFlt CcvmStsFromTMCUVlvOpenCircFlt CcvmStsFromTMCUVlvOverTErr CcvmStsFromTMCUVlvOverTrvlFlt CcvmStsFromTMCUVlvOverTWarn CcvmStsFromTMCUVlvOverUErr CcvmStsFromTMCUVlvPosn CcvmStsFromTMCUVlvPosnCtrlTimeOutFlt CcvmStsFromTMCUVlvPosnUkwnFlt CcvmStsFromTMCUVlvPreHeatgSts CcvmStsFromTMCUVlvSelfLearnFlt CcvmStsFromTMCUVlvShoCircFlt CcvmStsFromTMCUVlvSpdLvlSts CcvmStsFromTMCUVlvUnderUErr;
SIG_GROUP_ 633 CcvPosReq 1 : CcvPosReqDftPos CcvPosReqPosReq CcvPosReqReqEnad CcvPosReqRstPos CcvPosReqTrqReq;
SIG_GROUP_ 880 CcvVlvStsFromTMCU 1 : CcvVlvStsFromTMCUARC CcvVlvStsFromTMCUIntFlt CcvVlvStsFromTMCUOprFlt CcvVlvStsFromTMCUTrqSts;
SIG_GROUP_ 53 CrashStsSafe 1 : CrashStsSafeChks CrashStsSafeCntr CrashStsSafeSts;
SIG_GROUP_ 310 DrvrGearShiftDirReq1 1 : DrvrGearShiftDirReq1Chks DrvrGearShiftDirReq1Cntr DrvrGearShiftDirReq1DwnDwnTipAut DrvrGearShiftDirReq1DwnTipAut DrvrGearShiftDirReq1PosnAut DrvrGearShiftDirReq1UpTipAut DrvrGearShiftDirReq1UpUpTipAut;
SIG_GROUP_ 310 DrvrGearShiftDirReq2 1 : DrvrGearShiftDirReq2Chks DrvrGearShiftDirReq2Cntr DrvrGearShiftDirReq2DwnDwnTipAut DrvrGearShiftDirReq2DwnTipAut DrvrGearShiftDirReq2PosnAut DrvrGearShiftDirReq2UpTipAut DrvrGearShiftDirReq2UpUpTipAut;
SIG_GROUP_ 309 DrvrGearShiftManReq 1 : DrvrGearShiftManReqDwnDwnTipReq DrvrGearShiftManReqDwnTipReq DrvrGearShiftManReqSteerWhlDwnReq1 DrvrGearShiftManReqSteerWhlUpReq DrvrGearShiftManReqTipReq1 DrvrGearShiftManReqUpTipReq1 DrvrGearShiftManReqUpUpTipReq;
SIG_GROUP_ 309 DrvrGearShiftParkReq 1 : DrvrGearShiftParkReq1 DrvrGearShiftParkReqChks DrvrGearShiftParkReqCntr DrvrGearShiftParkReqSts;
SIG_GROUP_ 563 Edcp2PmpCmd 1 : Edcp2PmpCmdCooltPmpPostRunReq Edcp2PmpCmdCooltPmpSpdReq;
SIG_GROUP_ 684 Edcp2PmpStsFromTMCU 1 : Edcp2PmpStsFromTMCUCooltPmpDryErr Edcp2PmpStsFromTMCUCooltPmpEmgyModSts Edcp2PmpStsFromTMCUCooltPmpErrSts Edcp2PmpStsFromTMCUCooltPmpI Edcp2PmpStsFromTMCUCooltPmpIErr Edcp2PmpStsFromTMCUCooltPmpMonrSpd Edcp2PmpStsFromTMCUCooltPmpPostRunSts Edcp2PmpStsFromTMCUCooltPmpSetPostRunReq Edcp2PmpStsFromTMCUCooltPmpSetSpdReq Edcp2PmpStsFromTMCUCooltPmpSpd Edcp2PmpStsFromTMCUCooltPmpT Edcp2PmpStsFromTMCUCooltPmpTErr Edcp2PmpStsFromTMCUCooltPmpU Edcp2PmpStsFromTMCUCooltPmpUErr Edcp2PmpStsFromTMCUCooltPmpUnstallSts;
SIG_GROUP_ 563 EexvPosnReq 1 : EexvPosnReqExvCalibReq EexvPosnReqExvHeatdReq EexvPosnReqExvMovEnable EexvPosnReqExvPosnReq;
SIG_GROUP_ 672 EexvStsFromTMCU 1 : EexvStsFromTMCUExvActrPosn EexvStsFromTMCUExvBlkErr EexvStsFromTMCUExvCalibSts EexvStsFromTMCUExvElecStsErr EexvStsFromTMCUExvMovSts EexvStsFromTMCUExvOvrTempErr EexvStsFromTMCUExvOvrTrvlErr EexvStsFromTMCUExvPreHeatgSts EexvStsFromTMCUExvVoltgRangErr;
SIG_GROUP_ 75 EngSt1WdSts 1 : EngSt1WdStsChks EngSt1WdStsCntr EngSt1WdStsEngSt1WdSts;
SIG_GROUP_ 302 EscVariantToDmc 1 : EscVariantToDmcChks EscVariantToDmcCntr EscVariantToDmcEscVariantToDmc;
SIG_GROUP_ 563 ExvPosnReq 1 : ExvPosnReqExvCalibReq ExvPosnReqExvHeatdReq ExvPosnReqExvMovEnable ExvPosnReqExvPosnReq;
SIG_GROUP_ 675 ExvStsFromTMCU 1 : ExvStsFromTMCUExvActrPosn ExvStsFromTMCUExvBlkErr ExvStsFromTMCUExvCalibSts ExvStsFromTMCUExvElecStsErr ExvStsFromTMCUExvMovSts ExvStsFromTMCUExvOvrTempErr ExvStsFromTMCUExvOvrTrvlErr ExvStsFromTMCUExvPreHeatgSts ExvStsFromTMCUExvVoltgRangErr;
SIG_GROUP_ 633 HctvCmd 1 : HctvCmdVlvActvSaveReq HctvCmdVlvCalibReq HctvCmdVlvHeatdReq HctvCmdVlvMovEna HctvCmdVlvPosn HctvCmdVlvSpdLvlReq;
SIG_GROUP_ 675 HctvStsFromTMCU 1 : HctvStsFromTMCUVlvBlkFlt HctvStsFromTMCUVlvCalibSts HctvStsFromTMCUVlvCmdPosnErr HctvStsFromTMCUVlvLoTErr HctvStsFromTMCUVlvMoveSts HctvStsFromTMCUVlvNVMFlt HctvStsFromTMCUVlvOpenCircFlt HctvStsFromTMCUVlvOverTErr HctvStsFromTMCUVlvOverTrvlFlt HctvStsFromTMCUVlvOverTWarn HctvStsFromTMCUVlvOverUErr HctvStsFromTMCUVlvPosn HctvStsFromTMCUVlvPosnCtrlTimeOutFlt HctvStsFromTMCUVlvPosnUkwnFlt HctvStsFromTMCUVlvPreHeatgSts HctvStsFromTMCUVlvSelfLearnFlt HctvStsFromTMCUVlvShoCircFlt HctvStsFromTMCUVlvSpdLvlSts HctvStsFromTMCUVlvUnderUErr;
SIG_GROUP_ 563 HeatrPmpCmd 1 : HeatrPmpCmdCooltPmpPostRunReq HeatrPmpCmdCooltPmpSpdReq;
SIG_GROUP_ 678 HeatrPmpStatFromTMCU 1 : HeatrPmpStatFromTMCUCooltPmpDryErr HeatrPmpStatFromTMCUCooltPmpEmgyModSts HeatrPmpStatFromTMCUCooltPmpErrSts HeatrPmpStatFromTMCUCooltPmpI HeatrPmpStatFromTMCUCooltPmpIErr HeatrPmpStatFromTMCUCooltPmpMonrSpd HeatrPmpStatFromTMCUCooltPmpPostRunSts HeatrPmpStatFromTMCUCooltPmpSetPostRunReq HeatrPmpStatFromTMCUCooltPmpSetSpdReq HeatrPmpStatFromTMCUCooltPmpSpd HeatrPmpStatFromTMCUCooltPmpT HeatrPmpStatFromTMCUCooltPmpTErr HeatrPmpStatFromTMCUCooltPmpU HeatrPmpStatFromTMCUCooltPmpUErr HeatrPmpStatFromTMCUCooltPmpUnstallSts;
SIG_GROUP_ 563 HvBattPmpCmd 1 : HvBattPmpCmdCooltPmpPostRunReq HvBattPmpCmdCooltPmpSpdReq;
SIG_GROUP_ 681 HvBattPmpStatFromTMCU 1 : HvBattPmpStatFromTMCUCooltPmpDryErr HvBattPmpStatFromTMCUCooltPmpEmgyModSts HvBattPmpStatFromTMCUCooltPmpErrSts HvBattPmpStatFromTMCUCooltPmpI HvBattPmpStatFromTMCUCooltPmpIErr HvBattPmpStatFromTMCUCooltPmpMonrSpd HvBattPmpStatFromTMCUCooltPmpPostRunSts HvBattPmpStatFromTMCUCooltPmpSetPostRunReq HvBattPmpStatFromTMCUCooltPmpSetSpdReq HvBattPmpStatFromTMCUCooltPmpSpd HvBattPmpStatFromTMCUCooltPmpT HvBattPmpStatFromTMCUCooltPmpTErr HvBattPmpStatFromTMCUCooltPmpU HvBattPmpStatFromTMCUCooltPmpUErr HvBattPmpStatFromTMCUCooltPmpUnstallSts;
SIG_GROUP_ 597 ImobEngMgrReq2 1 : ImobEngMgrReq2ImobEngDataMgrReq0 ImobEngMgrReq2ImobEngDataMgrReq1 ImobEngMgrReq2ImobEngDataMgrReq2 ImobEngMgrReq2ImobEngDataMgrReq3 ImobEngMgrReq2ImobEngDataMgrReq4 ImobEngMgrReq2ImobEngDataMgrReq5 ImobEngMgrReq2ImobEngDataMgrReq6 ImobEngMgrReq2ImobEngMgrCmdTar1;
SIG_GROUP_ 313 LockgCenSts 1 : LockgCenStsLockSt LockgCenStsTrigSrc LockgCenStsUpdEve;
SIG_GROUP_ 65 PtTqAtAxleMaxReq 1 : PtTqAtAxleMaxReqChks PtTqAtAxleMaxReqCntr PtTqAtAxleMaxReqPtTqAtAxleFrntReq PtTqAtAxleMaxReqPtTqAtAxleReReq;
SIG_GROUP_ 282 StcStsToDmc 1 : StcStsToDmcChks StcStsToDmcCntr StcStsToDmcEngRotTarSpdDMCFrnt StcStsToDmcEngRotTarSpdDMCRear StcStsToDmcFrnt StcStsToDmcRear;
SIG_GROUP_ 337 TiAndDateIndcn 1 : TiAndDateIndcnDataValid TiAndDateIndcnDay TiAndDateIndcnHr1 TiAndDateIndcnMins1 TiAndDateIndcnMth1 TiAndDateIndcnSec1 TiAndDateIndcnYr1;
SIG_GROUP_ 819 UTCTiFromEth 1 : UTCTiFromEthDataValid UTCTiFromEthDay UTCTiFromEthHr1 UTCTiFromEthMins1 UTCTiFromEthMth1 UTCTiFromEthSec1 UTCTiFromEthYr1;
SIG_GROUP_ 645 VehBattU 1 : VehBattUSysU VehBattUSysUQf;
SIG_GROUP_ 565 VehCfgPrm 1 : VehCfgPrmBlkIDBytePosn1 VehCfgPrmCCPBytePosn2 VehCfgPrmCCPBytePosn3 VehCfgPrmCCPBytePosn4 VehCfgPrmCCPBytePosn5 VehCfgPrmCCPBytePosn6 VehCfgPrmCCPBytePosn7 VehCfgPrmCCPBytePosn8;
SIG_GROUP_ 566 VehCfgPrmExt 1 : VehCfgPrmExtBlkIDBytePosn1 VehCfgPrmExtCCPBytePosn2 VehCfgPrmExtCCPBytePosn3 VehCfgPrmExtCCPBytePosn4 VehCfgPrmExtCCPBytePosn5 VehCfgPrmExtCCPBytePosn6 VehCfgPrmExtCCPBytePosn7 VehCfgPrmExtCCPBytePosn8;
SIG_GROUP_ 86 VehModMngtGlbSafe1 1 : VehModMngtGlbSafe1CarModSts1 VehModMngtGlbSafe1CarModSubtypWdCarModSubtyp VehModMngtGlbSafe1Chks VehModMngtGlbSafe1Cntr VehModMngtGlbSafe1EgyLvlElecMai VehModMngtGlbSafe1EgyLvlElecSubtyp VehModMngtGlbSafe1FltEgyCnsWdSts VehModMngtGlbSafe1PwrLvlElecMai VehModMngtGlbSafe1PwrLvlElecSubtyp VehModMngtGlbSafe1UsgModSts;
SIG_GROUP_ 118 VehMtnSt 1 : VehMtnStChks VehMtnStCntr VehMtnStVehMtnSt;
SIG_GROUP_ 118 VehSpdLgt 1 : VehSpdLgtA VehSpdLgtChks VehSpdLgtCntr VehSpdLgtQf;
SIG_GROUP_ 1366 VFCVectorEGSM 1 : VFCVectorEGSMBlockID VFCVectorEGSMVFCid0 VFCVectorEGSMVFCid1 VFCVectorEGSMVFCid10 VFCVectorEGSMVFCid11 VFCVectorEGSMVFCid12 VFCVectorEGSMVFCid13 VFCVectorEGSMVFCid14 VFCVectorEGSMVFCid15 VFCVectorEGSMVFCid16 VFCVectorEGSMVFCid17 VFCVectorEGSMVFCid18 VFCVectorEGSMVFCid19 VFCVectorEGSMVFCid2 VFCVectorEGSMVFCid20 VFCVectorEGSMVFCid21 VFCVectorEGSMVFCid22 VFCVectorEGSMVFCid23 VFCVectorEGSMVFCid24 VFCVectorEGSMVFCid25 VFCVectorEGSMVFCid26 VFCVectorEGSMVFCid27 VFCVectorEGSMVFCid28 VFCVectorEGSMVFCid29 VFCVectorEGSMVFCid3 VFCVectorEGSMVFCid30 VFCVectorEGSMVFCid31 VFCVectorEGSMVFCid32 VFCVectorEGSMVFCid33 VFCVectorEGSMVFCid34 VFCVectorEGSMVFCid35 VFCVectorEGSMVFCid36 VFCVectorEGSMVFCid37 VFCVectorEGSMVFCid38 VFCVectorEGSMVFCid39 VFCVectorEGSMVFCid4 VFCVectorEGSMVFCid40 VFCVectorEGSMVFCid41 VFCVectorEGSMVFCid42 VFCVectorEGSMVFCid43 VFCVectorEGSMVFCid44 VFCVectorEGSMVFCid45 VFCVectorEGSMVFCid46 VFCVectorEGSMVFCid47 VFCVectorEGSMVFCid48 VFCVectorEGSMVFCid49 VFCVectorEGSMVFCid5 VFCVectorEGSMVFCid50 VFCVectorEGSMVFCid51 VFCVectorEGSMVFCid52 VFCVectorEGSMVFCid53 VFCVectorEGSMVFCid54 VFCVectorEGSMVFCid55 VFCVectorEGSMVFCid56 VFCVectorEGSMVFCid57 VFCVectorEGSMVFCid58 VFCVectorEGSMVFCid59 VFCVectorEGSMVFCid6 VFCVectorEGSMVFCid60 VFCVectorEGSMVFCid61 VFCVectorEGSMVFCid7 VFCVectorEGSMVFCid8 VFCVectorEGSMVFCid9;
SIG_GROUP_ 1376 VFCVectorXCU 1 : VFCVectorXCUBlockID VFCVectorXCUVFCid0 VFCVectorXCUVFCid1 VFCVectorXCUVFCid10 VFCVectorXCUVFCid11 VFCVectorXCUVFCid12 VFCVectorXCUVFCid13 VFCVectorXCUVFCid14 VFCVectorXCUVFCid15 VFCVectorXCUVFCid16 VFCVectorXCUVFCid17 VFCVectorXCUVFCid18 VFCVectorXCUVFCid19 VFCVectorXCUVFCid2 VFCVectorXCUVFCid20 VFCVectorXCUVFCid21 VFCVectorXCUVFCid22 VFCVectorXCUVFCid23 VFCVectorXCUVFCid24 VFCVectorXCUVFCid25 VFCVectorXCUVFCid26 VFCVectorXCUVFCid27 VFCVectorXCUVFCid28 VFCVectorXCUVFCid29 VFCVectorXCUVFCid3 VFCVectorXCUVFCid30 VFCVectorXCUVFCid31 VFCVectorXCUVFCid32 VFCVectorXCUVFCid33 VFCVectorXCUVFCid34 VFCVectorXCUVFCid35 VFCVectorXCUVFCid36 VFCVectorXCUVFCid37 VFCVectorXCUVFCid38 VFCVectorXCUVFCid39 VFCVectorXCUVFCid4 VFCVectorXCUVFCid40 VFCVectorXCUVFCid41 VFCVectorXCUVFCid42 VFCVectorXCUVFCid43 VFCVectorXCUVFCid44 VFCVectorXCUVFCid45 VFCVectorXCUVFCid46 VFCVectorXCUVFCid47 VFCVectorXCUVFCid48 VFCVectorXCUVFCid49 VFCVectorXCUVFCid5 VFCVectorXCUVFCid50 VFCVectorXCUVFCid51 VFCVectorXCUVFCid52 VFCVectorXCUVFCid53 VFCVectorXCUVFCid54 VFCVectorXCUVFCid55 VFCVectorXCUVFCid56 VFCVectorXCUVFCid57 VFCVectorXCUVFCid58 VFCVectorXCUVFCid59 VFCVectorXCUVFCid6 VFCVectorXCUVFCid60 VFCVectorXCUVFCid61 VFCVectorXCUVFCid7 VFCVectorXCUVFCid8 VFCVectorXCUVFCid9;
SIG_GROUP_ 1349 VFCVectorZCUDM 1 : VFCVectorZCUDMBlockID VFCVectorZCUDMVFCid0 VFCVectorZCUDMVFCid1 VFCVectorZCUDMVFCid10 VFCVectorZCUDMVFCid11 VFCVectorZCUDMVFCid12 VFCVectorZCUDMVFCid13 VFCVectorZCUDMVFCid14 VFCVectorZCUDMVFCid15 VFCVectorZCUDMVFCid16 VFCVectorZCUDMVFCid17 VFCVectorZCUDMVFCid18 VFCVectorZCUDMVFCid19 VFCVectorZCUDMVFCid2 VFCVectorZCUDMVFCid20 VFCVectorZCUDMVFCid21 VFCVectorZCUDMVFCid22 VFCVectorZCUDMVFCid23 VFCVectorZCUDMVFCid24 VFCVectorZCUDMVFCid25 VFCVectorZCUDMVFCid26 VFCVectorZCUDMVFCid27 VFCVectorZCUDMVFCid28 VFCVectorZCUDMVFCid29 VFCVectorZCUDMVFCid3 VFCVectorZCUDMVFCid30 VFCVectorZCUDMVFCid31 VFCVectorZCUDMVFCid32 VFCVectorZCUDMVFCid33 VFCVectorZCUDMVFCid34 VFCVectorZCUDMVFCid35 VFCVectorZCUDMVFCid36 VFCVectorZCUDMVFCid37 VFCVectorZCUDMVFCid38 VFCVectorZCUDMVFCid39 VFCVectorZCUDMVFCid4 VFCVectorZCUDMVFCid40 VFCVectorZCUDMVFCid41 VFCVectorZCUDMVFCid42 VFCVectorZCUDMVFCid43 VFCVectorZCUDMVFCid44 VFCVectorZCUDMVFCid45 VFCVectorZCUDMVFCid46 VFCVectorZCUDMVFCid47 VFCVectorZCUDMVFCid48 VFCVectorZCUDMVFCid49 VFCVectorZCUDMVFCid5 VFCVectorZCUDMVFCid50 VFCVectorZCUDMVFCid51 VFCVectorZCUDMVFCid52 VFCVectorZCUDMVFCid53 VFCVectorZCUDMVFCid54 VFCVectorZCUDMVFCid55 VFCVectorZCUDMVFCid56 VFCVectorZCUDMVFCid57 VFCVectorZCUDMVFCid58 VFCVectorZCUDMVFCid59 VFCVectorZCUDMVFCid6 VFCVectorZCUDMVFCid60 VFCVectorZCUDMVFCid61 VFCVectorZCUDMVFCid7 VFCVectorZCUDMVFCid8 VFCVectorZCUDMVFCid9;
SIG_GROUP_ 1143 Vin 1 : VinBlockNr VinVINSignalPos1 VinVINSignalPos2 VinVINSignalPos3 VinVINSignalPos4 VinVINSignalPos5 VinVINSignalPos6 VinVINSignalPos7;
